VERSION "10.9.1"

NS_ :

BS_:

BU_: ADAS_Info AMP CPD DUMMY_DEBUG DUMMY_ECU EASC HUD MHU XGW_Info

BO_ 852 MHU_ADAS_req: 8 MHU
  SG_ MHU_FCW_Mode : 1|2@0+ (1,0) [0|3] "-" ADAS_Info
  SG_ MHU_FCW_sens : 3|2@0+ (1,0) [0|3] "-" ADAS_Info
  SG_ MHU_AEB_Mode : 7|2@0+ (1,0) [0|3] "-" ADAS_Info
  SG_ MHU_RAEB_Mode : 9|2@0+ (1,0) [0|3] "-" ADAS_Info
  SG_ MHU_LA_sens : 11|2@0+ (1,0) [0|3] "-" ADAS_Info
  SG_ MHU_LA_AudWarning : 15|2@0+ (1,0) [0|3] "-" ADAS_Info
  SG_ MHU_BSD_On : 17|2@0+ (1,0) [0|3] "-" ADAS_Info
  SG_ MHU_ALC_ON : 19|2@0+ (1,0) [0|3] "-" ADAS_Info
  SG_ MHU_BSD_AudWarning : 21|2@0+ (1,0) [0|3] "-" ADAS_Info
  SG_ MHU_RCTA_On : 23|2@0+ (1,0) [0|3] "-" ADAS_Info
  SG_ MHU_RCTA_sens : 25|2@0+ (1,0) [0|3] "-" ADAS_Info
  SG_ MHU_PA_On : 27|2@0+ (1,0) [0|3] "-" ADAS_Info
  SG_ MHU_AHB_On : 29|2@0+ (1,0) [0|3] "-" ADAS_Info
  SG_ MHU_IA_Mode : 31|2@0+ (1,0) [0|3] "-" ADAS_Info
  SG_ MHU_TSR_Mode : 33|2@0+ (1,0) [0|3] "-" ADAS_Info
  SG_ MHU_DOW_Mode : 35|2@0+ (1,0) [0|3] "-" ADAS_Info
  SG_ MHU_AHB_sens : 37|2@0+ (1,0) [0|3] "-" ADAS_Info
  SG_ MHU_LA_Mode : 41|3@0+ (1,0) [0|7] "-" ADAS_Info
  SG_ MHU_SET_TSR_AudWarn : 45|2@0+ (1,0) [0|3] "-" ADAS_Info
  SG_ MHU_SET_TSR_SLAert : 47|2@0+ (1,0) [0|3] "-" ADAS_Info

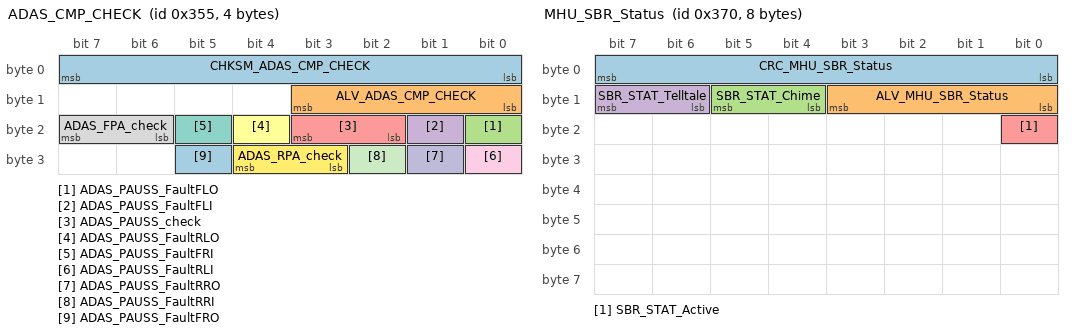
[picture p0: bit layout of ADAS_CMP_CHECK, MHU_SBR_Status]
BO_ 853 ADAS_CMP_CHECK: 4 ADAS_Info
  SG_ CHKSM_ADAS_CMP_CHECK : 7|8@0+ (1,0) [0|255] "" MHU
  SG_ ALV_ADAS_CMP_CHECK : 11|4@0+ (1,0) [0|14] "" MHU
  SG_ ADAS_PAUSS_FaultFLO : 16|1@0+ (1,0) [0|1] "-" MHU
  SG_ ADAS_PAUSS_FaultFLI : 17|1@0+ (1,0) [0|1] "-" MHU
  SG_ ADAS_PAUSS_check : 19|2@0+ (1,0) [0|3] "-" MHU
  SG_ ADAS_PAUSS_FaultRLO : 20|1@0+ (1,0) [0|1] "-" MHU
  SG_ ADAS_PAUSS_FaultFRI : 21|1@0+ (1,0) [0|1] "-" MHU
  SG_ ADAS_FPA_check : 23|2@0+ (1,0) [0|3] "-" MHU
  SG_ ADAS_PAUSS_FaultRLI : 24|1@0+ (1,0) [0|1] "-" MHU
  SG_ ADAS_PAUSS_FaultRRO : 25|1@0+ (1,0) [0|1] "-" MHU
  SG_ ADAS_PAUSS_FaultRRI : 26|1@0+ (1,0) [0|1] "-" MHU
  SG_ ADAS_RPA_check : 28|2@0+ (1,0) [0|3] "-" MHU
  SG_ ADAS_PAUSS_FaultFRO : 29|1@0+ (1,0) [0|1] "-" MHU

BO_ 880 MHU_SBR_Status: 8 MHU
  SG_ CRC_MHU_SBR_Status : 7|8@0+ (1,0) [0|255] "" XGW_Info
  SG_ ALV_MHU_SBR_Status : 11|4@0+ (1,0) [0|14] "" XGW_Info
  SG_ SBR_STAT_Chime : 13|2@0+ (1,0) [0|3] "" XGW_Info
  SG_ SBR_STAT_Telltale : 15|2@0+ (1,0) [0|3] "" XGW_Info
  SG_ SBR_STAT_Active : 16|1@0+ (1,0) [0|1] "" XGW_Info

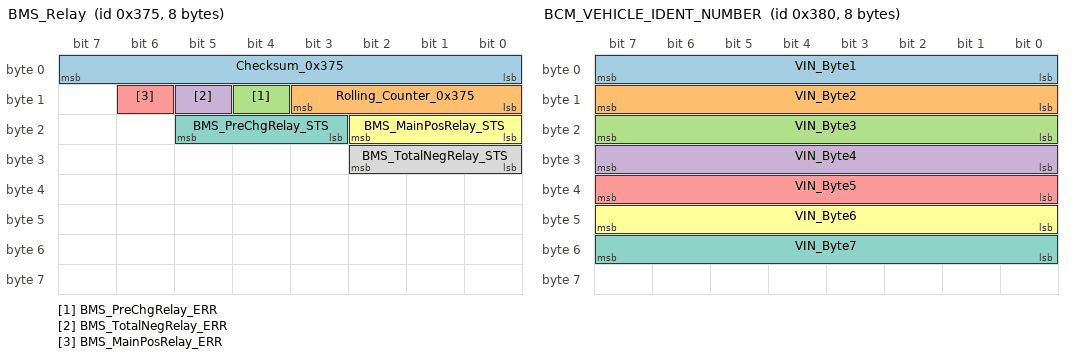
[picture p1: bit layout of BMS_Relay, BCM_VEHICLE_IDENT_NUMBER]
BO_ 885 BMS_Relay: 8 XGW_Info
  SG_ Checksum_0x375 : 7|8@0+ (1,0) [0|255] "" MHU
  SG_ Rolling_Counter_0x375 : 11|4@0+ (1,0) [0|14] "" MHU
  SG_ BMS_PreChgRelay_ERR : 12|1@0+ (1,0) [0|1] "" MHU
  SG_ BMS_TotalNegRelay_ERR : 13|1@0+ (1,0) [0|1] "" MHU
  SG_ BMS_MainPosRelay_ERR : 14|1@0+ (1,0) [0|1] "" MHU
  SG_ BMS_MainPosRelay_STS : 18|3@0+ (1,0) [0|7] "" MHU
  SG_ BMS_PreChgRelay_STS : 21|3@0+ (1,0) [0|7] "" MHU
  SG_ BMS_TotalNegRelay_STS : 26|3@0+ (1,0) [0|7] "" MHU

BO_ 896 BCM_VEHICLE_IDENT_NUMBER: 8 XGW_Info
  SG_ VIN_Byte1 : 7|8@0+ (1,0) [0|255] "" ADAS_Info,AMP,CPD,EASC,HUD,MHU
  SG_ VIN_Byte2 : 15|8@0+ (1,0) [0|255] "" ADAS_Info,AMP,CPD,EASC,HUD,MHU
  SG_ VIN_Byte3 : 23|8@0+ (1,0) [0|255] "" ADAS_Info,AMP,CPD,EASC,HUD,MHU
  SG_ VIN_Byte4 : 31|8@0+ (1,0) [0|255] "" ADAS_Info,AMP,CPD,EASC,HUD,MHU
  SG_ VIN_Byte5 : 39|8@0+ (1,0) [0|255] "" ADAS_Info,AMP,CPD,EASC,HUD,MHU
  SG_ VIN_Byte6 : 47|8@0+ (1,0) [0|255] "" ADAS_Info,AMP,CPD,EASC,HUD,MHU
  SG_ VIN_Byte7 : 55|8@0+ (1,0) [0|255] "" ADAS_Info,AMP,CPD,EASC,HUD,MHU

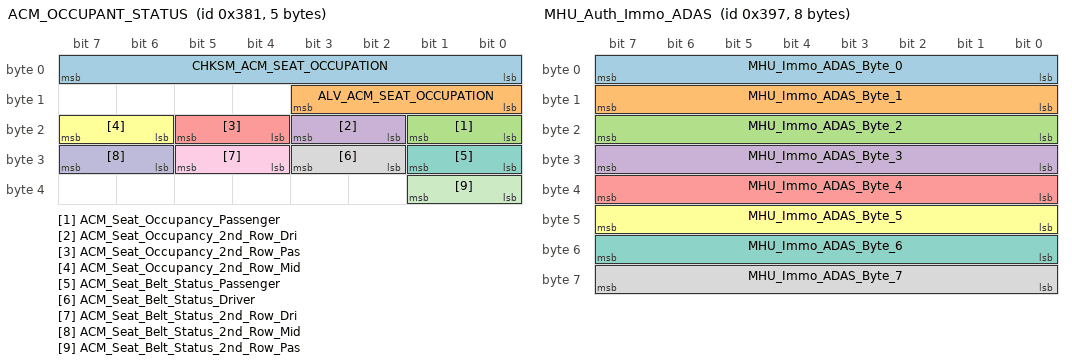
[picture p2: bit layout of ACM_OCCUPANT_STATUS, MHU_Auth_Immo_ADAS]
BO_ 897 ACM_OCCUPANT_STATUS: 5 XGW_Info
  SG_ CHKSM_ACM_SEAT_OCCUPATION : 7|8@0+ (1,0) [0|255] "" MHU
  SG_ ALV_ACM_SEAT_OCCUPATION : 11|4@0+ (1,0) [0|14] "" MHU
  SG_ ACM_Seat_Occupancy_Passenger : 17|2@0+ (1,0) [0|3] "" MHU
  SG_ ACM_Seat_Occupancy_2nd_Row_Dri : 19|2@0+ (1,0) [0|3] "" MHU
  SG_ ACM_Seat_Occupancy_2nd_Row_Pas : 21|2@0+ (1,0) [0|3] "-" MHU
  SG_ ACM_Seat_Occupancy_2nd_Row_Mid : 23|2@0+ (1,0) [0|3] "-" MHU
  SG_ ACM_Seat_Belt_Status_Passenger : 25|2@0+ (1,0) [0|3] "" MHU
  SG_ ACM_Seat_Belt_Status_Driver : 27|2@0+ (1,0) [0|3] "" MHU
  SG_ ACM_Seat_Belt_Status_2nd_Row_Dri : 29|2@0+ (1,0) [0|3] "-" MHU
  SG_ ACM_Seat_Belt_Status_2nd_Row_Mid : 31|2@0+ (1,0) [0|3] "" MHU
  SG_ ACM_Seat_Belt_Status_2nd_Row_Pas : 33|2@0+ (1,0) [0|3] "-" MHU

BO_ 905 VCU_Sts3: 8 XGW_Info
  SG_ VCU_IMMO_Sts : 35|2@0+ (1,0) [0|3] "" MHU
  SG_ SECCAN_VCU_IMMO_Sts : 63|8@0+ (1,0) [0|255] "" Vector__XXX

BO_ 915 MHU_HudPositionSetting: 3 MHU
  SG_ MHU_SET_HudRotateLvl : 7|4@0+ (1,0) [0|15] "-" HUD
  SG_ MHU_SET_HudHeightLvl : 15|5@0+ (1,0) [0|31] "-" HUD

BO_ 919 MHU_Auth_Immo_ADAS: 8 MHU
  SG_ MHU_Immo_ADAS_Byte_0 : 7|8@0+ (1,0) [0|255] "-" ADAS_Info
  SG_ MHU_Immo_ADAS_Byte_1 : 15|8@0+ (1,0) [0|255] "-" ADAS_Info
  SG_ MHU_Immo_ADAS_Byte_2 : 23|8@0+ (1,0) [0|255] "-" ADAS_Info
  SG_ MHU_Immo_ADAS_Byte_3 : 31|8@0+ (1,0) [0|255] "-" ADAS_Info
  SG_ MHU_Immo_ADAS_Byte_4 : 39|8@0+ (1,0) [0|255] "-" ADAS_Info
  SG_ MHU_Immo_ADAS_Byte_5 : 47|8@0+ (1,0) [0|255] "-" ADAS_Info
  SG_ MHU_Immo_ADAS_Byte_6 : 55|8@0+ (1,0) [0|255] "-" ADAS_Info
  SG_ MHU_Immo_ADAS_Byte_7 : 63|8@0+ (1,0) [0|255] "-" ADAS_Info

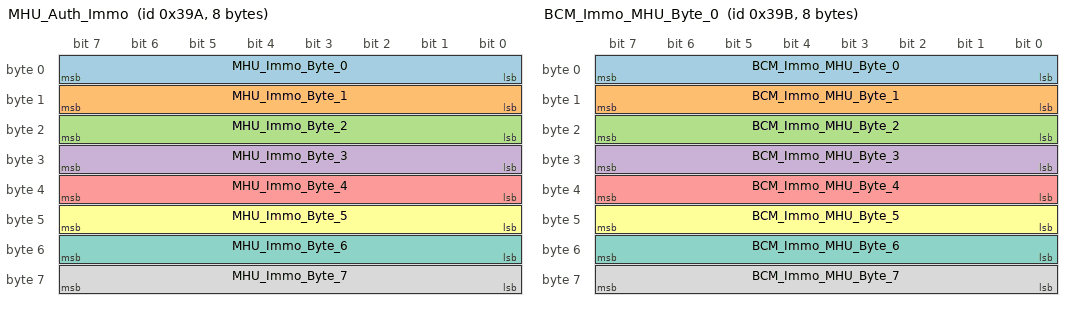
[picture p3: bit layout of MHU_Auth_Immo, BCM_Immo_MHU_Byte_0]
BO_ 922 MHU_Auth_Immo: 8 MHU
  SG_ MHU_Immo_Byte_0 : 7|8@0+ (1,0) [0|255] "-" XGW_Info
  SG_ MHU_Immo_Byte_1 : 15|8@0+ (1,0) [0|255] "-" XGW_Info
  SG_ MHU_Immo_Byte_2 : 23|8@0+ (1,0) [0|255] "" XGW_Info
  SG_ MHU_Immo_Byte_3 : 31|8@0+ (1,0) [0|255] "" XGW_Info
  SG_ MHU_Immo_Byte_4 : 39|8@0+ (1,0) [0|255] "" XGW_Info
  SG_ MHU_Immo_Byte_5 : 47|8@0+ (1,0) [0|255] "" XGW_Info
  SG_ MHU_Immo_Byte_6 : 55|8@0+ (1,0) [0|255] "" XGW_Info
  SG_ MHU_Immo_Byte_7 : 63|8@0+ (1,0) [0|255] "-" XGW_Info

BO_ 923 BCM_Immo_MHU_Byte_0: 8 XGW_Info
  SG_ BCM_Immo_MHU_Byte_0 : 7|8@0+ (1,0) [0|255] "-" MHU
  SG_ BCM_Immo_MHU_Byte_1 : 15|8@0+ (1,0) [0|255] "-" MHU
  SG_ BCM_Immo_MHU_Byte_2 : 23|8@0+ (1,0) [0|255] "-" MHU
  SG_ BCM_Immo_MHU_Byte_3 : 31|8@0+ (1,0) [0|255] "-" MHU
  SG_ BCM_Immo_MHU_Byte_4 : 39|8@0+ (1,0) [0|255] "-" MHU
  SG_ BCM_Immo_MHU_Byte_5 : 47|8@0+ (1,0) [0|255] "" MHU
  SG_ BCM_Immo_MHU_Byte_6 : 55|8@0+ (1,0) [0|255] "-" MHU
  SG_ BCM_Immo_MHU_Byte_7 : 63|8@0+ (1,0) [0|255] "-" MHU

BO_ 925 BCM_HighBeam_PosReq: 4 XGW_Info
  SG_ BCM_AHB_Override : 17|2@0+ (1,0) [0|3] "" MHU

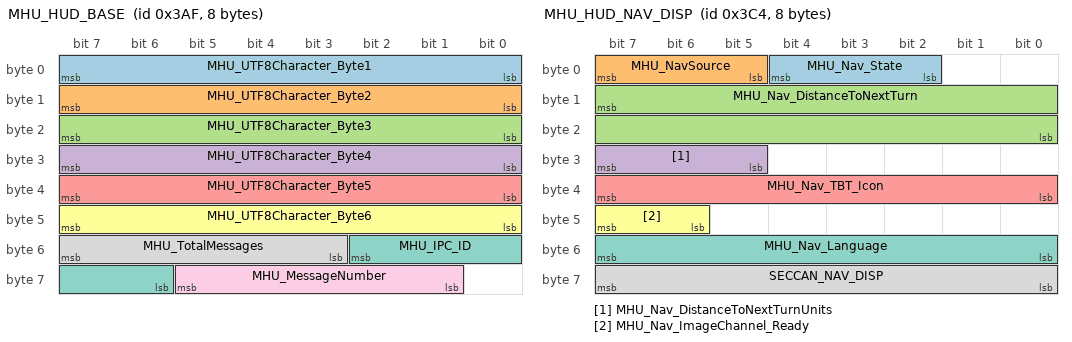
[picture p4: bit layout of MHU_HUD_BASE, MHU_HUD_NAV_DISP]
BO_ 943 MHU_HUD_BASE: 8 MHU
  SG_ MHU_UTF8Character_Byte1 : 7|8@0+ (1,0) [0|255] "-" HUD
  SG_ MHU_UTF8Character_Byte2 : 15|8@0+ (1,0) [0|255] "-" HUD
  SG_ MHU_UTF8Character_Byte3 : 23|8@0+ (1,0) [0|255] "-" HUD
  SG_ MHU_UTF8Character_Byte4 : 31|8@0+ (1,0) [0|255] "-" HUD
  SG_ MHU_UTF8Character_Byte5 : 39|8@0+ (1,0) [0|255] "-" HUD
  SG_ MHU_UTF8Character_Byte6 : 47|8@0+ (1,0) [0|255] "-" HUD
  SG_ MHU_IPC_ID : 50|5@0+ (1,0) [0|15] "Bit" HUD
  SG_ MHU_TotalMessages : 55|5@0+ (1,0) [0|31] "-" HUD
  SG_ MHU_MessageNumber : 61|5@0+ (1,0) [0|31] "-" HUD

BO_ 964 MHU_HUD_NAV_DISP: 8 MHU
  SG_ MHU_Nav_State : 4|3@0+ (1,0) [0|7] "-" HUD
  SG_ MHU_NavSource : 7|3@0+ (1,0) [0|7] "-" HUD
  SG_ MHU_Nav_DistanceToNextTurn : 15|16@0+ (1,0) [0|65535] "-" HUD
  SG_ MHU_Nav_DistanceToNextTurnUnits : 31|3@0+ (1,0) [0|7] "-" HUD
  SG_ MHU_Nav_TBT_Icon : 39|8@0+ (1,0) [0|255] "-" HUD
  SG_ MHU_Nav_ImageChannel_Ready : 47|2@0+ (1,0) [0|3] "-" HUD
  SG_ MHU_Nav_Language : 55|8@0+ (1,0) [0|255] "" HUD
  SG_ SECCAN_NAV_DISP : 63|8@0+ (1,0) [0|255] "" HUD

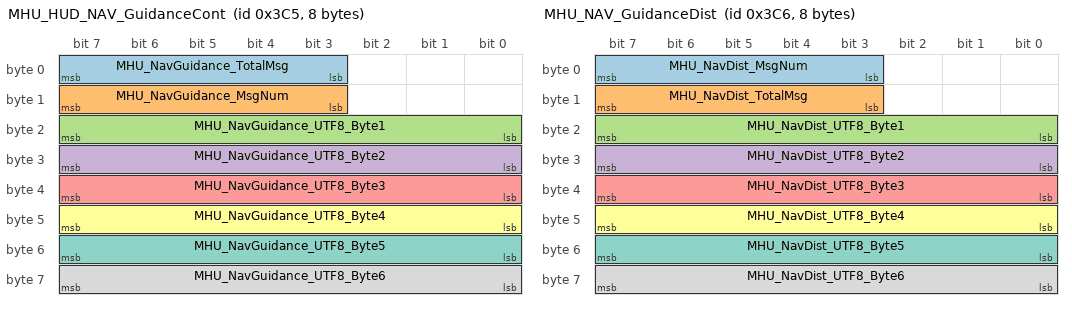
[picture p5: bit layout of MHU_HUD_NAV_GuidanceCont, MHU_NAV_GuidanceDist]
BO_ 965 MHU_HUD_NAV_GuidanceCont: 8 MHU
  SG_ MHU_NavGuidance_TotalMsg : 7|5@0+ (1,0) [0|31] "-" HUD
  SG_ MHU_NavGuidance_MsgNum : 15|5@0+ (1,0) [0|31] "-" HUD
  SG_ MHU_NavGuidance_UTF8_Byte1 : 23|8@0+ (1,0) [0|255] "" HUD
  SG_ MHU_NavGuidance_UTF8_Byte2 : 31|8@0+ (1,0) [0|255] "" HUD
  SG_ MHU_NavGuidance_UTF8_Byte3 : 39|8@0+ (1,0) [0|255] "" HUD
  SG_ MHU_NavGuidance_UTF8_Byte4 : 47|8@0+ (1,0) [0|255] "" HUD
  SG_ MHU_NavGuidance_UTF8_Byte5 : 55|8@0+ (1,0) [0|255] "" HUD
  SG_ MHU_NavGuidance_UTF8_Byte6 : 63|8@0+ (1,0) [0|255] "" HUD

BO_ 966 MHU_NAV_GuidanceDist: 8 MHU
  SG_ MHU_NavDist_MsgNum : 7|5@0+ (1,0) [0|31] "" HUD
  SG_ MHU_NavDist_TotalMsg : 15|5@0+ (1,0) [0|31] "" HUD
  SG_ MHU_NavDist_UTF8_Byte1 : 23|8@0+ (1,0) [0|255] "" HUD
  SG_ MHU_NavDist_UTF8_Byte2 : 31|8@0+ (1,0) [0|255] "" HUD
  SG_ MHU_NavDist_UTF8_Byte3 : 39|8@0+ (1,0) [0|255] "" HUD
  SG_ MHU_NavDist_UTF8_Byte4 : 47|8@0+ (1,0) [0|255] "" HUD
  SG_ MHU_NavDist_UTF8_Byte5 : 55|8@0+ (1,0) [0|255] "" HUD
  SG_ MHU_NavDist_UTF8_Byte6 : 63|8@0+ (1,0) [0|255] "" HUD

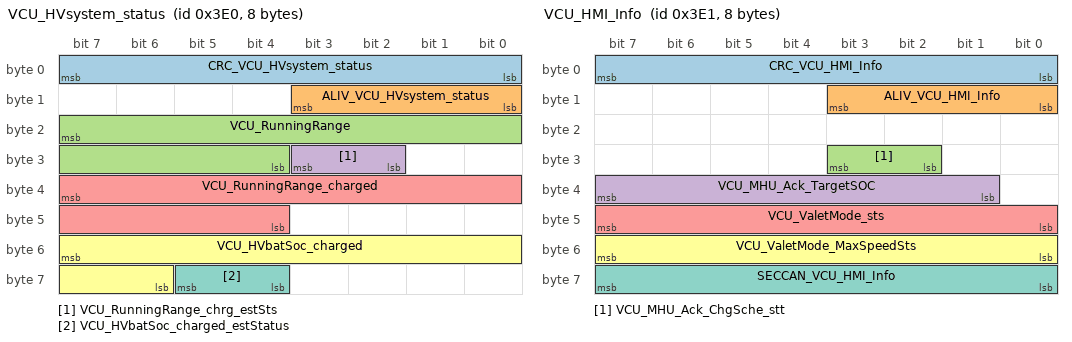
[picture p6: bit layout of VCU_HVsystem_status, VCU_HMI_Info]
BO_ 992 VCU_HVsystem_status: 8 XGW_Info
  SG_ CRC_VCU_HVsystem_status : 7|8@0+ (1,0) [0|255] "" HUD,MHU
  SG_ ALIV_VCU_HVsystem_status : 11|4@0+ (1,0) [0|14] "" HUD,MHU
  SG_ VCU_RunningRange : 23|12@0+ (0.5,0) [0|2047] "km" HUD,MHU
  SG_ VCU_RunningRange_chrg_estSts : 27|2@0+ (1,0) [0|3] "-" HUD,MHU
  SG_ VCU_RunningRange_charged : 39|12@0+ (0.5,0) [0|2047] "km" HUD,MHU
  SG_ VCU_HVbatSoc_charged : 55|10@0+ (0.1,0) [0|100] "%" HUD,MHU
  SG_ VCU_HVbatSoc_charged_estStatus : 61|2@0+ (1,0) [0|3] "-" HUD,MHU

BO_ 993 VCU_HMI_Info: 8 XGW_Info
  SG_ CRC_VCU_HMI_Info : 7|8@0+ (1,0) [0|255] "" MHU
  SG_ ALIV_VCU_HMI_Info : 11|4@0+ (1,0) [0|14] "" MHU
  SG_ VCU_MHU_Ack_ChgSche_stt : 27|2@0+ (1,0) [0|3] "" MHU
  SG_ VCU_MHU_Ack_TargetSOC : 39|7@0+ (1,0) [10|100] "%" MHU
  SG_ VCU_ValetMode_sts : 47|8@0+ (1,0) [0|255] "" MHU
  SG_ VCU_ValetMode_MaxSpeedSts : 55|8@0+ (1,0) [0|255] "km/h" MHU
  SG_ SECCAN_VCU_HMI_Info : 63|8@0+ (1,0) [0|255] "" MHU

BO_ 1015 MFS_Control_Button: 8 XGW_Info
  SG_ CHSKM_MFS_Control_Button : 7|8@0+ (1,0) [0|255] "" ADAS_Info,HUD,MHU
  SG_ ALV_MFS_Control_Button : 11|4@0+ (1,0) [0|14] "" ADAS_Info,HUD,MHU
  SG_ MFS_VoiceRecognitionOn_Off : 15|3@0+ (1,0) [0|4] "Bit" HUD,MHU
  SG_ MFS_ISAControl : 17|2@0+ (1,0) [0|3] "Bit" ADAS_Info,HUD,MHU
  SG_ MFS_CruiseSpeedIncrease : 20|3@0+ (1,0) [0|4] "Bit" ADAS_Info,HUD,MHU
  SG_ MFS_TelephoneCall_EndCall : 23|3@0+ (1,0) [0|4] "Bit" HUD,MHU
  SG_ MFS_LKAControl : 25|2@0+ (1,0) [0|3] "Bit" ADAS_Info,HUD,MHU
  SG_ MFS_CruiseGapIncrease : 28|3@0+ (1,0) [0|4] "Bit" ADAS_Info,HUD,MHU
  SG_ MFS_CruiseOn_Off : 31|3@0+ (1,0) [0|4] "Bit" ADAS_Info,HUD,MHU
  SG_ MFS_CruiseGapDecrease : 34|3@0+ (1,0) [0|4] "Bit" ADAS_Info,HUD,MHU
  SG_ MFS_CAN_RESControl : 36|2@0+ (1,0) [0|3] "-" ADAS_Info,HUD
  SG_ MFS_CruiseSpeedDecrease : 39|3@0+ (1,0) [0|4] "Bit" ADAS_Info,HUD,MHU
  SG_ MFS_M2Control : 41|2@0+ (1,0) [0|3] "Bit" ADAS_Info,HUD
  SG_ MFS_SourseControl : 44|3@0+ (1,0) [0|4] "Bit" HUD,MHU
  SG_ MFS_UpControl : 47|3@0+ (1,0) [0|4] "Bit" EASC,HUD,MHU
  SG_ MFS_DownControl : 52|3@0+ (1,0) [0|4] "Bit" EASC,HUD,MHU
  SG_ MFS_LeftControl : 55|3@0+ (1,0) [0|4] "Bit" EASC,HUD,MHU
  SG_ MFS_Failure : 57|1@0+ (1,0) [0|1] "Bit" ADAS_Info,HUD,MHU
  SG_ MFS_RightControl : 60|3@0+ (1,0) [0|4] "Bit" EASC,HUD,MHU
  SG_ MFS_OK_Control : 63|3@0+ (1,0) [0|4] "Bit" HUD,MHU

BO_ 1020 XGW_FOTA_StsConfirm: 4 XGW_Info
  SG_ CRC_XGW_FOTA_StsConfirm : 7|8@0+ (1,0) [0|255] "" MHU
  SG_ ALIV_XGW_FOTA_StsConfirm : 11|4@0+ (1,0) [0|14] "" MHU
  SG_ XGW_FOTA_StateConfirm : 15|4@0+ (1,0) [0|14] "-" MHU
  SG_ XGW_FOTA_Error_Code : 23|8@0+ (1,0) [0|255] "-" MHU

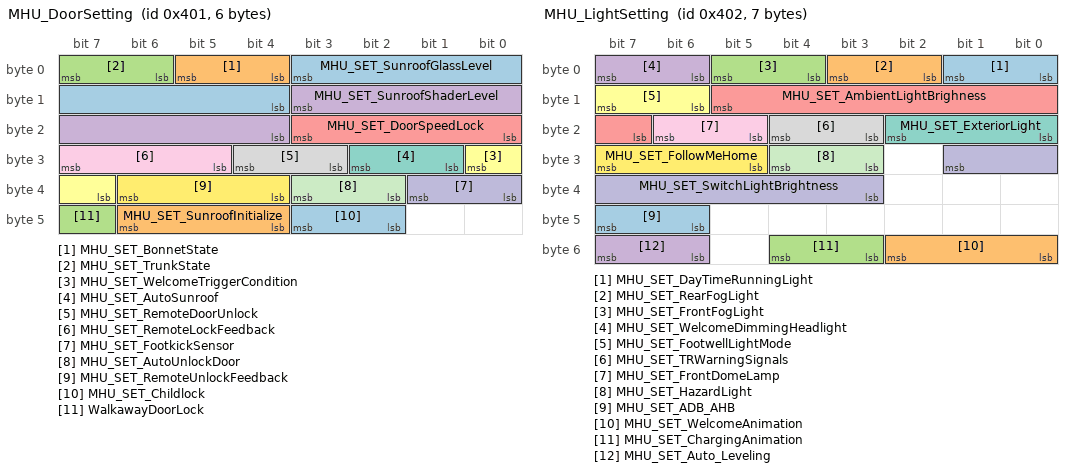
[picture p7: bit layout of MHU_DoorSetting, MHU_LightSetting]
BO_ 1025 MHU_DoorSetting: 6 MHU
  SG_ MHU_SET_SunroofGlassLevel : 3|8@0+ (1,0) [0|255] "%" XGW_Info
  SG_ MHU_SET_BonnetState : 5|2@0+ (1,0) [0|3] "-" XGW_Info
  SG_ MHU_SET_TrunkState : 7|2@0+ (1,0) [0|3] "-" XGW_Info
  SG_ MHU_SET_SunroofShaderLevel : 11|8@0+ (1,0) [0|255] "%" XGW_Info
  SG_ MHU_SET_DoorSpeedLock : 19|4@0+ (1,0) [0|7] "" XGW_Info
  SG_ MHU_SET_WelcomeTriggerCondition : 24|2@0+ (1,0) [0|3] "" XGW_Info
  SG_ MHU_SET_AutoSunroof : 26|2@0+ (1,0) [0|3] "" XGW_Info
  SG_ MHU_SET_RemoteDoorUnlock : 28|2@0+ (1,0) [0|3] "-" XGW_Info
  SG_ MHU_SET_RemoteLockFeedback : 31|3@0+ (1,0) [0|7] "-" XGW_Info
  SG_ MHU_SET_FootkickSensor : 33|2@0+ (1,0) [0|3] "-" XGW_Info
  SG_ MHU_SET_AutoUnlockDoor : 35|2@0+ (1,0) [0|3] "" XGW_Info
  SG_ MHU_SET_RemoteUnlockFeedback : 38|3@0+ (1,0) [0|7] "" XGW_Info
  SG_ MHU_SET_Childlock : 43|2@0+ (1,0) [0|3] "" XGW_Info
  SG_ MHU_SET_SunroofInitialize : 46|3@0+ (1,0) [0|7] "" XGW_Info
  SG_ WalkawayDoorLock : 47|1@0+ (1,0) [0|1] "" XGW_Info

BO_ 1026 MHU_LightSetting: 7 MHU
  SG_ MHU_SET_DayTimeRunningLight : 1|2@0+ (1,0) [0|3] "-" XGW_Info
  SG_ MHU_SET_RearFogLight : 3|2@0+ (1,0) [0|3] "" XGW_Info
  SG_ MHU_SET_FrontFogLight : 5|2@0+ (1,0) [0|3] "" XGW_Info
  SG_ MHU_SET_WelcomeDimmingHeadlight : 7|2@0+ (1,0) [0|3] "" XGW_Info
  SG_ MHU_SET_AmbientLightBrighness : 13|7@0+ (1,0) [0|100] "%" XGW_Info
  SG_ MHU_SET_FootwellLightMode : 15|2@0+ (1,0) [0|3] "-" XGW_Info
  SG_ MHU_SET_ExteriorLight : 18|3@0+ (1,0) [0|7] "" XGW_Info
  SG_ MHU_SET_TRWarningSignals : 20|2@0+ (1,0) [0|3] "" XGW_Info
  SG_ MHU_SET_FrontDomeLamp : 22|2@0+ (1,0) [0|3] "" XGW_Info
  SG_ MHU_SET_SwitchLightBrightness : 25|7@0+ (1,0) [0|100] "%" XGW_Info
  SG_ MHU_SET_HazardLight : 28|2@0+ (1,0) [0|3] "" XGW_Info
  SG_ MHU_SET_FollowMeHome : 31|3@0+ (1,0) [0|7] "" XGW_Info
  SG_ MHU_SET_ADB_AHB : 47|2@0+ (1,0) [0|3] "" XGW_Info
  SG_ MHU_SET_WelcomeAnimation : 50|3@0+ (1,0) [0|5] "" XGW_Info
  SG_ MHU_SET_ChargingAnimation : 52|2@0+ (1,0) [0|3] "" XGW_Info
  SG_ MHU_SET_Auto_Leveling : 55|2@0+ (1,0) [0|3] "-" XGW_Info

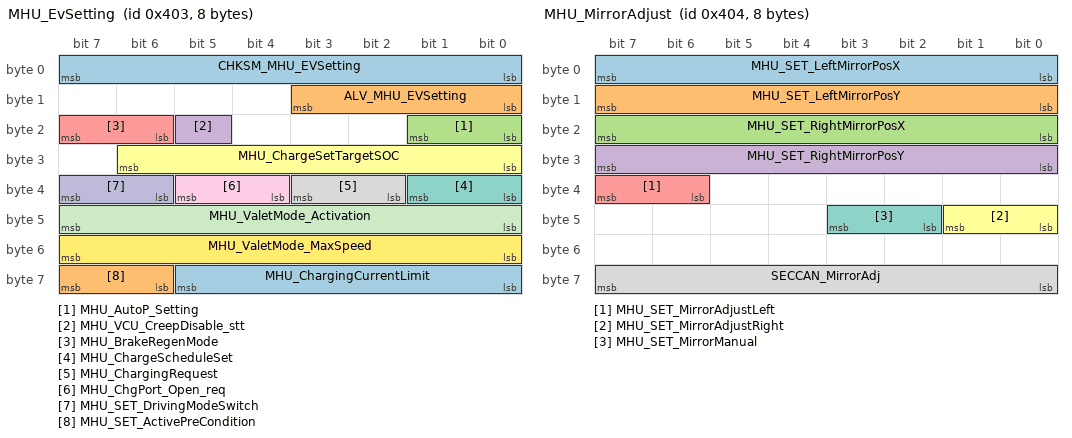
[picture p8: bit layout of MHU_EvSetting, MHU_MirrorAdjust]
BO_ 1027 MHU_EvSetting: 8 MHU
  SG_ CHKSM_MHU_EVSetting : 7|8@0+ (1,0) [0|255] "" XGW_Info
  SG_ ALV_MHU_EVSetting : 11|4@0+ (1,0) [0|14] "" XGW_Info
  SG_ MHU_AutoP_Setting : 17|2@0+ (1,0) [0|3] "" XGW_Info
  SG_ MHU_VCU_CreepDisable_stt : 21|1@0+ (1,0) [0|1] "" XGW_Info
  SG_ MHU_BrakeRegenMode : 23|2@0+ (1,0) [0|3] "" XGW_Info
  SG_ MHU_ChargeSetTargetSOC : 30|7@0+ (1,0) [10|100] "%" XGW_Info
  SG_ MHU_ChargeScheduleSet : 33|2@0+ (1,0) [0|3] "" XGW_Info
  SG_ MHU_ChargingRequest : 35|2@0+ (1,0) [0|3] "-" XGW_Info
  SG_ MHU_ChgPort_Open_req : 37|2@0+ (1,0) [0|3] "-" XGW_Info
  SG_ MHU_SET_DrivingModeSwitch : 39|2@0+ (1,0) [0|3] "-" XGW_Info
  SG_ MHU_ValetMode_Activation : 47|8@0+ (1,0) [0|255] "" ADAS_Info,XGW_Info
  SG_ MHU_ValetMode_MaxSpeed : 55|8@0+ (1,0) [0|255] "km/h" XGW_Info
  SG_ MHU_ChargingCurrentLimit : 61|6@0+ (1,0) [0|63] "A" XGW_Info
  SG_ MHU_SET_ActivePreCondition : 63|2@0+ (1,0) [0|3] "" XGW_Info

BO_ 1028 MHU_MirrorAdjust: 8 MHU
  SG_ MHU_SET_LeftMirrorPosX : 7|8@0+ (1,-15) [-15|15] "deg" XGW_Info
  SG_ MHU_SET_LeftMirrorPosY : 15|8@0+ (1,-15) [-15|15] "deg" XGW_Info
  SG_ MHU_SET_RightMirrorPosX : 23|8@0+ (1,-15) [-15|15] "deg" XGW_Info
  SG_ MHU_SET_RightMirrorPosY : 31|8@0+ (1,-15) [-15|15] "deg" XGW_Info
  SG_ MHU_SET_MirrorAdjustLeft : 39|2@0+ (1,0) [0|3] "-" XGW_Info
  SG_ MHU_SET_MirrorAdjustRight : 41|2@0+ (1,0) [0|3] "-" XGW_Info
  SG_ MHU_SET_MirrorManual : 43|2@0+ (1,0) [0|3] "" XGW_Info
  SG_ SECCAN_MirrorAdj : 63|8@0+ (1,0) [0|255] "" XGW_Info

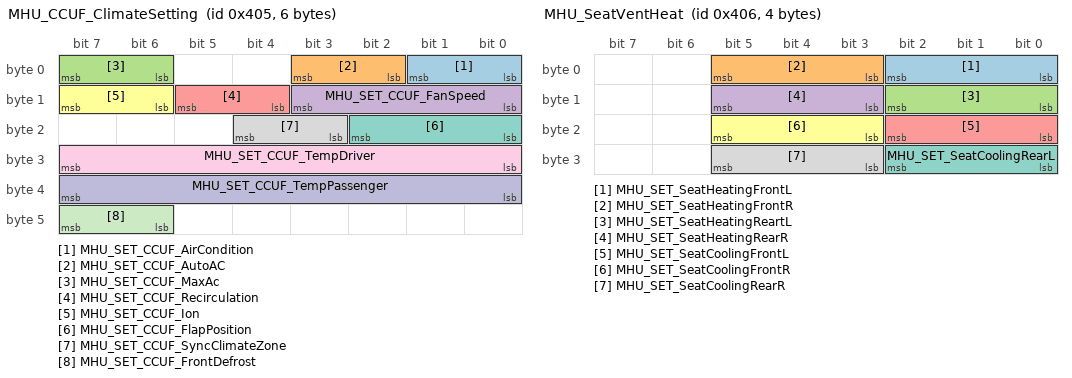
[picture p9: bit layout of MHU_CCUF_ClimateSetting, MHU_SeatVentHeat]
BO_ 1029 MHU_CCUF_ClimateSetting: 6 MHU
  SG_ MHU_SET_CCUF_AirCondition : 1|2@0+ (1,0) [0|3] "" XGW_Info
  SG_ MHU_SET_CCUF_AutoAC : 3|2@0+ (1,0) [0|3] "" XGW_Info
  SG_ MHU_SET_CCUF_MaxAc : 7|2@0+ (1,0) [0|3] "" XGW_Info
  SG_ MHU_SET_CCUF_FanSpeed : 11|4@0+ (1,0) [0|7] "-" XGW_Info
  SG_ MHU_SET_CCUF_Recirculation : 13|2@0+ (1,0) [0|3] "" XGW_Info
  SG_ MHU_SET_CCUF_Ion : 15|2@0+ (1,0) [0|3] "-" XGW_Info
  SG_ MHU_SET_CCUF_FlapPosition : 18|3@0+ (1,0) [0|7] "-" XGW_Info
  SG_ MHU_SET_CCUF_SyncClimateZone : 20|2@0+ (1,0) [0|3] "-" XGW_Info
  SG_ MHU_SET_CCUF_TempDriver : 31|8@0+ (0.5,0) [16|32] "Degree C" XGW_Info
  SG_ MHU_SET_CCUF_TempPassenger : 39|8@0+ (0.5,0) [16|32] "Degree C" XGW_Info
  SG_ MHU_SET_CCUF_FrontDefrost : 47|2@0+ (1,0) [0|3] "" XGW_Info

BO_ 1030 MHU_SeatVentHeat: 4 MHU
  SG_ MHU_SET_SeatHeatingFrontL : 2|3@0+ (1,0) [0|7] "-" XGW_Info
  SG_ MHU_SET_SeatHeatingFrontR : 5|3@0+ (1,0) [0|7] "-" XGW_Info
  SG_ MHU_SET_SeatHeatingReartL : 10|3@0+ (1,0) [0|7] "-" XGW_Info
  SG_ MHU_SET_SeatHeatingRearR : 13|3@0+ (1,0) [0|7] "-" XGW_Info
  SG_ MHU_SET_SeatCoolingFrontL : 18|3@0+ (1,0) [0|7] "-" XGW_Info
  SG_ MHU_SET_SeatCoolingFrontR : 21|3@0+ (1,0) [0|7] "" XGW_Info
  SG_ MHU_SET_SeatCoolingRearL : 26|3@0+ (1,0) [0|7] "" XGW_Info
  SG_ MHU_SET_SeatCoolingRearR : 29|3@0+ (1,0) [0|7] "-" XGW_Info

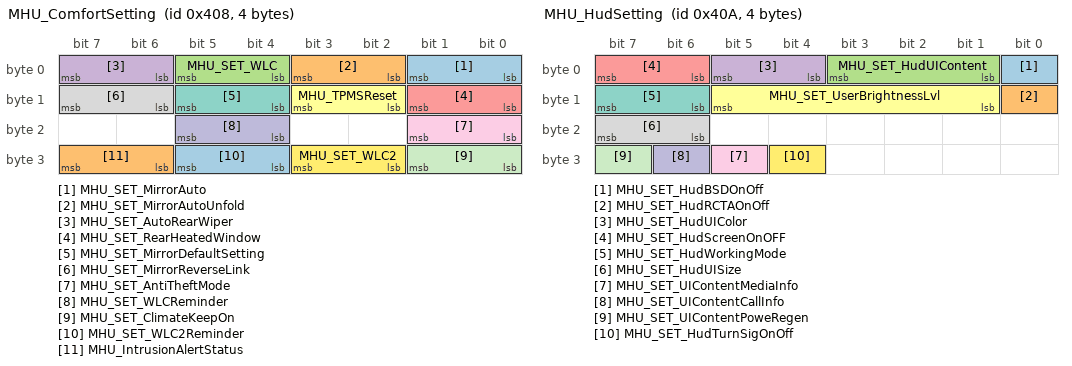
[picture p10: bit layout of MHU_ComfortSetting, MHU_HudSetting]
BO_ 1032 MHU_ComfortSetting: 4 MHU
  SG_ MHU_SET_MirrorAuto : 1|2@0+ (1,0) [0|3] "" XGW_Info
  SG_ MHU_SET_MirrorAutoUnfold : 3|2@0+ (1,0) [0|3] "" XGW_Info
  SG_ MHU_SET_WLC : 5|2@0+ (1,0) [0|3] "-" XGW_Info
  SG_ MHU_SET_AutoRearWiper : 7|2@0+ (1,0) [0|3] "-" XGW_Info
  SG_ MHU_SET_RearHeatedWindow : 9|2@0+ (1,0) [0|3] "" XGW_Info
  SG_ MHU_TPMSReset : 11|2@0+ (1,0) [0|3] "" XGW_Info
  SG_ MHU_SET_MirrorDefaultSetting : 13|2@0+ (1,0) [0|3] "" XGW_Info
  SG_ MHU_SET_MirrorReverseLink : 15|2@0+ (1,0) [0|3] "-" XGW_Info
  SG_ MHU_SET_AntiTheftMode : 17|2@0+ (1,0) [0|3] "" XGW_Info
  SG_ MHU_SET_WLCReminder : 21|2@0+ (1,0) [0|3] "" XGW_Info
  SG_ MHU_SET_ClimateKeepOn : 25|2@0+ (1,0) [0|3] "" XGW_Info
  SG_ MHU_SET_WLC2 : 27|2@0+ (1,0) [0|3] "-" XGW_Info
  SG_ MHU_SET_WLC2Reminder : 29|2@0+ (1,0) [0|3] "-" XGW_Info
  SG_ MHU_IntrusionAlertStatus : 31|2@0+ (1,0) [0|3] "-" XGW_Info

BO_ 1033 ADAS_WarnMsg: 8 ADAS_Info
  SG_ CHSKM_ADAS_WarnMsg : 7|8@0+ (1,0) [0|255] "" MHU
  SG_ ALV_ADAS_WarnMsg : 11|4@0+ (1,0) [0|14] "" MHU
  SG_ ADAS_Warning_Flag_1 : 12|1@0+ (1,0) [0|1] "" MHU
  SG_ ADAS_Warning_Flag_2 : 13|1@0+ (1,0) [0|1] "" MHU
  SG_ ADAS_Warning_Flag_3 : 14|1@0+ (1,0) [0|1] "" MHU
  SG_ ADAS_Warning_Flag_4 : 15|1@0+ (1,0) [0|1] "" MHU
  SG_ ADAS_Warning_Flag_5 : 16|1@0+ (1,0) [0|1] "" MHU
  SG_ ADAS_Warning_Flag_6 : 17|1@0+ (1,0) [0|1] "" MHU
  SG_ ADAS_Warning_Flag_7 : 18|1@0+ (1,0) [0|1] "" MHU
  SG_ ADAS_Warning_Flag_8 : 19|1@0+ (1,0) [0|1] "" MHU
  SG_ ADAS_Warning_Flag_9 : 20|1@0+ (1,0) [0|1] "" MHU
  SG_ ADAS_Warning_Flag_10 : 21|1@0+ (1,0) [0|1] "" MHU
  SG_ ADAS_Warning_Flag_11 : 22|1@0+ (1,0) [0|1] "" MHU
  SG_ ADAS_Warning_Flag_12 : 23|1@0+ (1,0) [0|1] "" MHU
  SG_ ADAS_Warning_Flag_13 : 24|1@0+ (1,0) [0|1] "" MHU
  SG_ ADAS_Warning_Flag_14 : 25|1@0+ (1,0) [0|1] "" MHU
  SG_ ADAS_Warning_Flag_15 : 26|1@0+ (1,0) [0|1] "" MHU
  SG_ ADAS_Warning_Flag_16 : 27|1@0+ (1,0) [0|1] "" MHU
  SG_ ADAS_Warning_Flag_17 : 28|1@0+ (1,0) [0|1] "" MHU
  SG_ ADAS_Warning_Flag_18 : 29|1@0+ (1,0) [0|1] "" MHU
  SG_ ADAS_Warning_Flag_19 : 30|1@0+ (1,0) [0|1] "" MHU
  SG_ ADAS_Warning_Flag_20 : 31|1@0+ (1,0) [0|1] "" MHU
  SG_ ADAS_Warning_Flag_21 : 32|1@0+ (1,0) [0|1] "" MHU
  SG_ ADAS_Warning_Flag_22 : 33|1@0+ (1,0) [0|1] "" MHU
  SG_ ADAS_Warning_Flag_23 : 34|1@0+ (1,0) [0|1] "" MHU
  SG_ ADAS_Warning_Flag_24 : 35|1@0+ (1,0) [0|1] "" MHU
  SG_ ADAS_Warning_Flag_25 : 36|1@0+ (1,0) [0|1] "" MHU
  SG_ ADAS_Warning_Flag_26 : 37|1@0+ (1,0) [0|1] "" MHU
  SG_ ADAS_Warning_Flag_27 : 38|1@0+ (1,0) [0|1] "" MHU
  SG_ ADAS_Warning_Flag_28 : 39|1@0+ (1,0) [0|1] "" MHU
  SG_ ADAS_Warning_Flag_29 : 40|1@0+ (1,0) [0|1] "" MHU
  SG_ ADAS_Warning_Flag_30 : 41|1@0+ (1,0) [0|1] "" MHU
  SG_ ADAS_Warning_Flag_31 : 42|1@0+ (1,0) [0|1] "" MHU
  SG_ ADAS_Warning_Flag_32 : 43|1@0+ (1,0) [0|1] "" MHU
  SG_ ADAS_Warning_Flag_33 : 44|1@0+ (1,0) [0|1] "" MHU
  SG_ ADAS_Warning_Flag_34 : 45|1@0+ (1,0) [0|1] "" MHU
  SG_ ADAS_Warning_Flag_35 : 46|1@0+ (1,0) [0|1] "" MHU
  SG_ ADAS_Warning_Flag_36 : 47|1@0+ (1,0) [0|1] "" MHU
  SG_ ADAS_Warning_Flag_37 : 48|1@0+ (1,0) [0|1] "" MHU
  SG_ ADAS_Warning_Flag_38 : 49|1@0+ (1,0) [0|1] "" MHU
  SG_ ADAS_Warning_Flag_39 : 50|1@0+ (1,0) [0|1] "" MHU
  SG_ ADAS_Warning_Flag_40 : 51|1@0+ (1,0) [0|1] "" MHU
  SG_ ADAS_Warning_Flag_41 : 52|1@0+ (1,0) [0|1] "" MHU
  SG_ ADAS_Warning_Flag_42 : 53|1@0+ (1,0) [0|1] "" MHU
  SG_ ADAS_Warning_Flag_43 : 54|1@0+ (1,0) [0|1] "" MHU
  SG_ ADAS_Warning_Flag_44 : 55|1@0+ (1,0) [0|1] "" MHU
  SG_ ADAS_Warning_Flag_45 : 56|1@0+ (1,0) [0|1] "" MHU
  SG_ ADAS_Warning_Flag_46 : 57|1@0+ (1,0) [0|1] "" MHU
  SG_ ADAS_Warning_Flag_47 : 58|1@0+ (1,0) [0|1] "" MHU
  SG_ ADAS_Warning_Flag_48 : 59|1@0+ (1,0) [0|1] "" MHU
  SG_ ADAS_Warning_Flag_49 : 60|1@0+ (1,0) [0|1] "" MHU
  SG_ ADAS_Warning_Flag_50 : 61|1@0+ (1,0) [0|1] "" MHU
  SG_ ADAS_Warning_Flag_51 : 62|1@0+ (1,0) [0|1] "" MHU
  SG_ ADAS_Warning_Flag_52 : 63|1@0+ (1,0) [0|1] "" MHU

BO_ 1034 MHU_HudSetting: 4 MHU
  SG_ MHU_SET_HudBSDOnOff : 0|1@0+ (1,0) [0|1] "" HUD
  SG_ MHU_SET_HudRCTAOnOff : 8|1@0+ (1,0) [0|1] "" HUD
  SG_ MHU_SET_HudUIContent : 3|3@0+ (1,0) [0|7] "-" HUD
  SG_ MHU_SET_HudUIColor : 5|2@0+ (1,0) [0|3] "-" HUD
  SG_ MHU_SET_HudScreenOnOFF : 7|2@0+ (1,0) [0|3] "-" HUD
  SG_ MHU_SET_UserBrightnessLvl : 13|5@0+ (1,0) [0|31] "-" HUD
  SG_ MHU_SET_HudWorkingMode : 15|2@0+ (1,0) [0|3] "-" HUD
  SG_ MHU_SET_HudUISize : 23|2@0+ (1,0) [0|3] "-" HUD
  SG_ MHU_SET_UIContentMediaInfo : 29|1@0+ (1,0) [0|1] "" HUD
  SG_ MHU_SET_UIContentCallInfo : 30|1@0+ (1,0) [0|1] "" HUD
  SG_ MHU_SET_UIContentPoweRegen : 31|1@0+ (1,0) [0|1] "" HUD
  SG_ MHU_SET_HudTurnSigOnOff : 28|1@0+ (1,0) [0|1] "" HUD

BO_ 1035 MHU_Avas_Setting: 1 MHU
  SG_ MHU_SET_AvasSound : 1|2@0+ (1,0) [0|3] "-" XGW_Info

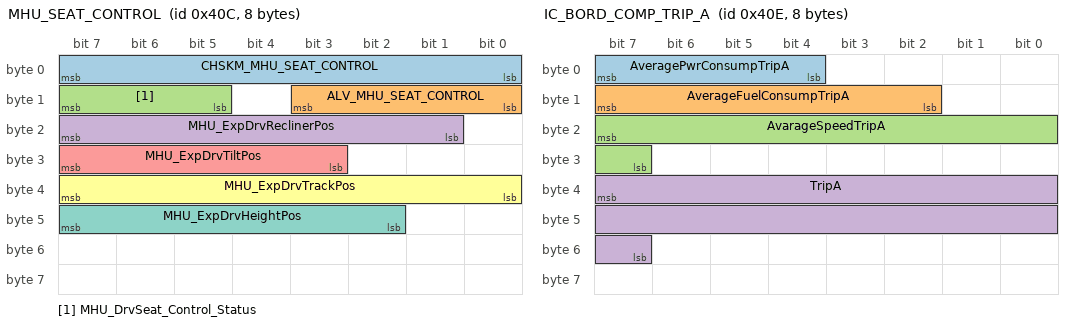
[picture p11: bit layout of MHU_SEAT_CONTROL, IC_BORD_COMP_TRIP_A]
BO_ 1036 MHU_SEAT_CONTROL: 8 MHU
  SG_ CHSKM_MHU_SEAT_CONTROL : 7|8@0+ (1,0) [0|255] "" XGW_Info
  SG_ ALV_MHU_SEAT_CONTROL : 11|4@0+ (1,0) [0|14] "" XGW_Info
  SG_ MHU_DrvSeat_Control_Status : 15|3@0+ (1,0) [0|7] "-" XGW_Info
  SG_ MHU_ExpDrvReclinerPos : 23|7@0+ (1,0) [0|127] "degree" XGW_Info
  SG_ MHU_ExpDrvTiltPos : 31|5@0+ (1,0) [0|31] "mm" XGW_Info
  SG_ MHU_ExpDrvTrackPos : 39|8@0+ (1,0) [0|255] "mm" XGW_Info
  SG_ MHU_ExpDrvHeightPos : 47|6@0+ (1,0) [0|63] "mm" XGW_Info

BO_ 1037 MHU_DIGIT_SPEED: 5 MHU
  SG_ CHKSM_MHU_DIGIT_SPEED : 7|8@0+ (1,0) [0|255] "" ADAS_Info,HUD,XGW_Info
  SG_ ALV_MHU_DIGIT_SPEED : 11|4@0+ (1,0) [0|14] "" ADAS_Info,HUD,XGW_Info
  SG_ MHU_DigitSpeed : 23|9@0+ (1,0) [0|300] "km/h" ADAS_Info,HUD,XGW_Info

BO_ 1038 IC_BORD_COMP_TRIP_A: 8 MHU
  SG_ AveragePwrConsumpTripA : 7|4@0+ (1,0) [0|10] "km/kWh" DUMMY_DEBUG,XGW_Info
  SG_ AverageFuelConsumpTripA : 15|6@0+ (1,0) [0|51] "l/100Km" DUMMY_DEBUG,XGW_Info
  SG_ AvarageSpeedTripA : 23|9@0+ (1,0) [0|300] "kmh" DUMMY_DEBUG,XGW_Info
  SG_ TripA : 39|17@0+ (0.1,0) [0|9999.9] "km" DUMMY_DEBUG,XGW_Info

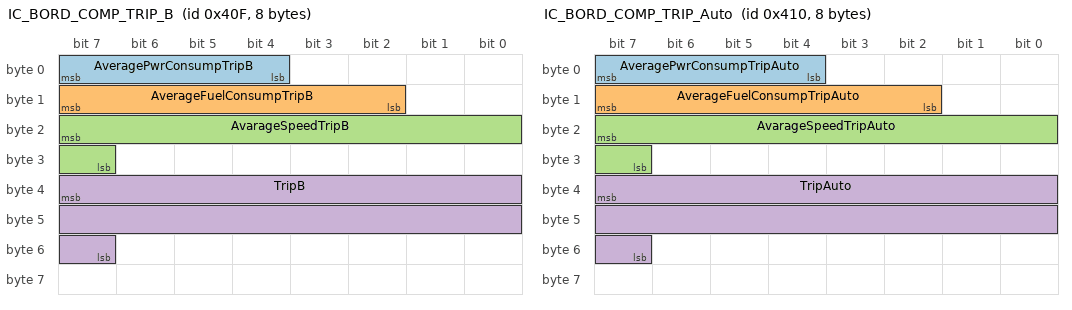
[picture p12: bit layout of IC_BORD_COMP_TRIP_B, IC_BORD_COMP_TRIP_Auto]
BO_ 1039 IC_BORD_COMP_TRIP_B: 8 MHU
  SG_ AveragePwrConsumpTripB : 7|4@0+ (1,0) [0|10] "km/kWh" DUMMY_DEBUG,XGW_Info
  SG_ AverageFuelConsumpTripB : 15|6@0+ (1,0) [0|51] "l/100Km" DUMMY_DEBUG,XGW_Info
  SG_ AvarageSpeedTripB : 23|9@0+ (1,0) [0|300] "kmh" DUMMY_DEBUG,XGW_Info
  SG_ TripB : 39|17@0+ (0.1,0) [0|9999.9] "km" DUMMY_DEBUG,XGW_Info

BO_ 1040 IC_BORD_COMP_TRIP_Auto: 8 MHU
  SG_ AveragePwrConsumpTripAuto : 7|4@0+ (1,0) [0|10] "km/kWh" DUMMY_DEBUG,XGW_Info
  SG_ AverageFuelConsumpTripAuto : 15|6@0+ (1,0) [0|51] "l/100Km" DUMMY_DEBUG,XGW_Info
  SG_ AvarageSpeedTripAuto : 23|9@0+ (1,0) [0|300] "kmh" DUMMY_DEBUG,XGW_Info
  SG_ TripAuto : 39|17@0+ (0.1,0) [0|9999.9] "km" DUMMY_DEBUG,XGW_Info

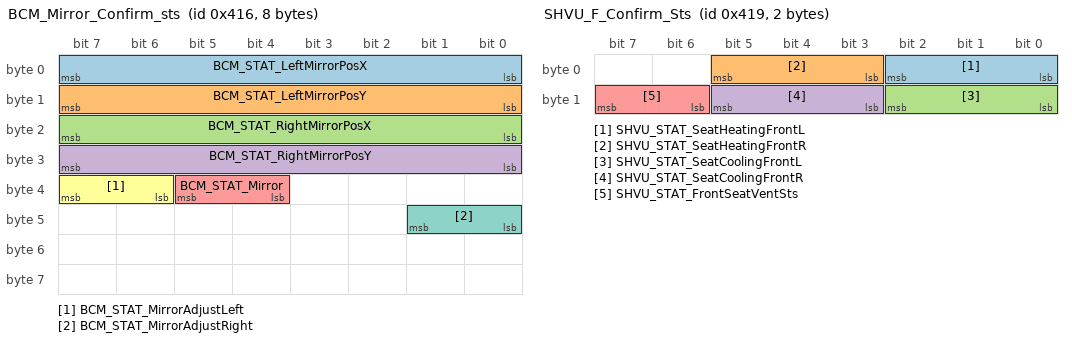
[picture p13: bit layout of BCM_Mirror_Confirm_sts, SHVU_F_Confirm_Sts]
BO_ 1046 BCM_Mirror_Confirm_sts: 8 XGW_Info
  SG_ BCM_STAT_LeftMirrorPosX : 7|8@0+ (1,-15) [-15|15] "deg" MHU
  SG_ BCM_STAT_LeftMirrorPosY : 15|8@0+ (1,-15) [-15|15] "deg" MHU
  SG_ BCM_STAT_RightMirrorPosX : 23|8@0+ (1,-15) [-15|15] "deg" MHU
  SG_ BCM_STAT_RightMirrorPosY : 31|8@0+ (1,-15) [-15|15] "deg" MHU
  SG_ BCM_STAT_Mirror : 37|2@0+ (1,0) [0|3] "" MHU
  SG_ BCM_STAT_MirrorAdjustLeft : 39|2@0+ (1,0) [0|3] "-" MHU
  SG_ BCM_STAT_MirrorAdjustRight : 41|2@0+ (1,0) [0|3] "" MHU

BO_ 1049 SHVU_F_Confirm_Sts: 2 XGW_Info
  SG_ SHVU_STAT_SeatHeatingFrontL : 2|3@0+ (1,0) [0|7] "-" MHU
  SG_ SHVU_STAT_SeatHeatingFrontR : 5|3@0+ (1,0) [0|7] "-" MHU
  SG_ SHVU_STAT_SeatCoolingFrontL : 10|3@0+ (1,0) [0|7] "-" MHU
  SG_ SHVU_STAT_SeatCoolingFrontR : 13|3@0+ (1,0) [0|7] "" MHU
  SG_ SHVU_STAT_FrontSeatVentSts : 15|2@0+ (1,0) [0|3] "" MHU

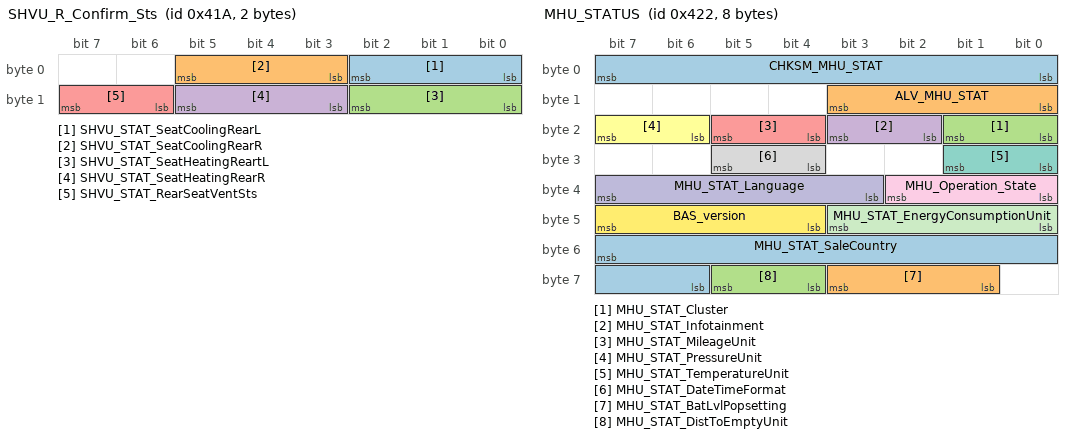
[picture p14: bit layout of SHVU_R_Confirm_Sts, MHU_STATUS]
BO_ 1050 SHVU_R_Confirm_Sts: 2 XGW_Info
  SG_ SHVU_STAT_SeatCoolingRearL : 2|3@0+ (1,0) [0|7] "-" MHU
  SG_ SHVU_STAT_SeatCoolingRearR : 5|3@0+ (1,0) [0|7] "" MHU
  SG_ SHVU_STAT_SeatHeatingReartL : 10|3@0+ (1,0) [0|7] "" MHU
  SG_ SHVU_STAT_SeatHeatingRearR : 13|3@0+ (1,0) [0|7] "" MHU
  SG_ SHVU_STAT_RearSeatVentSts : 15|2@0+ (1,0) [0|3] "" MHU

BO_ 1052 PSM_SEAT_POSITION: 3 XGW_Info
  SG_ CHKSM_PSM_SEAT_POSITION : 7|8@0+ (1,0) [0|255] "" MHU
  SG_ AVL_PSM_SEAT_POSITION : 11|4@0+ (1,0) [0|14] "-" MHU
  SG_ PSM_Seat_track_pos_Dri : 19|2@0+ (1,0) [0|3] "" MHU
  SG_ PSM_Seat_track_posPas : 21|2@0+ (1,0) [0|3] "" MHU

BO_ 1053 BCM_Comfort_Confirm_sts: 8 XGW_Info
  SG_ BCM_STAT_AutoRearWiper : 1|2@0+ (1,0) [0|3] "-" MHU
  SG_ BCM_STAT_MirrorFoldSetting : 3|2@0+ (1,0) [0|3] "" MHU
  SG_ BCM_STAT_IMMO_KeyfobID2 : 7|3@0+ (1,0) [0|7] "" MHU
  SG_ BCM_STAT_MirrorAutoUnfold : 9|2@0+ (1,0) [0|3] "-" MHU
  SG_ BCM_STAT_MirrorReverseLink : 11|2@0+ (1,0) [0|3] "" MHU
  SG_ BCM_STAT_MirrorDefaultSTATting : 13|2@0+ (1,0) [0|3] "-" MHU
  SG_ BCM_STAT_WelcomeTriggerCondition : 15|2@0+ (1,0) [0|3] "" MHU
  SG_ BCM_STAT_FrontDomeLamp : 17|2@0+ (1,0) [0|3] "-" MHU
  SG_ BCM_STAT_FollowMeHome : 20|3@0+ (1,0) [0|7] "-" MHU
  SG_ BCM_STAT_ExteriorLight : 23|3@0+ (1,0) [0|7] "-" MHU
  SG_ BCM_STAT_RemoteLockFeedback : 26|3@0+ (1,0) [0|7] "-" MHU
  SG_ BCM_STAT_RemoteDoorUnlock : 28|2@0+ (1,0) [0|3] "" MHU
  SG_ BCM_STAT_AutoDoorUnlock : 30|2@0+ (1,0) [0|3] "" MHU
  SG_ BCM_STAT_WalkawayDoorLock : 31|1@0+ (1,0) [0|1] "" MHU
  SG_ BCM_STAT_AmbientLightBrighness : 39|7@0+ (1,0) [0|100] "%" MHU
  SG_ BCM_STAT_WiperServiceMode : 42|2@0+ (1,0) [0|3] "" MHU
  SG_ BCM_STAT_IMMO_KeyfobID : 45|2@0+ (1,0) [0|3] "" MHU
  SG_ BCM_STAT_RearHeatedWindowMirror : 47|2@0+ (1,0) [0|3] "" MHU
  SG_ BCM_STAT_AntiTheftMode : 50|3@0+ (1,0) [0|7] "-" MHU
  SG_ BCM_STAT_ClimateKeepOnSts : 53|2@0+ (1,0) [0|3] "" MHU
  SG_ BCM_STAT_FKSfeedback : 55|2@0+ (1,0) [0|3] "" MHU
  SG_ SECCAN_CmftCnfrm : 63|8@0+ (1,0) [0|255] "" MHU

BO_ 1054 HUD_State: 8 HUD
  SG_ HUD_BSDOnOff_Feed : 0|1@0+ (1,0) [0|1] "-" MHU
  SG_ HUD_RCTAOnOff_Feed : 8|1@0+ (1,0) [0|1] "-" MHU
  SG_ HUD_UIColor : 2|2@0+ (1,0) [0|3] "-" MHU
  SG_ HUD_UIContent : 5|3@0+ (1,0) [0|7] "-" MHU
  SG_ HUD_OperationState : 7|2@0+ (1,0) [0|3] "-" MHU
  SG_ HUD_HeightLvl : 13|5@0+ (1,0) [0|31] "-" MHU
  SG_ HUD_UI_Size : 15|2@0+ (1,0) [0|3] "-" MHU
  SG_ HUD_UIContentMediaInfo : 16|1@0+ (1,0) [0|1] "" MHU
  SG_ HUD_UIContentCallInfor : 17|1@0+ (1,0) [0|1] "" MHU
  SG_ HUD_UIContentPowerRegen : 18|1@0+ (1,0) [0|1] "" MHU
  SG_ HUD_UIModeSignal : 21|3@0+ (1,0) [0|7] "-" MHU
  SG_ HUD_WorkingMode : 23|2@0+ (1,0) [0|3] "-" MHU
  SG_ HUD_ActualBrightnes : 31|14@0+ (1,0) [0|12000] "cd/m2" MHU
  SG_ HUD_RotateAngleLvl : 42|4@0+ (1,0) [0|15] "-" MHU
  SG_ HUD_UserSetBrightnessLvl : 47|5@0+ (1,0) [0|31] "-" MHU
  SG_ HUD_Language : 54|5@0+ (1,0) [0|31] "-" MHU
  SG_ HUD_TurnSigOnOff_Feed : 56|1@0+ (1,0) [0|1] "-" MHU
  SG_ HUD_Mileage_Unit : 57|1@0+ (1,0) [0|1] "-" MHU
  SG_ HUD_UserProfileId : 61|4@0+ (1,0) [0|15] "-" MHU
  SG_ HUD_DimmingDelayTime : 63|2@0+ (1,0) [0|3] "-" MHU

BO_ 1055 Sensor_Fault: 8 ADAS_Info
  SG_ CHKSM_SensorFault : 7|8@0+ (1,0) [0|255] "" MHU
  SG_ ALV_Sensor_Fault : 11|4@0+ (1,0) [0|14] "" MHU
  SG_ ADAS_SVM_LCamera_Fault : 17|2@0+ (1,0) [0|3] "-" MHU
  SG_ ADAS_USS_Front_Fault : 19|2@0+ (1,0) [0|3] "-" MHU
  SG_ ADAS_SVM_FCamera_Fault : 21|2@0+ (1,0) [0|3] "-" MHU
  SG_ ADAS_SRR_RR_Fault : 23|2@0+ (1,0) [0|3] "-" MHU
  SG_ ADAS_SRR_FR_Fault : 25|2@0+ (1,0) [0|3] "-" MHU
  SG_ ADAS_SVM_RCamera_Fault : 27|2@0+ (1,0) [0|3] "-" MHU
  SG_ ADAS_USS_Rear_Fault : 29|2@0+ (1,0) [0|3] "-" MHU
  SG_ ADAS_SCAM_Fault : 31|2@0+ (1,0) [0|3] "-" MHU
  SG_ ADAS_MRR_Fault : 33|2@0+ (1,0) [0|3] "-" MHU
  SG_ ADAS_SRR_RL_Fault : 35|2@0+ (1,0) [0|3] "-" MHU
  SG_ ADAS_SVM_RightCamera_Fault : 39|2@0+ (1,0) [0|3] "-" MHU
  SG_ ADAS_ECU_Fault : 41|2@0+ (1,0) [0|3] "-" MHU
  SG_ ADAS_SRR_FL_Fault : 43|2@0+ (1,0) [0|3] "-" MHU
  SG_ ADAS_APAUSS_Rear_Fault : 45|2@0+ (1,0) [0|3] "-" MHU
  SG_ ADAS_APAUSS_Front_Fault : 47|2@0+ (1,0) [0|3] "-" MHU
  SG_ SECCAN_SensorFault : 63|8@0+ (1,0) [0|255] "" MHU

BO_ 1058 MHU_STATUS: 8 MHU
  SG_ CHKSM_MHU_STAT : 7|8@0+ (1,0) [0|255] "" ADAS_Info,HUD,XGW_Info
  SG_ ALV_MHU_STAT : 11|4@0+ (1,0) [0|14] "" ADAS_Info,HUD,XGW_Info
  SG_ MHU_STAT_Cluster : 17|2@0+ (1,0) [0|3] "-" ADAS_Info,HUD,XGW_Info
  SG_ MHU_STAT_Infotainment : 19|2@0+ (1,0) [0|3] "" ADAS_Info,HUD,XGW_Info
  SG_ MHU_STAT_MileageUnit : 21|2@0+ (1,0) [0|3] "" ADAS_Info,HUD,XGW_Info
  SG_ MHU_STAT_PressureUnit : 23|2@0+ (1,0) [0|3] "-" HUD,XGW_Info
  SG_ MHU_STAT_TemperatureUnit : 25|2@0+ (1,0) [0|3] "-" HUD,XGW_Info
  SG_ MHU_STAT_DateTimeFormat : 29|2@0+ (1,0) [0|3] "-" HUD,XGW_Info
  SG_ MHU_Operation_State : 34|3@0+ (1,0) [0|7] "" ADAS_Info,HUD,XGW_Info
  SG_ MHU_STAT_Language : 39|5@0+ (1,0) [0|31] "-" HUD,XGW_Info
  SG_ MHU_STAT_EnergyConsumptionUnit : 43|4@0+ (1,0) [0|15] "-" ADAS_Info,HUD,XGW_Info
  SG_ BAS_version : 47|4@0+ (1,0) [0|15] "" XGW_Info
  SG_ MHU_STAT_SaleCountry : 55|10@0+ (1,0) [0|1023] "-" ADAS_Info,HUD,XGW_Info
  SG_ MHU_STAT_BatLvlPopsetting : 59|3@0+ (1,0) [0|7] "-" HUD
  SG_ MHU_STAT_DistToEmptyUnit : 61|2@0+ (1,0) [0|3] "-" HUD

BO_ 1059 AVAS_STATUS: 8 XGW_Info
  SG_ AVAS_BatteryUnderVoltage : 0|1@0+ (1,0) [0|1] "-" MHU
  SG_ AVAS_BatteryOverVoltage : 1|1@0+ (1,0) [0|1] "-" MHU
  SG_ AVAS_VINInfoNotPrgm : 2|1@0+ (1,0) [0|1] "" MHU
  SG_ AVAS_AMPVoltSplDrvOperationFail : 3|1@0+ (1,0) [0|1] "-" MHU
  SG_ AVAS_AMPIntFaultOverCurr : 4|1@0+ (1,0) [0|1] "" MHU
  SG_ AVAS_AMPInternalFaultDCError : 5|1@0+ (1,0) [0|1] "" MHU
  SG_ AVAS_AMPInternalFaultOverTemp : 6|1@0+ (1,0) [0|1] "" MHU
  SG_ AVAS_AMPInternalFaultClockError : 7|1@0+ (1,0) [0|1] "-" MHU
  SG_ AVAS_SpkrMntPwrSwDrvHighFlt : 8|1@0+ (1,0) [0|1] "-" MHU
  SG_ AVAS_SpkrMntPwrSwDrvLowFlt : 9|1@0+ (1,0) [0|1] "-" MHU
  SG_ AVAS_InternalSpeakerOpen : 10|1@0+ (1,0) [0|1] "" MHU
  SG_ AVAS_ECUMalFlshOperationErr : 11|1@0+ (1,0) [0|1] "" MHU
  SG_ AVAS_ECUMalfunctionRamFailure : 12|1@0+ (1,0) [0|1] "-" MHU
  SG_ AVAS_ECUMalEEPROMFailure : 13|1@0+ (1,0) [0|1] "" MHU
  SG_ AVAS_CANBusOff : 14|1@0+ (1,0) [0|1] "-" MHU
  SG_ AVAS_LossCommVehicleSpeed : 15|1@0+ (1,0) [0|1] "" MHU
  SG_ AVAS_LossCommGearPosition : 16|1@0+ (1,0) [0|1] "-" MHU
  SG_ AVAS_LossCommAVASCloseCmd : 17|1@0+ (1,0) [0|1] "-" MHU

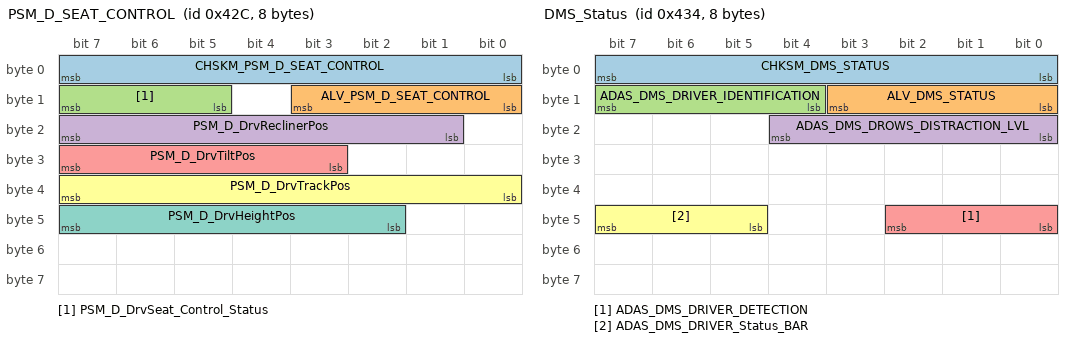
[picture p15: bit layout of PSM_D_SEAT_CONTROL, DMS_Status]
BO_ 1068 PSM_D_SEAT_CONTROL: 8 XGW_Info
  SG_ CHSKM_PSM_D_SEAT_CONTROL : 7|8@0+ (1,0) [0|255] "" MHU
  SG_ ALV_PSM_D_SEAT_CONTROL : 11|4@0+ (1,0) [0|14] "" MHU
  SG_ PSM_D_DrvSeat_Control_Status : 15|3@0+ (1,0) [0|7] "" MHU
  SG_ PSM_D_DrvReclinerPos : 23|7@0+ (1,0) [0|127] "degree" MHU
  SG_ PSM_D_DrvTiltPos : 31|5@0+ (1,0) [0|31] "mm" MHU
  SG_ PSM_D_DrvTrackPos : 39|8@0+ (1,0) [0|255] "mm" MHU
  SG_ PSM_D_DrvHeightPos : 47|6@0+ (1,0) [0|63] "mm" MHU

BO_ 1069 XGW_Info_Collect: 3 XGW_Info
  SG_ XGW_WasherFluid_LevelSwitch : 1|2@0+ (1,0) [0|3] "Bit" MHU

BO_ 1070 XGW_HCMInfo: 5 XGW_Info
  SG_ CHKSM_XGW_HCMInfo : 7|8@0+ (1,0) [0|255] "" MHU
  SG_ ALV_XGW_HCMInfo : 11|4@0+ (1,0) [0|14] "" MHU
  SG_ XGW_HLVerLvlMode : 13|2@0+ (1,0) [0|3] "-" MHU
  SG_ XGW_AutoHeadlamp_LvlSts : 15|2@0+ (1,0) [0|3] "-" MHU

BO_ 1073 HUD_ECU_Status: 2 HUD
  SG_ HUD_ECU_Check : 7|8@0+ (1,0) [0|255] "-" XGW_Info
  SG_ HUD_ECU_Fault : 15|8@0+ (1,0) [0|255] "-" XGW_Info

BO_ 1074 MHU_FOTA_STATUS: 8 MHU
  SG_ MHU_FOTA_Checksum : 7|8@0+ (1,0) [0|255] "" AMP,CPD,EASC,HUD,XGW_Info
  SG_ MHU_FOTA_Alive_Counter : 11|4@0+ (1,0) [0|14] "" AMP,CPD,EASC,HUD,XGW_Info
  SG_ MHU_FOTA_State : 15|4@0+ (1,0) [0|14] "-" AMP,CPD,EASC,HUD,XGW_Info
  SG_ MHU_FOTA_Error_Code : 23|8@0+ (1,0) [0|255] "-" AMP,CPD,EASC,HUD,XGW_Info

BO_ 1075 MHU_HEADLAMP_CTL: 2 MHU
  SG_ MHU_Headlamp_Chksm : 7|8@0+ (1,0) [0|255] "-" XGW_Info
  SG_ MHU_Headlamp_Aliv : 11|4@0+ (1,0) [0|14] "-" XGW_Info
  SG_ MHU_HLVerLvlMode : 15|2@0+ (1,0) [0|3] "-" XGW_Info

BO_ 1076 DMS_Status: 8 ADAS_Info
  SG_ CHKSM_DMS_STATUS : 7|8@0+ (1,0) [0|255] "" HUD,MHU
  SG_ ALV_DMS_STATUS : 11|4@0+ (1,0) [0|14] "" HUD,MHU
  SG_ ADAS_DMS_DRIVER_IDENTIFICATION : 15|4@0+ (1,0) [0|15] "-" HUD,MHU
  SG_ ADAS_DMS_DROWS_DISTRACTION_LVL : 20|5@0+ (1,0) [0|31] "-" HUD,MHU
  SG_ ADAS_DMS_DRIVER_DETECTION : 42|3@0+ (1,0) [0|7] "-" HUD,MHU
  SG_ ADAS_DMS_DRIVER_Status_BAR : 47|3@0+ (1,0) [0|7] "Bit" HUD,MHU

BO_ 1077 BCM_SCM_LIN_Info: 1 XGW_Info
  SG_ BCM_SCM_BC_Button : 1|2@0+ (1,0) [0|3] "-" HUD,MHU

BO_ 1078 MHU_HUD_Info_1: 5 MHU
  SG_ MHU_TELStatus : 2|3@0+ (1,0) [0|7] "-" HUD
  SG_ MHU_MUTEStatus : 4|2@0+ (1,0) [0|3] "-" HUD
  SG_ MHU_TEL_source : 7|3@0+ (1,0) [0|7] "-" HUD
  SG_ SECCAN_HUD_info : 39|8@0+ (1,0) [0|255] "" HUD

BO_ 1079 VCU_MHU_info_2: 8 XGW_Info
  SG_ CRC_VCU_MHU_info_2 : 7|8@0+ (1,0) [0|255] "" MHU
  SG_ ALIV_VCU_MHU_info_2 : 11|4@0+ (1,0) [0|14] "" MHU
  SG_ VCU_Instant_ConsumEnergy : 24|10@0+ (0.1,0) [0|100] "kWh/100km" MHU
  SG_ VCU_Average_ConsumEnergy : 52|10@0+ (0.1,0) [0|100] "kWh/100km" MHU

BO_ 1080 EDS_Error_FR_A: 8 XGW_Info
  SG_ CHKSM_EDS_Error_FR_A : 7|8@0+ (1,0) [0|255] "" MHU
  SG_ ALV_EDS_Error_FR_A : 11|4@0+ (1,0) [0|14] "" MHU
  SG_ EDS_FailNum_ERR_FWD : 23|8@0+ (1,0) [0|255] "" MHU
  SG_ EDS_FailGrade_ERR_FWD : 26|3@0+ (1,0) [0|7] "" MHU
  SG_ EDS_MotOverTempAlarm_FWD : 27|1@0+ (1,0) [0|1] "" MHU
  SG_ EDS_MotOverTempFault_FWD : 28|1@0+ (1,0) [0|1] "" MHU
  SG_ EDS_MotTempSenFault_FWD : 29|1@0+ (1,0) [0|1] "" MHU
  SG_ EDS_EDSOverTempUFault_FWD : 30|1@0+ (1,0) [0|1] "" MHU
  SG_ EDS_EDSOverTempVFault_FWD : 31|1@0+ (1,0) [0|1] "" MHU
  SG_ EDS_EDSOverTempWFault_FWD : 32|1@0+ (1,0) [0|1] "" MHU
  SG_ EDS_EDSOverTempAlarm_FWD : 33|1@0+ (1,0) [0|1] "" MHU
  SG_ EDS_TCoolantOvHi_FWD : 34|1@0+ (1,0) [0|1] "" MHU
  SG_ EDS_EDSTempCmpAlarm_FWD : 35|1@0+ (1,0) [0|1] "" MHU
  SG_ EDS_EDSPhaOvCurentHWFault_FWD : 36|1@0+ (1,0) [0|1] "" MHU
  SG_ EDS_EDSphaOffCalFault_FWD : 37|1@0+ (1,0) [0|1] "" MHU
  SG_ EDS_EDSOverIdcLnkAlarm_FWD : 38|1@0+ (1,0) [0|1] "" MHU
  SG_ EDS_EDSHVOverVoltageAlarm_FWD : 39|1@0+ (1,0) [0|1] "" MHU
  SG_ EDS_EDSHVOverVoltageFault_FWD : 40|1@0+ (1,0) [0|1] "" MHU
  SG_ EDS_EDSHVUnderVoltageAlarm_FWD : 41|1@0+ (1,0) [0|1] "" MHU
  SG_ EDS_EDSHVUnderVoltageFault_FWD : 42|1@0+ (1,0) [0|1] "" MHU
  SG_ EDS_RunToDischaErr_FWD : 43|1@0+ (1,0) [0|1] "" MHU
  SG_ EDS_12VOverVoltageAlarm_FWD : 44|1@0+ (1,0) [0|1] "" MHU
  SG_ EDS_12VUnderVoltageAlarm_FWD : 45|1@0+ (1,0) [0|1] "" MHU
  SG_ EDS_MotOverAlarm_FWD : 46|1@0+ (1,0) [0|1] "" MHU
  SG_ EDS_MotOverFault_FWD : 47|1@0+ (1,0) [0|1] "" MHU
  SG_ EDS_ResolverOffsetAngle_FWD : 48|1@0+ (1,0) [0|1] "" MHU
  SG_ SECCAN_EDS_Error_FR_A : 63|8@0+ (1,0) [0|255] "" MHU

BO_ 1081 EDS_Error_RR_A: 8 XGW_Info
  SG_ CHKSM_EDS_Error_RR_A : 7|8@0+ (1,0) [0|255] "" MHU
  SG_ ALV_EDS_Error_RR_A : 11|4@0+ (1,0) [0|14] "" MHU
  SG_ EDS_FailNum_ERR_RWD : 23|8@0+ (1,0) [0|255] "" MHU
  SG_ EDS_FailGrade_ERR_RWD : 26|3@0+ (1,0) [0|7] "" MHU
  SG_ EDS_MotOverTempAlarm_RWD : 27|1@0+ (1,0) [0|1] "" MHU
  SG_ EDS_MotOverTempFault_RWD : 28|1@0+ (1,0) [0|1] "" MHU
  SG_ EDS_MotTempSenFault_RWD : 29|1@0+ (1,0) [0|1] "" MHU
  SG_ EDS_EDSOverTempUFault_RWD : 30|1@0+ (1,0) [0|1] "" MHU
  SG_ EDS_EDSOverTempVFault_RWD : 31|1@0+ (1,0) [0|1] "" MHU
  SG_ EDS_EDSOverTempWFault_RWD : 32|1@0+ (1,0) [0|1] "" MHU
  SG_ EDS_EDSOverTempAlarm_RWD : 33|1@0+ (1,0) [0|1] "" MHU
  SG_ EDS_TCoolantOvHi_RWD : 34|1@0+ (1,0) [0|1] "" MHU
  SG_ EDS_EDSTempCmpAlarm_RWD : 35|1@0+ (1,0) [0|1] "" MHU
  SG_ EDS_EDSPhaOvCurentHWFault_RWD : 36|1@0+ (1,0) [0|1] "" MHU
  SG_ EDS_EDSphaOffCalFault_RWD : 37|1@0+ (1,0) [0|1] "" MHU
  SG_ EDS_EDSOverIdcLnkAlarm_RWD : 38|1@0+ (1,0) [0|1] "" MHU
  SG_ EDS_EDSHVOverVoltageAlarm_RWD : 39|1@0+ (1,0) [0|1] "" MHU
  SG_ EDS_EDSHVOverVoltageFault_RWD : 40|1@0+ (1,0) [0|1] "" MHU
  SG_ EDS_EDSHVUnderVoltageAlarm_RWD : 41|1@0+ (1,0) [0|1] "" MHU
  SG_ EDS_EDSHVUnderVoltageFault_RWD : 42|1@0+ (1,0) [0|1] "" MHU
  SG_ EDS_RunToDischaErr_RWD : 43|1@0+ (1,0) [0|1] "" MHU
  SG_ EDS_12VOverVoltageAlarm_RWD : 44|1@0+ (1,0) [0|1] "" MHU
  SG_ EDS_12VUnderVoltageAlarm_RWD : 45|1@0+ (1,0) [0|1] "" MHU
  SG_ EDS_MotOverAlarm_RWD : 46|1@0+ (1,0) [0|1] "" MHU
  SG_ EDS_MotOverFault_RWD : 47|1@0+ (1,0) [0|1] "" MHU
  SG_ EDS_ResolverOffsetAngle_RWD : 48|1@0+ (1,0) [0|1] "" MHU
  SG_ SECCAN_EDS_Error_RR_A : 63|8@0+ (1,0) [0|255] "" MHU

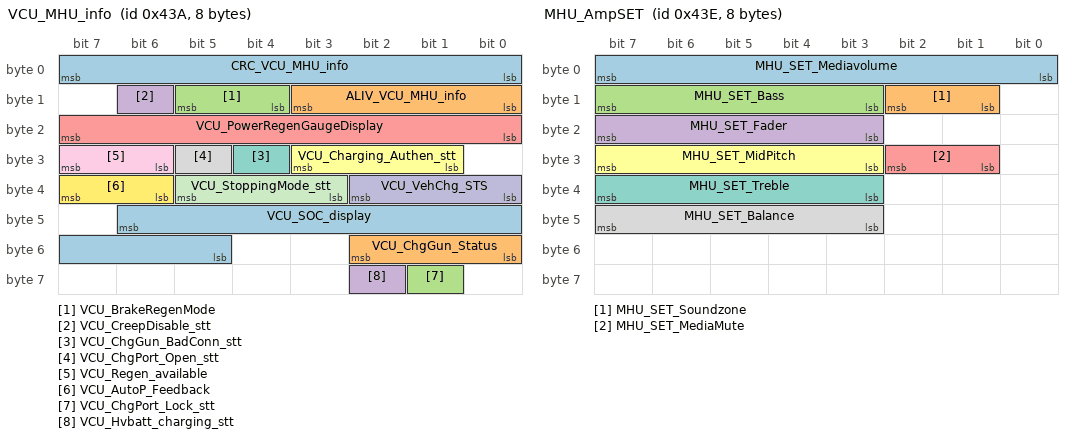
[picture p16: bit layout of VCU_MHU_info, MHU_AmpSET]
BO_ 1082 VCU_MHU_info: 8 XGW_Info
  SG_ CRC_VCU_MHU_info : 7|8@0+ (1,0) [0|255] "" HUD,MHU
  SG_ ALIV_VCU_MHU_info : 11|4@0+ (1,0) [0|14] "" HUD,MHU
  SG_ VCU_BrakeRegenMode : 13|2@0+ (1,0) [0|3] "-" HUD,MHU
  SG_ VCU_CreepDisable_stt : 14|1@0+ (1,0) [0|1] "" HUD,MHU
  SG_ VCU_PowerRegenGaugeDisplay : 23|8@0+ (1,-100) [-100|100] "%" HUD,MHU
  SG_ VCU_Charging_Authen_stt : 27|3@0+ (1,0) [0|7] "-" HUD,MHU
  SG_ VCU_ChgGun_BadConn_stt : 28|1@0+ (1,0) [0|1] "" HUD,MHU
  SG_ VCU_ChgPort_Open_stt : 29|1@0+ (1,0) [0|1] "" HUD,MHU
  SG_ VCU_Regen_available : 31|2@0+ (1,0) [0|3] "" HUD,MHU
  SG_ VCU_VehChg_STS : 34|3@0+ (1,0) [0|7] "" HUD,MHU
  SG_ VCU_StoppingMode_stt : 37|3@0+ (1,0) [0|7] "" MHU
  SG_ VCU_AutoP_Feedback : 39|2@0+ (1,0) [0|3] "" MHU
  SG_ VCU_SOC_display : 46|10@0+ (0.1,0) [0|100] "%" HUD,MHU
  SG_ VCU_ChgGun_Status : 50|3@0+ (1,0) [0|7] "" HUD,MHU
  SG_ VCU_ChgPort_Lock_stt : 57|1@0+ (1,0) [0|1] "" HUD,MHU
  SG_ VCU_Hvbatt_charging_stt : 58|1@0+ (1,0) [0|1] "-" HUD,MHU

BO_ 1083 MHU_SteeringAdjust: 3 MHU
  SG_ MHU_SET_TiltPos : 7|8@0+ (1,0) [0|100] "%" EASC
  SG_ MHU_SET_TelePos : 15|8@0+ (1,0) [0|100] "%" EASC
  SG_ MHU_SET_SteeringAdjust : 23|2@0+ (1,0) [0|3] "-" EASC

BO_ 1084 EASC_Confirm_sts: 3 EASC
  SG_ EASC_TiltPos : 7|8@0+ (1,0) [0|100] "%" MHU
  SG_ EASC_TelePos : 15|8@0+ (1,0) [0|100] "%" MHU
  SG_ EASC_SteeringAdjust : 23|2@0+ (1,0) [0|3] "-" MHU

BO_ 1086 MHU_AmpSET: 8 MHU
  SG_ MHU_SET_Mediavolume : 7|8@0+ (1,0) [0|40] "-" AMP
  SG_ MHU_SET_Soundzone : 10|2@0+ (1,0) [0|3] "-" AMP
  SG_ MHU_SET_Bass : 15|5@0+ (1,-6) [-6|6] "-" AMP
  SG_ MHU_SET_Fader : 23|5@0+ (1,-10) [-10|10] "-" AMP
  SG_ MHU_SET_MediaMute : 26|2@0+ (1,0) [1|3] "-" AMP
  SG_ MHU_SET_MidPitch : 31|5@0+ (1,-6) [-6|6] "-" AMP
  SG_ MHU_SET_Treble : 39|5@0+ (1,-6) [-6|6] "-" AMP
  SG_ MHU_SET_Balance : 47|5@0+ (1,-10) [-10|10] "-" AMP

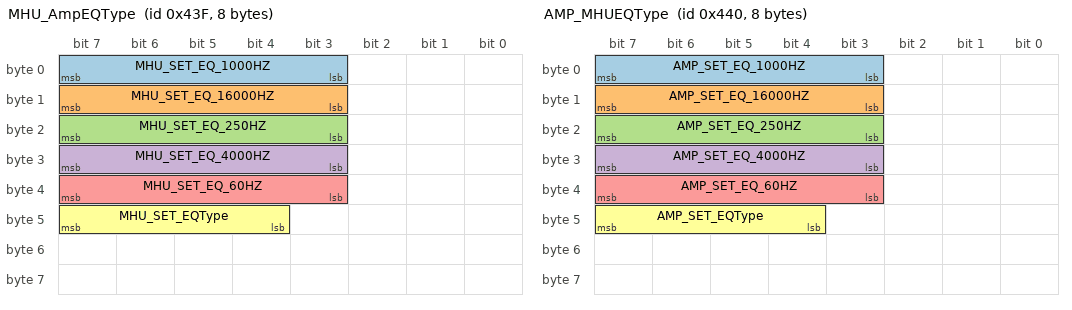
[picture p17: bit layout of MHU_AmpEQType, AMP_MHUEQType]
BO_ 1087 MHU_AmpEQType: 8 MHU
  SG_ MHU_SET_EQ_1000HZ : 7|5@0+ (1,-6) [-6|6] "-" AMP
  SG_ MHU_SET_EQ_16000HZ : 15|5@0+ (1,-6) [-6|6] "-" AMP
  SG_ MHU_SET_EQ_250HZ : 23|5@0+ (1,-6) [-6|6] "-" AMP
  SG_ MHU_SET_EQ_4000HZ : 31|5@0+ (1,-6) [-6|6] "-" AMP
  SG_ MHU_SET_EQ_60HZ : 39|5@0+ (1,-6) [-6|6] "-" AMP
  SG_ MHU_SET_EQType : 47|4@0+ (1,0) [0|15] "-" AMP

BO_ 1088 AMP_MHUEQType: 8 AMP
  SG_ AMP_SET_EQ_1000HZ : 7|5@0+ (1,-6) [-6|6] "-" MHU
  SG_ AMP_SET_EQ_16000HZ : 15|5@0+ (1,-6) [-6|6] "-" MHU
  SG_ AMP_SET_EQ_250HZ : 23|5@0+ (1,-6) [-6|6] "-" MHU
  SG_ AMP_SET_EQ_4000HZ : 31|5@0+ (1,-6) [-6|6] "-" MHU
  SG_ AMP_SET_EQ_60HZ : 39|5@0+ (1,-6) [-6|6] "-" MHU
  SG_ AMP_SET_EQType : 47|4@0+ (1,0) [0|15] "-" MHU

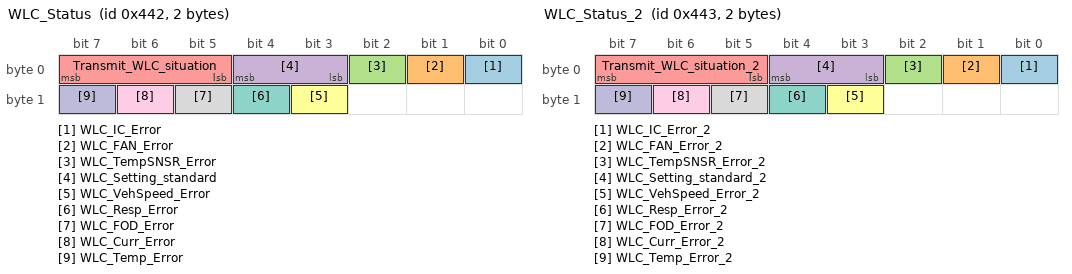
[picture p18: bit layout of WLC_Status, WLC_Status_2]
BO_ 1090 WLC_Status: 2 XGW_Info
  SG_ WLC_IC_Error : 0|1@0+ (1,0) [0|1] "" MHU
  SG_ WLC_FAN_Error : 1|1@0+ (1,0) [0|1] "-" MHU
  SG_ WLC_TempSNSR_Error : 2|1@0+ (1,0) [0|1] "-" MHU
  SG_ WLC_Setting_standard : 4|2@0+ (1,0) [0|3] "-" MHU
  SG_ Transmit_WLC_situation : 7|3@0+ (1,0) [0|7] "" MHU
  SG_ WLC_VehSpeed_Error : 11|1@0+ (1,0) [0|1] "" MHU
  SG_ WLC_Resp_Error : 12|1@0+ (1,0) [0|1] "" MHU
  SG_ WLC_FOD_Error : 13|1@0+ (1,0) [0|1] "-" MHU
  SG_ WLC_Curr_Error : 14|1@0+ (1,0) [0|1] "-" MHU
  SG_ WLC_Temp_Error : 15|1@0+ (1,0) [0|1] "" MHU

BO_ 1091 WLC_Status_2: 2 XGW_Info
  SG_ WLC_IC_Error_2 : 0|1@0+ (1,0) [0|1] "-" MHU
  SG_ WLC_FAN_Error_2 : 1|1@0+ (1,0) [0|1] "" MHU
  SG_ WLC_TempSNSR_Error_2 : 2|1@0+ (1,0) [0|1] "-" MHU
  SG_ WLC_Setting_standard_2 : 4|2@0+ (1,0) [0|3] "" MHU
  SG_ Transmit_WLC_situation_2 : 7|3@0+ (1,0) [0|7] "" MHU
  SG_ WLC_VehSpeed_Error_2 : 11|1@0+ (1,0) [0|1] "" MHU
  SG_ WLC_Resp_Error_2 : 12|1@0+ (1,0) [0|1] "-" MHU
  SG_ WLC_FOD_Error_2 : 13|1@0+ (1,0) [0|1] "-" MHU
  SG_ WLC_Curr_Error_2 : 14|1@0+ (1,0) [0|1] "-" MHU
  SG_ WLC_Temp_Error_2 : 15|1@0+ (1,0) [0|1] "" MHU

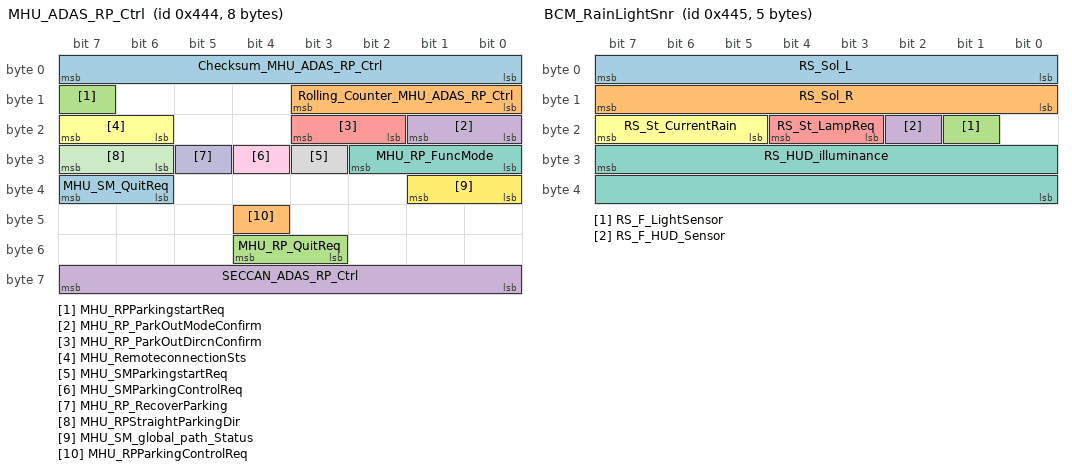
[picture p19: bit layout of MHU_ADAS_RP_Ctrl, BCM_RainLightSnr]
BO_ 1092 MHU_ADAS_RP_Ctrl: 8 MHU
  SG_ Checksum_MHU_ADAS_RP_Ctrl : 7|8@0+ (1,0) [0|255] "" ADAS_Info
  SG_ Rolling_Counter_MHU_ADAS_RP_Ctrl : 11|4@0+ (1,0) [0|14] "" ADAS_Info
  SG_ MHU_RPParkingstartReq : 15|1@0+ (1,0) [0|1] "-" ADAS_Info
  SG_ MHU_RP_ParkOutModeConfirm : 17|2@0+ (1,0) [0|3] "-" ADAS_Info
  SG_ MHU_RP_ParkOutDircnConfirm : 19|2@0+ (1,0) [0|3] "-" ADAS_Info
  SG_ MHU_RemoteconnectionSts : 23|2@0+ (1,0) [0|3] "-" ADAS_Info
  SG_ MHU_RP_FuncMode : 26|3@0+ (1,0) [0|7] "-" ADAS_Info
  SG_ MHU_SMParkingstartReq : 27|1@0+ (1,0) [0|1] "" ADAS_Info
  SG_ MHU_SMParkingControlReq : 28|1@0+ (1,0) [0|1] "" ADAS_Info
  SG_ MHU_RP_RecoverParking : 29|1@0+ (1,0) [0|1] "-" ADAS_Info
  SG_ MHU_RPStraightParkingDir : 31|2@0+ (1,0) [0|3] "-" ADAS_Info
  SG_ MHU_SM_global_path_Status : 33|2@0+ (1,0) [0|3] "" ADAS_Info
  SG_ MHU_SM_QuitReq : 39|2@0+ (1,0) [0|3] "" ADAS_Info
  SG_ MHU_RPParkingControlReq : 44|1@0+ (1,0) [0|1] "-" ADAS_Info
  SG_ MHU_RP_QuitReq : 52|2@0+ (1,0) [0|3] "-" ADAS_Info
  SG_ SECCAN_ADAS_RP_Ctrl : 63|8@0+ (1,0) [0|255] "" ADAS_Info

BO_ 1093 BCM_RainLightSnr: 5 XGW_Info
  SG_ RS_Sol_L : 7|8@0+ (5,0) [0|1000] "W/m^2" MHU
  SG_ RS_Sol_R : 15|8@0+ (5,0) [0|1000] "W/m^2" MHU
  SG_ RS_F_LightSensor : 17|1@0+ (1,0) [0|1] "" HUD,MHU
  SG_ RS_F_HUD_Sensor : 18|1@0+ (1,0) [0|1] "cd/m2" HUD,MHU
  SG_ RS_St_LampReq : 20|2@0+ (1,0) [0|3] "" MHU
  SG_ RS_St_CurrentRain : 23|3@0+ (1,0) [0|7] "" MHU
  SG_ RS_HUD_illuminance : 31|16@0+ (1,0) [0|10000] "cd/m2" HUD,MHU

BA_DEF_ BO_  "GenMsgSendType" ENUM "Cyclic","NotUsed","NotUsed","NotUsed","NotUsed","NotUsed","NotUsed","IfActive","NoMsgSendType","NotUsed";
BA_DEF_ BO_  "GenMsgILSupport" ENUM "No","Yes";
BA_DEF_ BO_  "DiagResponse" ENUM "No","Yes";
BA_DEF_ BO_  "DiagRequest" ENUM "No","Yes";
BA_DEF_ BO_  "NmAsrMessage" ENUM "No","Yes";
BA_DEF_ BO_  "DiagState" ENUM "No","Yes";
BA_DEF_ BO_  "DiagUudtResponse" ENUM "False","True";
BA_DEF_ BO_  "GenMsgStartDelayTime" INT 0 65535;
BA_DEF_ BO_  "GenMsgDelayTime" INT 0 0;
BA_DEF_ BO_  "GenMsgNrOfRepetition" INT 0 0;
BA_DEF_ BO_  "GenMsgCycleTimeFast" INT 0 0;
BA_DEF_ BO_  "GenMsgCycleTime" INT 0 0;
BA_DEF_ SG_  "GenSigSendType" ENUM "Cyclic","OnWrite","OnWriteWithRepetition","OnChange","OnChangeWithRepetition","IfActive","IfActiveWithRepetition","NoSigSendType","NotUsed","NotUsed","NotUsed","NotUsed","NotUsed";
BA_DEF_ SG_  "InvalidValue" STRING;
BA_DEF_ SG_  "GenSigStartValue" INT 0 0;
BA_DEF_ SG_  "GenSigTimeoutTime_ALL" INT 0 65535;
BA_DEF_DEF_  "DiagRequest" "No";
BA_DEF_DEF_  "DiagResponse" "No";
BA_DEF_DEF_  "DiagState" "No";
BA_DEF_DEF_  "DiagUudtResponse" "False";
BA_DEF_DEF_  "GenMsgCycleTime" 0;
BA_DEF_DEF_  "GenMsgCycleTimeFast" 0;
BA_DEF_DEF_  "GenMsgDelayTime" 0;
BA_DEF_DEF_  "GenMsgILSupport" "Yes";
BA_DEF_DEF_  "GenMsgNrOfRepetition" 0;
BA_DEF_DEF_  "GenMsgSendType" "NoMsgSendType";
BA_DEF_DEF_  "GenMsgStartDelayTime" 0;
BA_DEF_DEF_  "GenSigSendType" "Cyclic";
BA_DEF_DEF_  "GenSigStartValue" 0;
BA_DEF_DEF_  "GenSigTimeoutTime_ALL" 0;
BA_DEF_DEF_  "NmAsrMessage" "No";
BA_ "GenMsgCycleTimeFast" BO_ 852 50;
BA_ "GenMsgNrOfRepetition" BO_ 852 2;
BA_ "GenMsgCycleTime" BO_ 853 50;
BA_ "GenMsgSendType" BO_ 853 0;
BA_ "GenMsgCycleTime" BO_ 880 300;
BA_ "GenMsgSendType" BO_ 880 0;
BA_ "GenMsgCycleTime" BO_ 885 50;
BA_ "GenMsgILSupport" BO_ 885 0;
BA_ "GenMsgSendType" BO_ 885 0;
BA_ "GenMsgCycleTime" BO_ 896 1000;
BA_ "GenMsgSendType" BO_ 896 0;
BA_ "GenMsgCycleTime" BO_ 897 200;
BA_ "GenMsgSendType" BO_ 897 0;
BA_ "GenMsgDelayTime" BO_ 905 10;
BA_ "GenMsgCycleTimeFast" BO_ 915 50;
BA_ "GenMsgNrOfRepetition" BO_ 915 2;
BA_ "GenMsgCycleTimeFast" BO_ 919 100;
BA_ "GenMsgNrOfRepetition" BO_ 919 3;
BA_ "GenMsgCycleTimeFast" BO_ 922 100;
BA_ "GenMsgNrOfRepetition" BO_ 922 3;
BA_ "GenMsgCycleTimeFast" BO_ 923 100;
BA_ "GenMsgNrOfRepetition" BO_ 923 3;
BA_ "GenMsgCycleTime" BO_ 925 50;
BA_ "GenMsgSendType" BO_ 925 0;
BA_ "GenMsgCycleTime" BO_ 992 150;
BA_ "GenMsgSendType" BO_ 992 0;
BA_ "GenMsgCycleTime" BO_ 993 100;
BA_ "GenMsgSendType" BO_ 993 0;
BA_ "GenMsgCycleTime" BO_ 1015 1000;
BA_ "GenMsgCycleTimeFast" BO_ 1015 50;
BA_ "GenMsgNrOfRepetition" BO_ 1015 3;
BA_ "GenMsgSendType" BO_ 1015 0;
BA_ "GenMsgCycleTime" BO_ 1020 500;
BA_ "GenMsgSendType" BO_ 1020 0;
BA_ "GenMsgCycleTimeFast" BO_ 1025 100;
BA_ "GenMsgNrOfRepetition" BO_ 1025 3;
BA_ "GenMsgCycleTime" BO_ 1026 100;
BA_ "GenMsgCycleTimeFast" BO_ 1026 100;
BA_ "GenMsgNrOfRepetition" BO_ 1026 3;
BA_ "GenMsgSendType" BO_ 1026 0;
BA_ "GenMsgCycleTime" BO_ 1027 100;
BA_ "GenMsgSendType" BO_ 1027 0;
BA_ "GenMsgCycleTimeFast" BO_ 1028 100;
BA_ "GenMsgNrOfRepetition" BO_ 1028 3;
BA_ "GenMsgCycleTimeFast" BO_ 1029 50;
BA_ "GenMsgNrOfRepetition" BO_ 1029 3;
BA_ "GenMsgCycleTimeFast" BO_ 1030 100;
BA_ "GenMsgNrOfRepetition" BO_ 1030 3;
BA_ "GenMsgCycleTimeFast" BO_ 1032 100;
BA_ "GenMsgNrOfRepetition" BO_ 1032 3;
BA_ "GenMsgCycleTime" BO_ 1033 1000;
BA_ "GenMsgSendType" BO_ 1033 0;
BA_ "GenMsgCycleTimeFast" BO_ 1034 25;
BA_ "GenMsgNrOfRepetition" BO_ 1034 3;
BA_ "GenMsgCycleTimeFast" BO_ 1035 100;
BA_ "GenMsgNrOfRepetition" BO_ 1035 3;
BA_ "GenMsgCycleTime" BO_ 1036 200;
BA_ "GenMsgSendType" BO_ 1036 0;
BA_ "GenMsgCycleTime" BO_ 1037 120;
BA_ "GenMsgSendType" BO_ 1037 0;
BA_ "GenMsgCycleTime" BO_ 1038 1000;
BA_ "GenMsgSendType" BO_ 1038 0;
BA_ "GenMsgCycleTime" BO_ 1039 1000;
BA_ "GenMsgSendType" BO_ 1039 0;
BA_ "GenMsgCycleTime" BO_ 1040 1000;
BA_ "GenMsgSendType" BO_ 1040 0;
BA_ "GenMsgCycleTime" BO_ 1046 100;
BA_ "GenMsgSendType" BO_ 1046 0;
BA_ "GenMsgCycleTime" BO_ 1052 1000;
BA_ "GenMsgSendType" BO_ 1052 0;
BA_ "GenMsgCycleTime" BO_ 1053 100;
BA_ "GenMsgSendType" BO_ 1053 0;
BA_ "GenMsgCycleTime" BO_ 1054 300;
BA_ "GenMsgCycleTimeFast" BO_ 1054 25;
BA_ "GenMsgNrOfRepetition" BO_ 1054 3;
BA_ "GenMsgSendType" BO_ 1054 0;
BA_ "GenMsgCycleTime" BO_ 1055 300;
BA_ "GenMsgSendType" BO_ 1055 0;
BA_ "GenMsgCycleTime" BO_ 1058 1000;
BA_ "GenMsgSendType" BO_ 1058 0;
BA_ "GenMsgCycleTime" BO_ 1059 1000;
BA_ "GenMsgSendType" BO_ 1059 0;
BA_ "GenMsgCycleTime" BO_ 1068 200;
BA_ "GenMsgSendType" BO_ 1068 0;
BA_ "GenMsgCycleTimeFast" BO_ 1069 500;
BA_ "GenMsgNrOfRepetition" BO_ 1069 3;
BA_ "GenMsgCycleTime" BO_ 1070 100;
BA_ "GenMsgSendType" BO_ 1070 0;
BA_ "GenMsgCycleTime" BO_ 1073 100;
BA_ "GenMsgSendType" BO_ 1073 0;
BA_ "GenMsgCycleTime" BO_ 1074 500;
BA_ "GenMsgSendType" BO_ 1074 0;
BA_ "GenMsgCycleTime" BO_ 1075 500;
BA_ "GenMsgSendType" BO_ 1075 0;
BA_ "GenMsgCycleTime" BO_ 1076 500;
BA_ "GenMsgSendType" BO_ 1076 0;
BA_ "GenMsgCycleTimeFast" BO_ 1077 100;
BA_ "GenMsgNrOfRepetition" BO_ 1077 3;
BA_ "GenMsgCycleTimeFast" BO_ 1078 50;
BA_ "GenMsgNrOfRepetition" BO_ 1078 2;
BA_ "GenMsgCycleTime" BO_ 1079 100;
BA_ "GenMsgSendType" BO_ 1079 0;
BA_ "GenMsgCycleTime" BO_ 1080 100;
BA_ "GenMsgSendType" BO_ 1080 0;
BA_ "GenMsgCycleTime" BO_ 1081 100;
BA_ "GenMsgSendType" BO_ 1081 0;
BA_ "GenMsgCycleTime" BO_ 1082 100;
BA_ "GenMsgSendType" BO_ 1082 0;
BA_ "GenMsgCycleTimeFast" BO_ 1083 50;
BA_ "GenMsgNrOfRepetition" BO_ 1083 2;
BA_ "GenMsgCycleTimeFast" BO_ 1084 100;
BA_ "GenMsgNrOfRepetition" BO_ 1084 2;
BA_ "GenMsgCycleTime" BO_ 1086 100;
BA_ "GenMsgSendType" BO_ 1086 0;
BA_ "GenMsgCycleTime" BO_ 1087 100;
BA_ "GenMsgSendType" BO_ 1087 0;
BA_ "GenMsgCycleTime" BO_ 1088 100;
BA_ "GenMsgSendType" BO_ 1088 0;
BA_ "GenMsgCycleTime" BO_ 1090 500;
BA_ "GenMsgSendType" BO_ 1090 0;
BA_ "GenMsgCycleTime" BO_ 1091 500;
BA_ "GenMsgSendType" BO_ 1091 0;
BA_ "GenMsgCycleTime" BO_ 1092 100;
BA_ "GenMsgSendType" BO_ 1092 0;
BA_ "GenMsgCycleTime" BO_ 1093 100;
BA_ "GenMsgSendType" BO_ 1093 0;
BA_ "GenSigSendType" SG_ 852 MHU_FCW_Mode 2;
BA_ "GenSigStartValue" SG_ 852 MHU_FCW_Mode 1;
BA_ "InvalidValue" SG_ 852 MHU_FCW_Mode "3h";
BA_ "GenSigSendType" SG_ 852 MHU_FCW_sens 2;
BA_ "GenSigStartValue" SG_ 852 MHU_FCW_sens 1;
BA_ "InvalidValue" SG_ 852 MHU_FCW_sens "3h";
BA_ "GenSigSendType" SG_ 852 MHU_AEB_Mode 2;
BA_ "GenSigStartValue" SG_ 852 MHU_AEB_Mode 1;
BA_ "InvalidValue" SG_ 852 MHU_AEB_Mode "3h";
BA_ "GenSigSendType" SG_ 852 MHU_RAEB_Mode 2;
BA_ "GenSigStartValue" SG_ 852 MHU_RAEB_Mode 1;
BA_ "InvalidValue" SG_ 852 MHU_RAEB_Mode "3h";
BA_ "GenSigSendType" SG_ 852 MHU_LA_sens 2;
BA_ "GenSigStartValue" SG_ 852 MHU_LA_sens 1;
BA_ "InvalidValue" SG_ 852 MHU_LA_sens "3h";
BA_ "GenSigSendType" SG_ 852 MHU_LA_AudWarning 2;
BA_ "InvalidValue" SG_ 852 MHU_LA_AudWarning "3h";
BA_ "GenSigSendType" SG_ 852 MHU_BSD_On 2;
BA_ "GenSigStartValue" SG_ 852 MHU_BSD_On 1;
BA_ "InvalidValue" SG_ 852 MHU_BSD_On "3h";
BA_ "GenSigSendType" SG_ 852 MHU_ALC_ON 2;
BA_ "GenSigStartValue" SG_ 852 MHU_ALC_ON 1;
BA_ "InvalidValue" SG_ 852 MHU_ALC_ON "3h";
BA_ "GenSigSendType" SG_ 852 MHU_BSD_AudWarning 2;
BA_ "InvalidValue" SG_ 852 MHU_BSD_AudWarning "3h";
BA_ "GenSigSendType" SG_ 852 MHU_RCTA_On 2;
BA_ "GenSigStartValue" SG_ 852 MHU_RCTA_On 1;
BA_ "InvalidValue" SG_ 852 MHU_RCTA_On "3h";
BA_ "GenSigSendType" SG_ 852 MHU_RCTA_sens 2;
BA_ "GenSigStartValue" SG_ 852 MHU_RCTA_sens 1;
BA_ "InvalidValue" SG_ 852 MHU_RCTA_sens "3h";
BA_ "GenSigSendType" SG_ 852 MHU_PA_On 2;
BA_ "GenSigStartValue" SG_ 852 MHU_PA_On 1;
BA_ "InvalidValue" SG_ 852 MHU_PA_On "3h";
BA_ "GenSigSendType" SG_ 852 MHU_AHB_On 2;
BA_ "InvalidValue" SG_ 852 MHU_AHB_On "3h";
BA_ "GenSigSendType" SG_ 852 MHU_IA_Mode 2;
BA_ "InvalidValue" SG_ 852 MHU_IA_Mode "3h";
BA_ "GenSigSendType" SG_ 852 MHU_TSR_Mode 2;
BA_ "GenSigStartValue" SG_ 852 MHU_TSR_Mode 1;
BA_ "InvalidValue" SG_ 852 MHU_TSR_Mode "3h";
BA_ "GenSigSendType" SG_ 852 MHU_DOW_Mode 2;
BA_ "GenSigStartValue" SG_ 852 MHU_DOW_Mode 2;
BA_ "InvalidValue" SG_ 852 MHU_DOW_Mode "3h";
BA_ "GenSigSendType" SG_ 852 MHU_AHB_sens 2;
BA_ "GenSigStartValue" SG_ 852 MHU_AHB_sens 1;
BA_ "InvalidValue" SG_ 852 MHU_AHB_sens "3h";
BA_ "GenSigSendType" SG_ 852 MHU_LA_Mode 2;
BA_ "GenSigStartValue" SG_ 852 MHU_LA_Mode 3;
BA_ "InvalidValue" SG_ 852 MHU_LA_Mode "3h";
BA_ "GenSigSendType" SG_ 852 MHU_SET_TSR_AudWarn 2;
BA_ "GenSigStartValue" SG_ 852 MHU_SET_TSR_AudWarn 1;
BA_ "InvalidValue" SG_ 852 MHU_SET_TSR_AudWarn "3h";
BA_ "GenSigSendType" SG_ 852 MHU_SET_TSR_SLAert 2;
BA_ "GenSigStartValue" SG_ 852 MHU_SET_TSR_SLAert 1;
BA_ "InvalidValue" SG_ 852 MHU_SET_TSR_SLAert "3h";
BA_ "GenSigTimeoutTime_ALL" SG_ 853 CHKSM_ADAS_CMP_CHECK 500;
BA_ "GenSigTimeoutTime_ALL" SG_ 853 ALV_ADAS_CMP_CHECK 500;
BA_ "InvalidValue" SG_ 853 ALV_ADAS_CMP_CHECK "Fh";
BA_ "GenSigTimeoutTime_ALL" SG_ 853 ADAS_PAUSS_FaultFLO 500;
BA_ "GenSigTimeoutTime_ALL" SG_ 853 ADAS_PAUSS_FaultFLI 500;
BA_ "GenSigTimeoutTime_ALL" SG_ 853 ADAS_PAUSS_check 500;
BA_ "InvalidValue" SG_ 853 ADAS_PAUSS_check "3h";
BA_ "GenSigTimeoutTime_ALL" SG_ 853 ADAS_PAUSS_FaultRLO 500;
BA_ "GenSigTimeoutTime_ALL" SG_ 853 ADAS_PAUSS_FaultFRI 500;
BA_ "GenSigTimeoutTime_ALL" SG_ 853 ADAS_FPA_check 500;
BA_ "InvalidValue" SG_ 853 ADAS_FPA_check "3h";
BA_ "GenSigTimeoutTime_ALL" SG_ 853 ADAS_PAUSS_FaultRLI 500;
BA_ "GenSigTimeoutTime_ALL" SG_ 853 ADAS_PAUSS_FaultRRO 500;
BA_ "GenSigTimeoutTime_ALL" SG_ 853 ADAS_PAUSS_FaultRRI 500;
BA_ "GenSigTimeoutTime_ALL" SG_ 853 ADAS_RPA_check 500;
BA_ "InvalidValue" SG_ 853 ADAS_RPA_check "3h";
BA_ "GenSigTimeoutTime_ALL" SG_ 853 ADAS_PAUSS_FaultFRO 500;
BA_ "GenSigTimeoutTime_ALL" SG_ 880 CRC_MHU_SBR_Status 1500;
BA_ "GenSigTimeoutTime_ALL" SG_ 880 ALV_MHU_SBR_Status 1500;
BA_ "InvalidValue" SG_ 880 ALV_MHU_SBR_Status "Fh";
BA_ "GenSigStartValue" SG_ 880 SBR_STAT_Chime 3;
BA_ "GenSigTimeoutTime_ALL" SG_ 880 SBR_STAT_Chime 1500;
BA_ "InvalidValue" SG_ 880 SBR_STAT_Chime "3h";
BA_ "GenSigStartValue" SG_ 880 SBR_STAT_Telltale 3;
BA_ "GenSigTimeoutTime_ALL" SG_ 880 SBR_STAT_Telltale 1500;
BA_ "InvalidValue" SG_ 880 SBR_STAT_Telltale "3h";
BA_ "GenSigTimeoutTime_ALL" SG_ 880 SBR_STAT_Active 1500;
BA_ "GenSigTimeoutTime_ALL" SG_ 885 Checksum_0x375 500;
BA_ "InvalidValue" SG_ 885 Checksum_0x375 "null";
BA_ "GenSigTimeoutTime_ALL" SG_ 885 Rolling_Counter_0x375 500;
BA_ "InvalidValue" SG_ 885 Rolling_Counter_0x375 "Fh";
BA_ "GenSigTimeoutTime_ALL" SG_ 885 BMS_PreChgRelay_ERR 500;
BA_ "InvalidValue" SG_ 885 BMS_PreChgRelay_ERR "null";
BA_ "GenSigTimeoutTime_ALL" SG_ 885 BMS_TotalNegRelay_ERR 500;
BA_ "InvalidValue" SG_ 885 BMS_TotalNegRelay_ERR "null";
BA_ "GenSigTimeoutTime_ALL" SG_ 885 BMS_MainPosRelay_ERR 500;
BA_ "InvalidValue" SG_ 885 BMS_MainPosRelay_ERR "null";
BA_ "GenSigTimeoutTime_ALL" SG_ 885 BMS_MainPosRelay_STS 500;
BA_ "InvalidValue" SG_ 885 BMS_MainPosRelay_STS "7h";
BA_ "GenSigTimeoutTime_ALL" SG_ 885 BMS_PreChgRelay_STS 500;
BA_ "InvalidValue" SG_ 885 BMS_PreChgRelay_STS "7h";
BA_ "GenSigTimeoutTime_ALL" SG_ 885 BMS_TotalNegRelay_STS 500;
BA_ "InvalidValue" SG_ 885 BMS_TotalNegRelay_STS "7h";
BA_ "GenSigTimeoutTime_ALL" SG_ 896 VIN_Byte1 5000;
BA_ "InvalidValue" SG_ 896 VIN_Byte1 "null";
BA_ "GenSigTimeoutTime_ALL" SG_ 896 VIN_Byte2 5000;
BA_ "InvalidValue" SG_ 896 VIN_Byte2 "null";
BA_ "GenSigTimeoutTime_ALL" SG_ 896 VIN_Byte3 5000;
BA_ "InvalidValue" SG_ 896 VIN_Byte3 "null";
BA_ "GenSigTimeoutTime_ALL" SG_ 896 VIN_Byte4 5000;
BA_ "InvalidValue" SG_ 896 VIN_Byte4 "null";
BA_ "GenSigTimeoutTime_ALL" SG_ 896 VIN_Byte5 5000;
BA_ "InvalidValue" SG_ 896 VIN_Byte5 "null";
BA_ "GenSigTimeoutTime_ALL" SG_ 896 VIN_Byte6 5000;
BA_ "InvalidValue" SG_ 896 VIN_Byte6 "null";
BA_ "GenSigTimeoutTime_ALL" SG_ 896 VIN_Byte7 5000;
BA_ "InvalidValue" SG_ 896 VIN_Byte7 "null";
BA_ "GenSigTimeoutTime_ALL" SG_ 897 CHKSM_ACM_SEAT_OCCUPATION 1000;
BA_ "InvalidValue" SG_ 897 CHKSM_ACM_SEAT_OCCUPATION "null";
BA_ "GenSigTimeoutTime_ALL" SG_ 897 ALV_ACM_SEAT_OCCUPATION 1000;
BA_ "InvalidValue" SG_ 897 ALV_ACM_SEAT_OCCUPATION "Fh";
BA_ "GenSigTimeoutTime_ALL" SG_ 897 ACM_Seat_Occupancy_Passenger 1000;
BA_ "InvalidValue" SG_ 897 ACM_Seat_Occupancy_Passenger "null";
BA_ "GenSigTimeoutTime_ALL" SG_ 897 ACM_Seat_Occupancy_2nd_Row_Dri 1000;
BA_ "InvalidValue" SG_ 897 ACM_Seat_Occupancy_2nd_Row_Dri "null";
BA_ "GenSigTimeoutTime_ALL" SG_ 897 ACM_Seat_Occupancy_2nd_Row_Pas 1000;
BA_ "InvalidValue" SG_ 897 ACM_Seat_Occupancy_2nd_Row_Pas "null";
BA_ "GenSigTimeoutTime_ALL" SG_ 897 ACM_Seat_Occupancy_2nd_Row_Mid 1000;
BA_ "InvalidValue" SG_ 897 ACM_Seat_Occupancy_2nd_Row_Mid "null";
BA_ "GenSigTimeoutTime_ALL" SG_ 897 ACM_Seat_Belt_Status_Passenger 1000;
BA_ "InvalidValue" SG_ 897 ACM_Seat_Belt_Status_Passenger "null";
BA_ "GenSigTimeoutTime_ALL" SG_ 897 ACM_Seat_Belt_Status_Driver 1000;
BA_ "InvalidValue" SG_ 897 ACM_Seat_Belt_Status_Driver "null";
BA_ "GenSigTimeoutTime_ALL" SG_ 897 ACM_Seat_Belt_Status_2nd_Row_Dri 1000;
BA_ "InvalidValue" SG_ 897 ACM_Seat_Belt_Status_2nd_Row_Dri "null";
BA_ "GenSigTimeoutTime_ALL" SG_ 897 ACM_Seat_Belt_Status_2nd_Row_Mid 1000;
BA_ "InvalidValue" SG_ 897 ACM_Seat_Belt_Status_2nd_Row_Mid "null";
BA_ "GenSigTimeoutTime_ALL" SG_ 897 ACM_Seat_Belt_Status_2nd_Row_Pas 1000;
BA_ "InvalidValue" SG_ 897 ACM_Seat_Belt_Status_2nd_Row_Pas "null";
BA_ "GenSigSendType" SG_ 905 VCU_IMMO_Sts 1;
BA_ "InvalidValue" SG_ 905 VCU_IMMO_Sts "";
BA_ "GenSigSendType" SG_ 905 SECCAN_VCU_IMMO_Sts 1;
BA_ "InvalidValue" SG_ 905 SECCAN_VCU_IMMO_Sts "";
BA_ "GenSigSendType" SG_ 915 MHU_SET_HudRotateLvl 2;
BA_ "InvalidValue" SG_ 915 MHU_SET_HudRotateLvl "Fh";
BA_ "GenSigSendType" SG_ 915 MHU_SET_HudHeightLvl 2;
BA_ "InvalidValue" SG_ 915 MHU_SET_HudHeightLvl "0h";
BA_ "GenSigSendType" SG_ 919 MHU_Immo_ADAS_Byte_0 2;
BA_ "GenSigSendType" SG_ 919 MHU_Immo_ADAS_Byte_1 2;
BA_ "GenSigSendType" SG_ 919 MHU_Immo_ADAS_Byte_2 2;
BA_ "GenSigSendType" SG_ 919 MHU_Immo_ADAS_Byte_3 2;
BA_ "GenSigSendType" SG_ 919 MHU_Immo_ADAS_Byte_4 2;
BA_ "GenSigSendType" SG_ 919 MHU_Immo_ADAS_Byte_5 2;
BA_ "GenSigSendType" SG_ 919 MHU_Immo_ADAS_Byte_6 2;
BA_ "GenSigSendType" SG_ 919 MHU_Immo_ADAS_Byte_7 2;
BA_ "GenSigSendType" SG_ 922 MHU_Immo_Byte_0 2;
BA_ "InvalidValue" SG_ 922 MHU_Immo_Byte_0 "null";
BA_ "GenSigSendType" SG_ 922 MHU_Immo_Byte_1 2;
BA_ "InvalidValue" SG_ 922 MHU_Immo_Byte_1 "null";
BA_ "GenSigSendType" SG_ 922 MHU_Immo_Byte_2 2;
BA_ "InvalidValue" SG_ 922 MHU_Immo_Byte_2 "null";
BA_ "GenSigSendType" SG_ 922 MHU_Immo_Byte_3 2;
BA_ "InvalidValue" SG_ 922 MHU_Immo_Byte_3 "null";
BA_ "GenSigSendType" SG_ 922 MHU_Immo_Byte_4 2;
BA_ "InvalidValue" SG_ 922 MHU_Immo_Byte_4 "null";
BA_ "GenSigSendType" SG_ 922 MHU_Immo_Byte_5 2;
BA_ "InvalidValue" SG_ 922 MHU_Immo_Byte_5 "null";
BA_ "GenSigSendType" SG_ 922 MHU_Immo_Byte_6 2;
BA_ "InvalidValue" SG_ 922 MHU_Immo_Byte_6 "null";
BA_ "GenSigSendType" SG_ 922 MHU_Immo_Byte_7 2;
BA_ "InvalidValue" SG_ 922 MHU_Immo_Byte_7 "null";
BA_ "GenSigSendType" SG_ 923 BCM_Immo_MHU_Byte_0 2;
BA_ "InvalidValue" SG_ 923 BCM_Immo_MHU_Byte_0 "null";
BA_ "GenSigSendType" SG_ 923 BCM_Immo_MHU_Byte_1 2;
BA_ "InvalidValue" SG_ 923 BCM_Immo_MHU_Byte_1 "null";
BA_ "GenSigSendType" SG_ 923 BCM_Immo_MHU_Byte_2 2;
BA_ "InvalidValue" SG_ 923 BCM_Immo_MHU_Byte_2 "null";
BA_ "GenSigSendType" SG_ 923 BCM_Immo_MHU_Byte_3 2;
BA_ "InvalidValue" SG_ 923 BCM_Immo_MHU_Byte_3 "null";
BA_ "GenSigSendType" SG_ 923 BCM_Immo_MHU_Byte_4 2;
BA_ "InvalidValue" SG_ 923 BCM_Immo_MHU_Byte_4 "null";
BA_ "GenSigSendType" SG_ 923 BCM_Immo_MHU_Byte_5 2;
BA_ "InvalidValue" SG_ 923 BCM_Immo_MHU_Byte_5 "null";
BA_ "GenSigSendType" SG_ 923 BCM_Immo_MHU_Byte_6 2;
BA_ "InvalidValue" SG_ 923 BCM_Immo_MHU_Byte_6 "null";
BA_ "GenSigSendType" SG_ 923 BCM_Immo_MHU_Byte_7 2;
BA_ "InvalidValue" SG_ 923 BCM_Immo_MHU_Byte_7 "null";
BA_ "GenSigTimeoutTime_ALL" SG_ 925 BCM_AHB_Override 500;
BA_ "InvalidValue" SG_ 925 BCM_AHB_Override "3h";
BA_ "GenSigSendType" SG_ 943 MHU_UTF8Character_Byte1 1;
BA_ "InvalidValue" SG_ 943 MHU_UTF8Character_Byte1 "FFh";
BA_ "GenSigSendType" SG_ 943 MHU_UTF8Character_Byte2 1;
BA_ "InvalidValue" SG_ 943 MHU_UTF8Character_Byte2 "FFh";
BA_ "GenSigSendType" SG_ 943 MHU_UTF8Character_Byte3 1;
BA_ "InvalidValue" SG_ 943 MHU_UTF8Character_Byte3 "FFh";
BA_ "GenSigSendType" SG_ 943 MHU_UTF8Character_Byte4 1;
BA_ "InvalidValue" SG_ 943 MHU_UTF8Character_Byte4 "FFh";
BA_ "GenSigSendType" SG_ 943 MHU_UTF8Character_Byte5 1;
BA_ "InvalidValue" SG_ 943 MHU_UTF8Character_Byte5 "FFh";
BA_ "GenSigSendType" SG_ 943 MHU_UTF8Character_Byte6 1;
BA_ "InvalidValue" SG_ 943 MHU_UTF8Character_Byte6 "FFh";
BA_ "GenSigSendType" SG_ 943 MHU_IPC_ID 1;
BA_ "InvalidValue" SG_ 943 MHU_IPC_ID "Fh";
BA_ "GenSigSendType" SG_ 943 MHU_TotalMessages 1;
BA_ "GenSigStartValue" SG_ 943 MHU_TotalMessages 1;
BA_ "InvalidValue" SG_ 943 MHU_TotalMessages "Fh";
BA_ "GenSigSendType" SG_ 943 MHU_MessageNumber 1;
BA_ "GenSigStartValue" SG_ 943 MHU_MessageNumber 1;
BA_ "InvalidValue" SG_ 943 MHU_MessageNumber "Fh";
BA_ "GenSigSendType" SG_ 964 MHU_Nav_State 1;
BA_ "InvalidValue" SG_ 964 MHU_Nav_State "7h";
BA_ "GenSigSendType" SG_ 964 MHU_NavSource 1;
BA_ "InvalidValue" SG_ 964 MHU_NavSource "7h";
BA_ "GenSigSendType" SG_ 964 MHU_Nav_DistanceToNextTurn 1;
BA_ "GenSigSendType" SG_ 964 MHU_Nav_DistanceToNextTurnUnits 1;
BA_ "GenSigSendType" SG_ 964 MHU_Nav_TBT_Icon 1;
BA_ "GenSigSendType" SG_ 964 MHU_Nav_ImageChannel_Ready 1;
BA_ "GenSigSendType" SG_ 964 MHU_Nav_Language 1;
BA_ "InvalidValue" SG_ 964 MHU_Nav_Language "FFh";
BA_ "GenSigSendType" SG_ 964 SECCAN_NAV_DISP 1;
BA_ "GenSigSendType" SG_ 965 MHU_NavGuidance_TotalMsg 1;
BA_ "GenSigSendType" SG_ 965 MHU_NavGuidance_MsgNum 1;
BA_ "GenSigSendType" SG_ 965 MHU_NavGuidance_UTF8_Byte1 1;
BA_ "GenSigSendType" SG_ 965 MHU_NavGuidance_UTF8_Byte2 1;
BA_ "GenSigSendType" SG_ 965 MHU_NavGuidance_UTF8_Byte3 1;
BA_ "GenSigSendType" SG_ 965 MHU_NavGuidance_UTF8_Byte4 1;
BA_ "GenSigSendType" SG_ 965 MHU_NavGuidance_UTF8_Byte5 1;
BA_ "GenSigSendType" SG_ 965 MHU_NavGuidance_UTF8_Byte6 1;
BA_ "GenSigSendType" SG_ 966 MHU_NavDist_MsgNum 1;
BA_ "GenSigSendType" SG_ 966 MHU_NavDist_TotalMsg 1;
BA_ "GenSigSendType" SG_ 966 MHU_NavDist_UTF8_Byte1 1;
BA_ "GenSigSendType" SG_ 966 MHU_NavDist_UTF8_Byte2 1;
BA_ "GenSigSendType" SG_ 966 MHU_NavDist_UTF8_Byte3 1;
BA_ "GenSigSendType" SG_ 966 MHU_NavDist_UTF8_Byte4 1;
BA_ "GenSigSendType" SG_ 966 MHU_NavDist_UTF8_Byte5 1;
BA_ "GenSigSendType" SG_ 966 MHU_NavDist_UTF8_Byte6 1;
BA_ "GenSigTimeoutTime_ALL" SG_ 992 CRC_VCU_HVsystem_status 200;
BA_ "GenSigTimeoutTime_ALL" SG_ 992 CRC_VCU_HVsystem_status 200;
BA_ "InvalidValue" SG_ 992 CRC_VCU_HVsystem_status "null";
BA_ "GenSigTimeoutTime_ALL" SG_ 992 ALIV_VCU_HVsystem_status 200;
BA_ "GenSigTimeoutTime_ALL" SG_ 992 ALIV_VCU_HVsystem_status 200;
BA_ "InvalidValue" SG_ 992 ALIV_VCU_HVsystem_status "Fh";
BA_ "GenSigTimeoutTime_ALL" SG_ 992 VCU_RunningRange 200;
BA_ "GenSigTimeoutTime_ALL" SG_ 992 VCU_RunningRange 200;
BA_ "InvalidValue" SG_ 992 VCU_RunningRange "null";
BA_ "GenSigTimeoutTime_ALL" SG_ 992 VCU_RunningRange_chrg_estSts 200;
BA_ "GenSigTimeoutTime_ALL" SG_ 992 VCU_RunningRange_chrg_estSts 200;
BA_ "InvalidValue" SG_ 992 VCU_RunningRange_chrg_estSts "null";
BA_ "GenSigTimeoutTime_ALL" SG_ 992 VCU_RunningRange_charged 200;
BA_ "GenSigTimeoutTime_ALL" SG_ 992 VCU_RunningRange_charged 200;
BA_ "InvalidValue" SG_ 992 VCU_RunningRange_charged "null";
BA_ "GenSigTimeoutTime_ALL" SG_ 992 VCU_HVbatSoc_charged 200;
BA_ "GenSigTimeoutTime_ALL" SG_ 992 VCU_HVbatSoc_charged 200;
BA_ "InvalidValue" SG_ 992 VCU_HVbatSoc_charged "null";
BA_ "GenSigTimeoutTime_ALL" SG_ 992 VCU_HVbatSoc_charged_estStatus 200;
BA_ "GenSigTimeoutTime_ALL" SG_ 992 VCU_HVbatSoc_charged_estStatus 200;
BA_ "InvalidValue" SG_ 992 VCU_HVbatSoc_charged_estStatus "null";
BA_ "GenSigTimeoutTime_ALL" SG_ 993 CRC_VCU_HMI_Info 500;
BA_ "GenSigTimeoutTime_ALL" SG_ 993 CRC_VCU_HMI_Info 500;
BA_ "InvalidValue" SG_ 993 CRC_VCU_HMI_Info "null";
BA_ "GenSigTimeoutTime_ALL" SG_ 993 ALIV_VCU_HMI_Info 500;
BA_ "GenSigTimeoutTime_ALL" SG_ 993 ALIV_VCU_HMI_Info 500;
BA_ "InvalidValue" SG_ 993 ALIV_VCU_HMI_Info "Fh";
BA_ "GenSigStartValue" SG_ 993 VCU_MHU_Ack_ChgSche_stt 3;
BA_ "GenSigTimeoutTime_ALL" SG_ 993 VCU_MHU_Ack_ChgSche_stt 500;
BA_ "InvalidValue" SG_ 993 VCU_MHU_Ack_ChgSche_stt "3h";
BA_ "GenSigStartValue" SG_ 993 VCU_MHU_Ack_TargetSOC 100;
BA_ "GenSigTimeoutTime_ALL" SG_ 993 VCU_MHU_Ack_TargetSOC 500;
BA_ "GenSigTimeoutTime_ALL" SG_ 993 VCU_MHU_Ack_TargetSOC 500;
BA_ "InvalidValue" SG_ 993 VCU_MHU_Ack_TargetSOC "7Fh";
BA_ "GenSigTimeoutTime_ALL" SG_ 993 VCU_ValetMode_sts 500;
BA_ "InvalidValue" SG_ 993 VCU_ValetMode_sts "FFh";
BA_ "GenSigTimeoutTime_ALL" SG_ 993 VCU_ValetMode_MaxSpeedSts 500;
BA_ "InvalidValue" SG_ 993 VCU_ValetMode_MaxSpeedSts "FFh";
BA_ "GenSigTimeoutTime_ALL" SG_ 993 SECCAN_VCU_HMI_Info 500;
BA_ "InvalidValue" SG_ 993 SECCAN_VCU_HMI_Info "null";
BA_ "GenSigSendType" SG_ 1015 CHSKM_MFS_Control_Button 4;
BA_ "GenSigTimeoutTime_ALL" SG_ 1015 CHSKM_MFS_Control_Button 5000;
BA_ "InvalidValue" SG_ 1015 CHSKM_MFS_Control_Button "null";
BA_ "GenSigSendType" SG_ 1015 ALV_MFS_Control_Button 4;
BA_ "GenSigTimeoutTime_ALL" SG_ 1015 ALV_MFS_Control_Button 5000;
BA_ "InvalidValue" SG_ 1015 ALV_MFS_Control_Button "Fh";
BA_ "GenSigSendType" SG_ 1015 MFS_VoiceRecognitionOn_Off 4;
BA_ "GenSigTimeoutTime_ALL" SG_ 1015 MFS_VoiceRecognitionOn_Off 5000;
BA_ "InvalidValue" SG_ 1015 MFS_VoiceRecognitionOn_Off "null";
BA_ "GenSigSendType" SG_ 1015 MFS_ISAControl 4;
BA_ "GenSigTimeoutTime_ALL" SG_ 1015 MFS_ISAControl 5000;
BA_ "InvalidValue" SG_ 1015 MFS_ISAControl "null";
BA_ "GenSigSendType" SG_ 1015 MFS_CruiseSpeedIncrease 4;
BA_ "GenSigTimeoutTime_ALL" SG_ 1015 MFS_CruiseSpeedIncrease 5000;
BA_ "InvalidValue" SG_ 1015 MFS_CruiseSpeedIncrease "null";
BA_ "GenSigSendType" SG_ 1015 MFS_TelephoneCall_EndCall 4;
BA_ "GenSigTimeoutTime_ALL" SG_ 1015 MFS_TelephoneCall_EndCall 5000;
BA_ "InvalidValue" SG_ 1015 MFS_TelephoneCall_EndCall "null";
BA_ "GenSigSendType" SG_ 1015 MFS_LKAControl 4;
BA_ "GenSigTimeoutTime_ALL" SG_ 1015 MFS_LKAControl 5000;
BA_ "InvalidValue" SG_ 1015 MFS_LKAControl "null";
BA_ "GenSigSendType" SG_ 1015 MFS_CruiseGapIncrease 4;
BA_ "GenSigTimeoutTime_ALL" SG_ 1015 MFS_CruiseGapIncrease 5000;
BA_ "InvalidValue" SG_ 1015 MFS_CruiseGapIncrease "null";
BA_ "GenSigSendType" SG_ 1015 MFS_CruiseOn_Off 4;
BA_ "GenSigTimeoutTime_ALL" SG_ 1015 MFS_CruiseOn_Off 5000;
BA_ "InvalidValue" SG_ 1015 MFS_CruiseOn_Off "null";
BA_ "GenSigSendType" SG_ 1015 MFS_CruiseGapDecrease 4;
BA_ "GenSigTimeoutTime_ALL" SG_ 1015 MFS_CruiseGapDecrease 5000;
BA_ "InvalidValue" SG_ 1015 MFS_CruiseGapDecrease "null";
BA_ "GenSigSendType" SG_ 1015 MFS_CAN_RESControl 4;
BA_ "GenSigTimeoutTime_ALL" SG_ 1015 MFS_CAN_RESControl 5000;
BA_ "InvalidValue" SG_ 1015 MFS_CAN_RESControl "3h";
BA_ "GenSigSendType" SG_ 1015 MFS_CruiseSpeedDecrease 4;
BA_ "GenSigTimeoutTime_ALL" SG_ 1015 MFS_CruiseSpeedDecrease 5000;
BA_ "InvalidValue" SG_ 1015 MFS_CruiseSpeedDecrease "null";
BA_ "GenSigSendType" SG_ 1015 MFS_M2Control 4;
BA_ "GenSigTimeoutTime_ALL" SG_ 1015 MFS_M2Control 5000;
BA_ "InvalidValue" SG_ 1015 MFS_M2Control "null";
BA_ "GenSigSendType" SG_ 1015 MFS_SourseControl 4;
BA_ "GenSigTimeoutTime_ALL" SG_ 1015 MFS_SourseControl 5000;
BA_ "InvalidValue" SG_ 1015 MFS_SourseControl "null";
BA_ "GenSigSendType" SG_ 1015 MFS_UpControl 4;
BA_ "GenSigTimeoutTime_ALL" SG_ 1015 MFS_UpControl 5000;
BA_ "InvalidValue" SG_ 1015 MFS_UpControl "null";
BA_ "GenSigSendType" SG_ 1015 MFS_DownControl 4;
BA_ "GenSigTimeoutTime_ALL" SG_ 1015 MFS_DownControl 5000;
BA_ "InvalidValue" SG_ 1015 MFS_DownControl "null";
BA_ "GenSigSendType" SG_ 1015 MFS_LeftControl 4;
BA_ "GenSigTimeoutTime_ALL" SG_ 1015 MFS_LeftControl 5000;
BA_ "InvalidValue" SG_ 1015 MFS_LeftControl "null";
BA_ "GenSigSendType" SG_ 1015 MFS_Failure 4;
BA_ "GenSigTimeoutTime_ALL" SG_ 1015 MFS_Failure 5000;
BA_ "InvalidValue" SG_ 1015 MFS_Failure "null";
BA_ "GenSigSendType" SG_ 1015 MFS_RightControl 4;
BA_ "GenSigTimeoutTime_ALL" SG_ 1015 MFS_RightControl 5000;
BA_ "InvalidValue" SG_ 1015 MFS_RightControl "null";
BA_ "GenSigSendType" SG_ 1015 MFS_OK_Control 4;
BA_ "GenSigTimeoutTime_ALL" SG_ 1015 MFS_OK_Control 5000;
BA_ "InvalidValue" SG_ 1015 MFS_OK_Control "null";
BA_ "GenSigTimeoutTime_ALL" SG_ 1020 CRC_XGW_FOTA_StsConfirm 2500;
BA_ "GenSigTimeoutTime_ALL" SG_ 1020 ALIV_XGW_FOTA_StsConfirm 2500;
BA_ "InvalidValue" SG_ 1020 ALIV_XGW_FOTA_StsConfirm "Fh";
BA_ "GenSigTimeoutTime_ALL" SG_ 1020 XGW_FOTA_StateConfirm 2500;
BA_ "GenSigTimeoutTime_ALL" SG_ 1020 XGW_FOTA_Error_Code 2500;
BA_ "GenSigSendType" SG_ 1025 MHU_SET_SunroofGlassLevel 2;
BA_ "GenSigStartValue" SG_ 1025 MHU_SET_SunroofGlassLevel 255;
BA_ "InvalidValue" SG_ 1025 MHU_SET_SunroofGlassLevel "7Fh";
BA_ "GenSigSendType" SG_ 1025 MHU_SET_BonnetState 2;
BA_ "InvalidValue" SG_ 1025 MHU_SET_BonnetState "3h";
BA_ "GenSigSendType" SG_ 1025 MHU_SET_TrunkState 2;
BA_ "InvalidValue" SG_ 1025 MHU_SET_TrunkState "3h";
BA_ "GenSigSendType" SG_ 1025 MHU_SET_SunroofShaderLevel 2;
BA_ "GenSigStartValue" SG_ 1025 MHU_SET_SunroofShaderLevel 255;
BA_ "InvalidValue" SG_ 1025 MHU_SET_SunroofShaderLevel "7Fh";
BA_ "GenSigSendType" SG_ 1025 MHU_SET_DoorSpeedLock 2;
BA_ "GenSigStartValue" SG_ 1025 MHU_SET_DoorSpeedLock 6;
BA_ "InvalidValue" SG_ 1025 MHU_SET_DoorSpeedLock "6h";
BA_ "GenSigSendType" SG_ 1025 MHU_SET_WelcomeTriggerCondition 2;
BA_ "GenSigStartValue" SG_ 1025 MHU_SET_WelcomeTriggerCondition 3;
BA_ "InvalidValue" SG_ 1025 MHU_SET_WelcomeTriggerCondition "3h";
BA_ "GenSigSendType" SG_ 1025 MHU_SET_AutoSunroof 2;
BA_ "GenSigStartValue" SG_ 1025 MHU_SET_AutoSunroof 3;
BA_ "InvalidValue" SG_ 1025 MHU_SET_AutoSunroof "3h";
BA_ "GenSigSendType" SG_ 1025 MHU_SET_RemoteDoorUnlock 2;
BA_ "GenSigStartValue" SG_ 1025 MHU_SET_RemoteDoorUnlock 3;
BA_ "InvalidValue" SG_ 1025 MHU_SET_RemoteDoorUnlock "3h";
BA_ "GenSigSendType" SG_ 1025 MHU_SET_RemoteLockFeedback 2;
BA_ "GenSigStartValue" SG_ 1025 MHU_SET_RemoteLockFeedback 4;
BA_ "InvalidValue" SG_ 1025 MHU_SET_RemoteLockFeedback "4h";
BA_ "GenSigSendType" SG_ 1025 MHU_SET_FootkickSensor 2;
BA_ "GenSigStartValue" SG_ 1025 MHU_SET_FootkickSensor 3;
BA_ "InvalidValue" SG_ 1025 MHU_SET_FootkickSensor "3h";
BA_ "GenSigSendType" SG_ 1025 MHU_SET_AutoUnlockDoor 2;
BA_ "GenSigStartValue" SG_ 1025 MHU_SET_AutoUnlockDoor 3;
BA_ "InvalidValue" SG_ 1025 MHU_SET_AutoUnlockDoor "3h";
BA_ "GenSigSendType" SG_ 1025 MHU_SET_RemoteUnlockFeedback 2;
BA_ "GenSigStartValue" SG_ 1025 MHU_SET_RemoteUnlockFeedback 4;
BA_ "InvalidValue" SG_ 1025 MHU_SET_RemoteUnlockFeedback "4h";
BA_ "GenSigSendType" SG_ 1025 MHU_SET_Childlock 2;
BA_ "InvalidValue" SG_ 1025 MHU_SET_Childlock "null";
BA_ "GenSigSendType" SG_ 1025 MHU_SET_SunroofInitialize 2;
BA_ "InvalidValue" SG_ 1025 MHU_SET_SunroofInitialize "7h";
BA_ "GenSigSendType" SG_ 1025 WalkawayDoorLock 2;
BA_ "GenSigSendType" SG_ 1026 MHU_SET_DayTimeRunningLight 2;
BA_ "GenSigStartValue" SG_ 1026 MHU_SET_DayTimeRunningLight 1;
BA_ "InvalidValue" SG_ 1026 MHU_SET_DayTimeRunningLight "3h";
BA_ "GenSigSendType" SG_ 1026 MHU_SET_RearFogLight 2;
BA_ "GenSigStartValue" SG_ 1026 MHU_SET_RearFogLight 3;
BA_ "InvalidValue" SG_ 1026 MHU_SET_RearFogLight "3h";
BA_ "GenSigSendType" SG_ 1026 MHU_SET_FrontFogLight 2;
BA_ "GenSigStartValue" SG_ 1026 MHU_SET_FrontFogLight 3;
BA_ "InvalidValue" SG_ 1026 MHU_SET_FrontFogLight "3h";
BA_ "GenSigSendType" SG_ 1026 MHU_SET_WelcomeDimmingHeadlight 2;
BA_ "GenSigStartValue" SG_ 1026 MHU_SET_WelcomeDimmingHeadlight 3;
BA_ "InvalidValue" SG_ 1026 MHU_SET_WelcomeDimmingHeadlight "3h";
BA_ "GenSigSendType" SG_ 1026 MHU_SET_AmbientLightBrighness 2;
BA_ "InvalidValue" SG_ 1026 MHU_SET_AmbientLightBrighness "7Fh";
BA_ "GenSigSendType" SG_ 1026 MHU_SET_FootwellLightMode 2;
BA_ "GenSigStartValue" SG_ 1026 MHU_SET_FootwellLightMode 2;
BA_ "InvalidValue" SG_ 1026 MHU_SET_FootwellLightMode "3h";
BA_ "GenSigSendType" SG_ 1026 MHU_SET_ExteriorLight 2;
BA_ "GenSigStartValue" SG_ 1026 MHU_SET_ExteriorLight 4;
BA_ "InvalidValue" SG_ 1026 MHU_SET_ExteriorLight "4h";
BA_ "GenSigSendType" SG_ 1026 MHU_SET_TRWarningSignals 2;
BA_ "GenSigStartValue" SG_ 1026 MHU_SET_TRWarningSignals 3;
BA_ "InvalidValue" SG_ 1026 MHU_SET_TRWarningSignals "3h";
BA_ "GenSigSendType" SG_ 1026 MHU_SET_FrontDomeLamp 2;
BA_ "GenSigStartValue" SG_ 1026 MHU_SET_FrontDomeLamp 3;
BA_ "InvalidValue" SG_ 1026 MHU_SET_FrontDomeLamp "3h";
BA_ "GenSigSendType" SG_ 1026 MHU_SET_SwitchLightBrightness 2;
BA_ "GenSigStartValue" SG_ 1026 MHU_SET_SwitchLightBrightness 80;
BA_ "InvalidValue" SG_ 1026 MHU_SET_SwitchLightBrightness "4h";
BA_ "GenSigSendType" SG_ 1026 MHU_SET_HazardLight 2;
BA_ "InvalidValue" SG_ 1026 MHU_SET_HazardLight "3h";
BA_ "GenSigTimeoutTime_ALL" SG_ 1026 MHU_SET_HazardLight 500;
BA_ "GenSigSendType" SG_ 1026 MHU_SET_FollowMeHome 2;
BA_ "InvalidValue" SG_ 1026 MHU_SET_FollowMeHome "5h";
BA_ "GenSigSendType" SG_ 1026 MHU_SET_ADB_AHB 2;
BA_ "InvalidValue" SG_ 1026 MHU_SET_ADB_AHB "3h";
BA_ "GenSigSendType" SG_ 1026 MHU_SET_WelcomeAnimation 2;
BA_ "InvalidValue" SG_ 1026 MHU_SET_WelcomeAnimation "null";
BA_ "GenSigSendType" SG_ 1026 MHU_SET_ChargingAnimation 2;
BA_ "InvalidValue" SG_ 1026 MHU_SET_ChargingAnimation "null";
BA_ "GenSigSendType" SG_ 1026 MHU_SET_Auto_Leveling 2;
BA_ "GenSigStartValue" SG_ 1026 MHU_SET_Auto_Leveling 1;
BA_ "InvalidValue" SG_ 1026 MHU_SET_Auto_Leveling "3h";
BA_ "GenSigTimeoutTime_ALL" SG_ 1027 CHKSM_MHU_EVSetting 500;
BA_ "InvalidValue" SG_ 1027 CHKSM_MHU_EVSetting "null";
BA_ "GenSigTimeoutTime_ALL" SG_ 1027 ALV_MHU_EVSetting 500;
BA_ "InvalidValue" SG_ 1027 ALV_MHU_EVSetting "Fh";
BA_ "GenSigStartValue" SG_ 1027 MHU_AutoP_Setting 2;
BA_ "GenSigTimeoutTime_ALL" SG_ 1027 MHU_AutoP_Setting 500;
BA_ "InvalidValue" SG_ 1027 MHU_AutoP_Setting "3h";
BA_ "GenSigTimeoutTime_ALL" SG_ 1027 MHU_VCU_CreepDisable_stt 500;
BA_ "InvalidValue" SG_ 1027 MHU_VCU_CreepDisable_stt "null";
BA_ "GenSigTimeoutTime_ALL" SG_ 1027 MHU_BrakeRegenMode 500;
BA_ "InvalidValue" SG_ 1027 MHU_BrakeRegenMode "";
BA_ "GenSigStartValue" SG_ 1027 MHU_ChargeSetTargetSOC 80;
BA_ "GenSigTimeoutTime_ALL" SG_ 1027 MHU_ChargeSetTargetSOC 500;
BA_ "InvalidValue" SG_ 1027 MHU_ChargeSetTargetSOC "7Fh";
BA_ "GenSigStartValue" SG_ 1027 MHU_ChargeScheduleSet 2;
BA_ "GenSigTimeoutTime_ALL" SG_ 1027 MHU_ChargeScheduleSet 500;
BA_ "InvalidValue" SG_ 1027 MHU_ChargeScheduleSet "3h";
BA_ "GenSigStartValue" SG_ 1027 MHU_ChargingRequest 3;
BA_ "GenSigTimeoutTime_ALL" SG_ 1027 MHU_ChargingRequest 500;
BA_ "InvalidValue" SG_ 1027 MHU_ChargingRequest "null";
BA_ "GenSigTimeoutTime_ALL" SG_ 1027 MHU_ChgPort_Open_req 500;
BA_ "InvalidValue" SG_ 1027 MHU_ChgPort_Open_req "3h";
BA_ "GenSigStartValue" SG_ 1027 MHU_SET_DrivingModeSwitch 3;
BA_ "GenSigTimeoutTime_ALL" SG_ 1027 MHU_SET_DrivingModeSwitch 500;
BA_ "InvalidValue" SG_ 1027 MHU_SET_DrivingModeSwitch "3h";
BA_ "GenSigStartValue" SG_ 1027 MHU_ValetMode_Activation 2;
BA_ "GenSigTimeoutTime_ALL" SG_ 1027 MHU_ValetMode_Activation 500;
BA_ "InvalidValue" SG_ 1027 MHU_ValetMode_Activation "FFh";
BA_ "GenSigStartValue" SG_ 1027 MHU_ValetMode_MaxSpeed 255;
BA_ "GenSigTimeoutTime_ALL" SG_ 1027 MHU_ValetMode_MaxSpeed 500;
BA_ "InvalidValue" SG_ 1027 MHU_ValetMode_MaxSpeed "FFh";
BA_ "GenSigStartValue" SG_ 1027 MHU_ChargingCurrentLimit 6;
BA_ "GenSigTimeoutTime_ALL" SG_ 1027 MHU_ChargingCurrentLimit 500;
BA_ "InvalidValue" SG_ 1027 MHU_ChargingCurrentLimit "3Fh";
BA_ "GenSigTimeoutTime_ALL" SG_ 1027 MHU_SET_ActivePreCondition 500;
BA_ "InvalidValue" SG_ 1027 MHU_SET_ActivePreCondition "3h";
BA_ "GenSigSendType" SG_ 1028 MHU_SET_LeftMirrorPosX 2;
BA_ "GenSigStartValue" SG_ 1028 MHU_SET_LeftMirrorPosX 15;
BA_ "InvalidValue" SG_ 1028 MHU_SET_LeftMirrorPosX "FFh";
BA_ "GenSigSendType" SG_ 1028 MHU_SET_LeftMirrorPosY 2;
BA_ "GenSigStartValue" SG_ 1028 MHU_SET_LeftMirrorPosY 15;
BA_ "InvalidValue" SG_ 1028 MHU_SET_LeftMirrorPosY "FFh";
BA_ "GenSigSendType" SG_ 1028 MHU_SET_RightMirrorPosX 2;
BA_ "GenSigStartValue" SG_ 1028 MHU_SET_RightMirrorPosX 15;
BA_ "InvalidValue" SG_ 1028 MHU_SET_RightMirrorPosX "FFh";
BA_ "GenSigSendType" SG_ 1028 MHU_SET_RightMirrorPosY 2;
BA_ "GenSigStartValue" SG_ 1028 MHU_SET_RightMirrorPosY 15;
BA_ "InvalidValue" SG_ 1028 MHU_SET_RightMirrorPosY "FFh";
BA_ "GenSigSendType" SG_ 1028 MHU_SET_MirrorAdjustLeft 2;
BA_ "InvalidValue" SG_ 1028 MHU_SET_MirrorAdjustLeft "3h";
BA_ "GenSigSendType" SG_ 1028 MHU_SET_MirrorAdjustRight 2;
BA_ "InvalidValue" SG_ 1028 MHU_SET_MirrorAdjustRight "3h";
BA_ "GenSigSendType" SG_ 1028 MHU_SET_MirrorManual 2;
BA_ "GenSigStartValue" SG_ 1028 MHU_SET_MirrorManual 3;
BA_ "InvalidValue" SG_ 1028 MHU_SET_MirrorManual "3h";
BA_ "GenSigSendType" SG_ 1028 SECCAN_MirrorAdj 2;
BA_ "InvalidValue" SG_ 1028 SECCAN_MirrorAdj "null";
BA_ "GenSigSendType" SG_ 1029 MHU_SET_CCUF_AirCondition 2;
BA_ "InvalidValue" SG_ 1029 MHU_SET_CCUF_AirCondition "3h";
BA_ "GenSigSendType" SG_ 1029 MHU_SET_CCUF_AutoAC 2;
BA_ "InvalidValue" SG_ 1029 MHU_SET_CCUF_AutoAC "3h";
BA_ "GenSigSendType" SG_ 1029 MHU_SET_CCUF_MaxAc 2;
BA_ "InvalidValue" SG_ 1029 MHU_SET_CCUF_MaxAc "3h";
BA_ "GenSigSendType" SG_ 1029 MHU_SET_CCUF_FanSpeed 2;
BA_ "GenSigStartValue" SG_ 1029 MHU_SET_CCUF_FanSpeed 3;
BA_ "InvalidValue" SG_ 1029 MHU_SET_CCUF_FanSpeed "7h";
BA_ "GenSigSendType" SG_ 1029 MHU_SET_CCUF_Recirculation 2;
BA_ "GenSigStartValue" SG_ 1029 MHU_SET_CCUF_Recirculation 1;
BA_ "InvalidValue" SG_ 1029 MHU_SET_CCUF_Recirculation "3h";
BA_ "GenSigSendType" SG_ 1029 MHU_SET_CCUF_Ion 2;
BA_ "InvalidValue" SG_ 1029 MHU_SET_CCUF_Ion "3h";
BA_ "GenSigSendType" SG_ 1029 MHU_SET_CCUF_FlapPosition 2;
BA_ "InvalidValue" SG_ 1029 MHU_SET_CCUF_FlapPosition "4h";
BA_ "GenSigSendType" SG_ 1029 MHU_SET_CCUF_SyncClimateZone 2;
BA_ "InvalidValue" SG_ 1029 MHU_SET_CCUF_SyncClimateZone "3h";
BA_ "GenSigSendType" SG_ 1029 MHU_SET_CCUF_TempDriver 2;
BA_ "GenSigStartValue" SG_ 1029 MHU_SET_CCUF_TempDriver 40;
BA_ "InvalidValue" SG_ 1029 MHU_SET_CCUF_TempDriver "FFh";
BA_ "GenSigSendType" SG_ 1029 MHU_SET_CCUF_TempPassenger 2;
BA_ "GenSigStartValue" SG_ 1029 MHU_SET_CCUF_TempPassenger 40;
BA_ "InvalidValue" SG_ 1029 MHU_SET_CCUF_TempPassenger "FFh";
BA_ "GenSigSendType" SG_ 1029 MHU_SET_CCUF_FrontDefrost 2;
BA_ "InvalidValue" SG_ 1029 MHU_SET_CCUF_FrontDefrost "3h";
BA_ "GenSigSendType" SG_ 1030 MHU_SET_SeatHeatingFrontL 2;
BA_ "InvalidValue" SG_ 1030 MHU_SET_SeatHeatingFrontL "4h";
BA_ "GenSigSendType" SG_ 1030 MHU_SET_SeatHeatingFrontR 2;
BA_ "InvalidValue" SG_ 1030 MHU_SET_SeatHeatingFrontR "4h";
BA_ "GenSigSendType" SG_ 1030 MHU_SET_SeatHeatingReartL 2;
BA_ "InvalidValue" SG_ 1030 MHU_SET_SeatHeatingReartL "4h";
BA_ "GenSigSendType" SG_ 1030 MHU_SET_SeatHeatingRearR 2;
BA_ "InvalidValue" SG_ 1030 MHU_SET_SeatHeatingRearR "4h";
BA_ "GenSigSendType" SG_ 1030 MHU_SET_SeatCoolingFrontL 2;
BA_ "InvalidValue" SG_ 1030 MHU_SET_SeatCoolingFrontL "4h";
BA_ "GenSigSendType" SG_ 1030 MHU_SET_SeatCoolingFrontR 2;
BA_ "InvalidValue" SG_ 1030 MHU_SET_SeatCoolingFrontR "4h";
BA_ "GenSigSendType" SG_ 1030 MHU_SET_SeatCoolingRearL 2;
BA_ "InvalidValue" SG_ 1030 MHU_SET_SeatCoolingRearL "4h";
BA_ "GenSigSendType" SG_ 1030 MHU_SET_SeatCoolingRearR 2;
BA_ "InvalidValue" SG_ 1030 MHU_SET_SeatCoolingRearR "4h";
BA_ "GenSigSendType" SG_ 1032 MHU_SET_MirrorAuto 2;
BA_ "GenSigStartValue" SG_ 1032 MHU_SET_MirrorAuto 3;
BA_ "InvalidValue" SG_ 1032 MHU_SET_MirrorAuto "3h";
BA_ "GenSigSendType" SG_ 1032 MHU_SET_MirrorAutoUnfold 2;
BA_ "GenSigStartValue" SG_ 1032 MHU_SET_MirrorAutoUnfold 3;
BA_ "InvalidValue" SG_ 1032 MHU_SET_MirrorAutoUnfold "3h";
BA_ "GenSigSendType" SG_ 1032 MHU_SET_WLC 2;
BA_ "GenSigStartValue" SG_ 1032 MHU_SET_WLC 3;
BA_ "InvalidValue" SG_ 1032 MHU_SET_WLC "3h";
BA_ "GenSigSendType" SG_ 1032 MHU_SET_AutoRearWiper 2;
BA_ "GenSigStartValue" SG_ 1032 MHU_SET_AutoRearWiper 3;
BA_ "InvalidValue" SG_ 1032 MHU_SET_AutoRearWiper "3h";
BA_ "GenSigSendType" SG_ 1032 MHU_SET_RearHeatedWindow 2;
BA_ "InvalidValue" SG_ 1032 MHU_SET_RearHeatedWindow "3h";
BA_ "GenSigSendType" SG_ 1032 MHU_TPMSReset 2;
BA_ "InvalidValue" SG_ 1032 MHU_TPMSReset "3h";
BA_ "GenSigSendType" SG_ 1032 MHU_SET_MirrorDefaultSetting 2;
BA_ "GenSigStartValue" SG_ 1032 MHU_SET_MirrorDefaultSetting 3;
BA_ "InvalidValue" SG_ 1032 MHU_SET_MirrorDefaultSetting "3h";
BA_ "GenSigSendType" SG_ 1032 MHU_SET_MirrorReverseLink 2;
BA_ "GenSigStartValue" SG_ 1032 MHU_SET_MirrorReverseLink 1;
BA_ "GenSigSendType" SG_ 1032 MHU_SET_AntiTheftMode 2;
BA_ "GenSigStartValue" SG_ 1032 MHU_SET_AntiTheftMode 3;
BA_ "InvalidValue" SG_ 1032 MHU_SET_AntiTheftMode "3h";
BA_ "GenSigSendType" SG_ 1032 MHU_SET_WLCReminder 2;
BA_ "GenSigStartValue" SG_ 1032 MHU_SET_WLCReminder 1;
BA_ "InvalidValue" SG_ 1032 MHU_SET_WLCReminder "3h";
BA_ "GenSigSendType" SG_ 1032 MHU_SET_ClimateKeepOn 2;
BA_ "InvalidValue" SG_ 1032 MHU_SET_ClimateKeepOn "null";
BA_ "GenSigSendType" SG_ 1032 MHU_SET_WLC2 2;
BA_ "GenSigStartValue" SG_ 1032 MHU_SET_WLC2 1;
BA_ "InvalidValue" SG_ 1032 MHU_SET_WLC2 "3h";
BA_ "GenSigSendType" SG_ 1032 MHU_SET_WLC2Reminder 2;
BA_ "GenSigStartValue" SG_ 1032 MHU_SET_WLC2Reminder 1;
BA_ "InvalidValue" SG_ 1032 MHU_SET_WLC2Reminder "3h";
BA_ "GenSigSendType" SG_ 1032 MHU_IntrusionAlertStatus 2;
BA_ "GenSigStartValue" SG_ 1032 MHU_IntrusionAlertStatus 3;
BA_ "InvalidValue" SG_ 1032 MHU_IntrusionAlertStatus "3h";
BA_ "GenSigSendType" SG_ 1033 CHSKM_ADAS_WarnMsg 3;
BA_ "GenSigTimeoutTime_ALL" SG_ 1033 CHSKM_ADAS_WarnMsg 5000;
BA_ "GenSigSendType" SG_ 1033 ALV_ADAS_WarnMsg 3;
BA_ "GenSigTimeoutTime_ALL" SG_ 1033 ALV_ADAS_WarnMsg 5000;
BA_ "InvalidValue" SG_ 1033 ALV_ADAS_WarnMsg "Fh";
BA_ "GenSigSendType" SG_ 1033 ADAS_Warning_Flag_1 4;
BA_ "GenSigTimeoutTime_ALL" SG_ 1033 ADAS_Warning_Flag_1 5000;
BA_ "GenSigSendType" SG_ 1033 ADAS_Warning_Flag_2 4;
BA_ "GenSigTimeoutTime_ALL" SG_ 1033 ADAS_Warning_Flag_2 5000;
BA_ "GenSigSendType" SG_ 1033 ADAS_Warning_Flag_3 4;
BA_ "GenSigTimeoutTime_ALL" SG_ 1033 ADAS_Warning_Flag_3 5000;
BA_ "GenSigSendType" SG_ 1033 ADAS_Warning_Flag_4 4;
BA_ "GenSigTimeoutTime_ALL" SG_ 1033 ADAS_Warning_Flag_4 5000;
BA_ "GenSigSendType" SG_ 1033 ADAS_Warning_Flag_5 4;
BA_ "GenSigTimeoutTime_ALL" SG_ 1033 ADAS_Warning_Flag_5 5000;
BA_ "GenSigSendType" SG_ 1033 ADAS_Warning_Flag_6 4;
BA_ "GenSigTimeoutTime_ALL" SG_ 1033 ADAS_Warning_Flag_6 5000;
BA_ "GenSigSendType" SG_ 1033 ADAS_Warning_Flag_7 4;
BA_ "GenSigTimeoutTime_ALL" SG_ 1033 ADAS_Warning_Flag_7 5000;
BA_ "GenSigSendType" SG_ 1033 ADAS_Warning_Flag_8 4;
BA_ "GenSigTimeoutTime_ALL" SG_ 1033 ADAS_Warning_Flag_8 5000;
BA_ "GenSigSendType" SG_ 1033 ADAS_Warning_Flag_9 4;
BA_ "GenSigTimeoutTime_ALL" SG_ 1033 ADAS_Warning_Flag_9 5000;
BA_ "GenSigSendType" SG_ 1033 ADAS_Warning_Flag_10 4;
BA_ "GenSigTimeoutTime_ALL" SG_ 1033 ADAS_Warning_Flag_10 5000;
BA_ "GenSigSendType" SG_ 1033 ADAS_Warning_Flag_11 4;
BA_ "GenSigTimeoutTime_ALL" SG_ 1033 ADAS_Warning_Flag_11 5000;
BA_ "GenSigSendType" SG_ 1033 ADAS_Warning_Flag_12 4;
BA_ "GenSigTimeoutTime_ALL" SG_ 1033 ADAS_Warning_Flag_12 5000;
BA_ "GenSigSendType" SG_ 1033 ADAS_Warning_Flag_13 4;
BA_ "GenSigTimeoutTime_ALL" SG_ 1033 ADAS_Warning_Flag_13 5000;
BA_ "GenSigSendType" SG_ 1033 ADAS_Warning_Flag_14 4;
BA_ "GenSigTimeoutTime_ALL" SG_ 1033 ADAS_Warning_Flag_14 5000;
BA_ "GenSigSendType" SG_ 1033 ADAS_Warning_Flag_15 4;
BA_ "GenSigTimeoutTime_ALL" SG_ 1033 ADAS_Warning_Flag_15 5000;
BA_ "GenSigSendType" SG_ 1033 ADAS_Warning_Flag_16 4;
BA_ "GenSigTimeoutTime_ALL" SG_ 1033 ADAS_Warning_Flag_16 5000;
BA_ "GenSigSendType" SG_ 1033 ADAS_Warning_Flag_17 4;
BA_ "GenSigTimeoutTime_ALL" SG_ 1033 ADAS_Warning_Flag_17 5000;
BA_ "GenSigSendType" SG_ 1033 ADAS_Warning_Flag_18 4;
BA_ "GenSigTimeoutTime_ALL" SG_ 1033 ADAS_Warning_Flag_18 5000;
BA_ "GenSigSendType" SG_ 1033 ADAS_Warning_Flag_19 4;
BA_ "GenSigTimeoutTime_ALL" SG_ 1033 ADAS_Warning_Flag_19 5000;
BA_ "GenSigSendType" SG_ 1033 ADAS_Warning_Flag_20 4;
BA_ "GenSigTimeoutTime_ALL" SG_ 1033 ADAS_Warning_Flag_20 5000;
BA_ "GenSigSendType" SG_ 1033 ADAS_Warning_Flag_21 4;
BA_ "GenSigTimeoutTime_ALL" SG_ 1033 ADAS_Warning_Flag_21 5000;
BA_ "GenSigSendType" SG_ 1033 ADAS_Warning_Flag_22 4;
BA_ "GenSigTimeoutTime_ALL" SG_ 1033 ADAS_Warning_Flag_22 5000;
BA_ "GenSigSendType" SG_ 1033 ADAS_Warning_Flag_23 4;
BA_ "GenSigTimeoutTime_ALL" SG_ 1033 ADAS_Warning_Flag_23 5000;
BA_ "GenSigSendType" SG_ 1033 ADAS_Warning_Flag_24 4;
BA_ "GenSigTimeoutTime_ALL" SG_ 1033 ADAS_Warning_Flag_24 5000;
BA_ "GenSigSendType" SG_ 1033 ADAS_Warning_Flag_25 4;
BA_ "GenSigTimeoutTime_ALL" SG_ 1033 ADAS_Warning_Flag_25 5000;
BA_ "GenSigSendType" SG_ 1033 ADAS_Warning_Flag_26 4;
BA_ "GenSigTimeoutTime_ALL" SG_ 1033 ADAS_Warning_Flag_26 5000;
BA_ "GenSigSendType" SG_ 1033 ADAS_Warning_Flag_27 4;
BA_ "GenSigTimeoutTime_ALL" SG_ 1033 ADAS_Warning_Flag_27 5000;
BA_ "GenSigSendType" SG_ 1033 ADAS_Warning_Flag_28 4;
BA_ "GenSigTimeoutTime_ALL" SG_ 1033 ADAS_Warning_Flag_28 5000;
BA_ "GenSigSendType" SG_ 1033 ADAS_Warning_Flag_29 4;
BA_ "GenSigTimeoutTime_ALL" SG_ 1033 ADAS_Warning_Flag_29 5000;
BA_ "GenSigSendType" SG_ 1033 ADAS_Warning_Flag_30 4;
BA_ "GenSigTimeoutTime_ALL" SG_ 1033 ADAS_Warning_Flag_30 5000;
BA_ "GenSigSendType" SG_ 1033 ADAS_Warning_Flag_31 4;
BA_ "GenSigTimeoutTime_ALL" SG_ 1033 ADAS_Warning_Flag_31 5000;
BA_ "GenSigSendType" SG_ 1033 ADAS_Warning_Flag_32 4;
BA_ "GenSigTimeoutTime_ALL" SG_ 1033 ADAS_Warning_Flag_32 5000;
BA_ "GenSigSendType" SG_ 1033 ADAS_Warning_Flag_33 4;
BA_ "GenSigTimeoutTime_ALL" SG_ 1033 ADAS_Warning_Flag_33 5000;
BA_ "GenSigSendType" SG_ 1033 ADAS_Warning_Flag_34 4;
BA_ "GenSigTimeoutTime_ALL" SG_ 1033 ADAS_Warning_Flag_34 5000;
BA_ "GenSigSendType" SG_ 1033 ADAS_Warning_Flag_35 4;
BA_ "GenSigTimeoutTime_ALL" SG_ 1033 ADAS_Warning_Flag_35 5000;
BA_ "GenSigSendType" SG_ 1033 ADAS_Warning_Flag_36 4;
BA_ "GenSigTimeoutTime_ALL" SG_ 1033 ADAS_Warning_Flag_36 5000;
BA_ "GenSigSendType" SG_ 1033 ADAS_Warning_Flag_37 4;
BA_ "GenSigTimeoutTime_ALL" SG_ 1033 ADAS_Warning_Flag_37 5000;
BA_ "GenSigSendType" SG_ 1033 ADAS_Warning_Flag_38 4;
BA_ "GenSigTimeoutTime_ALL" SG_ 1033 ADAS_Warning_Flag_38 5000;
BA_ "GenSigSendType" SG_ 1033 ADAS_Warning_Flag_39 4;
BA_ "GenSigTimeoutTime_ALL" SG_ 1033 ADAS_Warning_Flag_39 5000;
BA_ "GenSigSendType" SG_ 1033 ADAS_Warning_Flag_40 4;
BA_ "GenSigTimeoutTime_ALL" SG_ 1033 ADAS_Warning_Flag_40 5000;
BA_ "GenSigSendType" SG_ 1033 ADAS_Warning_Flag_41 4;
BA_ "GenSigTimeoutTime_ALL" SG_ 1033 ADAS_Warning_Flag_41 5000;
BA_ "GenSigSendType" SG_ 1033 ADAS_Warning_Flag_42 4;
BA_ "GenSigTimeoutTime_ALL" SG_ 1033 ADAS_Warning_Flag_42 5000;
BA_ "GenSigSendType" SG_ 1033 ADAS_Warning_Flag_43 4;
BA_ "GenSigTimeoutTime_ALL" SG_ 1033 ADAS_Warning_Flag_43 5000;
BA_ "GenSigSendType" SG_ 1033 ADAS_Warning_Flag_44 4;
BA_ "GenSigTimeoutTime_ALL" SG_ 1033 ADAS_Warning_Flag_44 5000;
BA_ "GenSigSendType" SG_ 1033 ADAS_Warning_Flag_45 4;
BA_ "GenSigTimeoutTime_ALL" SG_ 1033 ADAS_Warning_Flag_45 5000;
BA_ "GenSigSendType" SG_ 1033 ADAS_Warning_Flag_46 4;
BA_ "GenSigTimeoutTime_ALL" SG_ 1033 ADAS_Warning_Flag_46 5000;
BA_ "GenSigSendType" SG_ 1033 ADAS_Warning_Flag_47 4;
BA_ "GenSigTimeoutTime_ALL" SG_ 1033 ADAS_Warning_Flag_47 5000;
BA_ "GenSigSendType" SG_ 1033 ADAS_Warning_Flag_48 4;
BA_ "GenSigTimeoutTime_ALL" SG_ 1033 ADAS_Warning_Flag_48 5000;
BA_ "GenSigSendType" SG_ 1033 ADAS_Warning_Flag_49 4;
BA_ "GenSigTimeoutTime_ALL" SG_ 1033 ADAS_Warning_Flag_49 5000;
BA_ "GenSigSendType" SG_ 1033 ADAS_Warning_Flag_50 4;
BA_ "GenSigTimeoutTime_ALL" SG_ 1033 ADAS_Warning_Flag_50 5000;
BA_ "GenSigSendType" SG_ 1033 ADAS_Warning_Flag_51 4;
BA_ "GenSigTimeoutTime_ALL" SG_ 1033 ADAS_Warning_Flag_51 5000;
BA_ "GenSigSendType" SG_ 1033 ADAS_Warning_Flag_52 4;
BA_ "GenSigTimeoutTime_ALL" SG_ 1033 ADAS_Warning_Flag_52 5000;
BA_ "GenSigSendType" SG_ 1034 MHU_SET_HudUIContent 2;
BA_ "InvalidValue" SG_ 1034 MHU_SET_HudUIContent "7h";
BA_ "GenSigSendType" SG_ 1034 MHU_SET_HudUIColor 2;
BA_ "GenSigSendType" SG_ 1034 MHU_SET_HudScreenOnOFF 2;
BA_ "GenSigStartValue" SG_ 1034 MHU_SET_HudScreenOnOFF 1;
BA_ "InvalidValue" SG_ 1034 MHU_SET_HudScreenOnOFF "3h";
BA_ "GenSigSendType" SG_ 1034 MHU_SET_UserBrightnessLvl 2;
BA_ "InvalidValue" SG_ 1034 MHU_SET_UserBrightnessLvl "Fh";
BA_ "GenSigSendType" SG_ 1034 MHU_SET_HudWorkingMode 2;
BA_ "InvalidValue" SG_ 1034 MHU_SET_HudWorkingMode "3h";
BA_ "GenSigSendType" SG_ 1034 MHU_SET_HudUISize 2;
BA_ "GenSigSendType" SG_ 1034 MHU_SET_UIContentMediaInfo 2;
BA_ "GenSigSendType" SG_ 1034 MHU_SET_UIContentCallInfo 2;
BA_ "GenSigSendType" SG_ 1034 MHU_SET_UIContentPoweRegen 2;
BA_ "GenSigSendType" SG_ 1034 MHU_SET_HudTurnSigOnOff 4;
BA_ "GenSigSendType" SG_ 1034 MHU_SET_HudBSDOnOff 4;
BA_ "GenSigSendType" SG_ 1034 MHU_SET_HudRCTAOnOff 4;
BA_ "GenSigSendType" SG_ 1035 MHU_SET_AvasSound 2;
BA_ "GenSigStartValue" SG_ 1035 MHU_SET_AvasSound 1;
BA_ "GenSigTimeoutTime_ALL" SG_ 1036 CHSKM_MHU_SEAT_CONTROL 1000;
BA_ "InvalidValue" SG_ 1036 CHSKM_MHU_SEAT_CONTROL "null";
BA_ "GenSigTimeoutTime_ALL" SG_ 1036 ALV_MHU_SEAT_CONTROL 1000;
BA_ "InvalidValue" SG_ 1036 ALV_MHU_SEAT_CONTROL "Fh";
BA_ "GenSigTimeoutTime_ALL" SG_ 1036 MHU_DrvSeat_Control_Status 1000;
BA_ "InvalidValue" SG_ 1036 MHU_DrvSeat_Control_Status "7h";
BA_ "GenSigTimeoutTime_ALL" SG_ 1036 MHU_ExpDrvReclinerPos 1000;
BA_ "InvalidValue" SG_ 1036 MHU_ExpDrvReclinerPos "7Fh";
BA_ "GenSigTimeoutTime_ALL" SG_ 1036 MHU_ExpDrvTiltPos 1000;
BA_ "InvalidValue" SG_ 1036 MHU_ExpDrvTiltPos "1Fh";
BA_ "GenSigTimeoutTime_ALL" SG_ 1036 MHU_ExpDrvTrackPos 1000;
BA_ "InvalidValue" SG_ 1036 MHU_ExpDrvTrackPos "FFh";
BA_ "GenSigTimeoutTime_ALL" SG_ 1036 MHU_ExpDrvHeightPos 1000;
BA_ "InvalidValue" SG_ 1036 MHU_ExpDrvHeightPos "3Fh";
BA_ "GenSigTimeoutTime_ALL" SG_ 1037 CHKSM_MHU_DIGIT_SPEED 1500;
BA_ "GenSigTimeoutTime_ALL" SG_ 1037 ALV_MHU_DIGIT_SPEED 1500;
BA_ "InvalidValue" SG_ 1037 ALV_MHU_DIGIT_SPEED "Fh";
BA_ "GenSigTimeoutTime_ALL" SG_ 1037 MHU_DigitSpeed 1500;
BA_ "InvalidValue" SG_ 1037 MHU_DigitSpeed "1FFh";
BA_ "GenSigTimeoutTime_ALL" SG_ 1038 AveragePwrConsumpTripA 5000;
BA_ "GenSigTimeoutTime_ALL" SG_ 1038 AverageFuelConsumpTripA 5000;
BA_ "GenSigTimeoutTime_ALL" SG_ 1038 AvarageSpeedTripA 5000;
BA_ "InvalidValue" SG_ 1038 AvarageSpeedTripA "1FFh";
BA_ "GenSigTimeoutTime_ALL" SG_ 1038 TripA 5000;
BA_ "InvalidValue" SG_ 1038 TripA "1FFFFh";
BA_ "GenSigTimeoutTime_ALL" SG_ 1039 AveragePwrConsumpTripB 5000;
BA_ "GenSigTimeoutTime_ALL" SG_ 1039 AverageFuelConsumpTripB 5000;
BA_ "GenSigTimeoutTime_ALL" SG_ 1039 AvarageSpeedTripB 5000;
BA_ "InvalidValue" SG_ 1039 AvarageSpeedTripB "1FFh";
BA_ "GenSigTimeoutTime_ALL" SG_ 1039 TripB 5000;
BA_ "InvalidValue" SG_ 1039 TripB "1FFFFh";
BA_ "GenSigTimeoutTime_ALL" SG_ 1040 AveragePwrConsumpTripAuto 5000;
BA_ "GenSigTimeoutTime_ALL" SG_ 1040 AverageFuelConsumpTripAuto 5000;
BA_ "GenSigTimeoutTime_ALL" SG_ 1040 AvarageSpeedTripAuto 5000;
BA_ "InvalidValue" SG_ 1040 AvarageSpeedTripAuto "1FFh";
BA_ "GenSigTimeoutTime_ALL" SG_ 1040 TripAuto 5000;
BA_ "InvalidValue" SG_ 1040 TripAuto "1FFFFh";
BA_ "GenSigStartValue" SG_ 1046 BCM_STAT_LeftMirrorPosX 15;
BA_ "GenSigTimeoutTime_ALL" SG_ 1046 BCM_STAT_LeftMirrorPosX 500;
BA_ "GenSigTimeoutTime_ALL" SG_ 1046 BCM_STAT_LeftMirrorPosX 500;
BA_ "InvalidValue" SG_ 1046 BCM_STAT_LeftMirrorPosX "FFh";
BA_ "GenSigStartValue" SG_ 1046 BCM_STAT_LeftMirrorPosY 15;
BA_ "GenSigTimeoutTime_ALL" SG_ 1046 BCM_STAT_LeftMirrorPosY 500;
BA_ "GenSigTimeoutTime_ALL" SG_ 1046 BCM_STAT_LeftMirrorPosY 500;
BA_ "InvalidValue" SG_ 1046 BCM_STAT_LeftMirrorPosY "FFh";
BA_ "GenSigStartValue" SG_ 1046 BCM_STAT_RightMirrorPosX 15;
BA_ "GenSigTimeoutTime_ALL" SG_ 1046 BCM_STAT_RightMirrorPosX 500;
BA_ "GenSigTimeoutTime_ALL" SG_ 1046 BCM_STAT_RightMirrorPosX 500;
BA_ "InvalidValue" SG_ 1046 BCM_STAT_RightMirrorPosX "FFh";
BA_ "GenSigStartValue" SG_ 1046 BCM_STAT_RightMirrorPosY 15;
BA_ "GenSigTimeoutTime_ALL" SG_ 1046 BCM_STAT_RightMirrorPosY 500;
BA_ "GenSigTimeoutTime_ALL" SG_ 1046 BCM_STAT_RightMirrorPosY 500;
BA_ "InvalidValue" SG_ 1046 BCM_STAT_RightMirrorPosY "FFh";
BA_ "GenSigTimeoutTime_ALL" SG_ 1046 BCM_STAT_Mirror 500;
BA_ "GenSigTimeoutTime_ALL" SG_ 1046 BCM_STAT_Mirror 500;
BA_ "InvalidValue" SG_ 1046 BCM_STAT_Mirror "3h";
BA_ "GenSigTimeoutTime_ALL" SG_ 1046 BCM_STAT_MirrorAdjustLeft 500;
BA_ "GenSigTimeoutTime_ALL" SG_ 1046 BCM_STAT_MirrorAdjustLeft 500;
BA_ "InvalidValue" SG_ 1046 BCM_STAT_MirrorAdjustLeft "3h";
BA_ "GenSigTimeoutTime_ALL" SG_ 1046 BCM_STAT_MirrorAdjustRight 500;
BA_ "GenSigTimeoutTime_ALL" SG_ 1046 BCM_STAT_MirrorAdjustRight 500;
BA_ "InvalidValue" SG_ 1046 BCM_STAT_MirrorAdjustRight "3h";
BA_ "GenSigSendType" SG_ 1049 SHVU_STAT_SeatHeatingFrontL 3;
BA_ "InvalidValue" SG_ 1049 SHVU_STAT_SeatHeatingFrontL "4h";
BA_ "GenSigSendType" SG_ 1049 SHVU_STAT_SeatHeatingFrontR 3;
BA_ "InvalidValue" SG_ 1049 SHVU_STAT_SeatHeatingFrontR "4h";
BA_ "GenSigSendType" SG_ 1049 SHVU_STAT_SeatCoolingFrontL 3;
BA_ "InvalidValue" SG_ 1049 SHVU_STAT_SeatCoolingFrontL "4h";
BA_ "GenSigSendType" SG_ 1049 SHVU_STAT_SeatCoolingFrontR 3;
BA_ "InvalidValue" SG_ 1049 SHVU_STAT_SeatCoolingFrontR "4h";
BA_ "GenSigSendType" SG_ 1049 SHVU_STAT_FrontSeatVentSts 3;
BA_ "InvalidValue" SG_ 1049 SHVU_STAT_FrontSeatVentSts "3h";
BA_ "GenSigSendType" SG_ 1050 SHVU_STAT_SeatCoolingRearL 3;
BA_ "InvalidValue" SG_ 1050 SHVU_STAT_SeatCoolingRearL "4h";
BA_ "GenSigSendType" SG_ 1050 SHVU_STAT_SeatCoolingRearR 3;
BA_ "InvalidValue" SG_ 1050 SHVU_STAT_SeatCoolingRearR "4h";
BA_ "GenSigSendType" SG_ 1050 SHVU_STAT_SeatHeatingReartL 3;
BA_ "InvalidValue" SG_ 1050 SHVU_STAT_SeatHeatingReartL "4h";
BA_ "GenSigSendType" SG_ 1050 SHVU_STAT_SeatHeatingRearR 3;
BA_ "InvalidValue" SG_ 1050 SHVU_STAT_SeatHeatingRearR "4h";
BA_ "GenSigSendType" SG_ 1050 SHVU_STAT_RearSeatVentSts 3;
BA_ "InvalidValue" SG_ 1050 SHVU_STAT_RearSeatVentSts "3h";
BA_ "GenSigTimeoutTime_ALL" SG_ 1052 CHKSM_PSM_SEAT_POSITION 5000;
BA_ "GenSigTimeoutTime_ALL" SG_ 1052 AVL_PSM_SEAT_POSITION 5000;
BA_ "InvalidValue" SG_ 1052 AVL_PSM_SEAT_POSITION "Fh";
BA_ "GenSigTimeoutTime_ALL" SG_ 1052 PSM_Seat_track_pos_Dri 5000;
BA_ "InvalidValue" SG_ 1052 PSM_Seat_track_pos_Dri "3h";
BA_ "GenSigTimeoutTime_ALL" SG_ 1052 PSM_Seat_track_posPas 5000;
BA_ "InvalidValue" SG_ 1052 PSM_Seat_track_posPas "3h";
BA_ "GenSigStartValue" SG_ 1053 BCM_STAT_AutoRearWiper 1;
BA_ "GenSigTimeoutTime_ALL" SG_ 1053 BCM_STAT_AutoRearWiper 500;
BA_ "InvalidValue" SG_ 1053 BCM_STAT_AutoRearWiper "3h";
BA_ "GenSigStartValue" SG_ 1053 BCM_STAT_MirrorFoldSetting 3;
BA_ "GenSigTimeoutTime_ALL" SG_ 1053 BCM_STAT_MirrorFoldSetting 500;
BA_ "InvalidValue" SG_ 1053 BCM_STAT_MirrorFoldSetting "3h";
BA_ "GenSigTimeoutTime_ALL" SG_ 1053 BCM_STAT_IMMO_KeyfobID2 500;
BA_ "InvalidValue" SG_ 1053 BCM_STAT_IMMO_KeyfobID2 "7h";
BA_ "GenSigTimeoutTime_ALL" SG_ 1053 BCM_STAT_MirrorAutoUnfold 500;
BA_ "InvalidValue" SG_ 1053 BCM_STAT_MirrorAutoUnfold "3h";
BA_ "GenSigStartValue" SG_ 1053 BCM_STAT_MirrorReverseLink 1;
BA_ "GenSigTimeoutTime_ALL" SG_ 1053 BCM_STAT_MirrorReverseLink 500;
BA_ "GenSigTimeoutTime_ALL" SG_ 1053 BCM_STAT_MirrorDefaultSTATting 500;
BA_ "InvalidValue" SG_ 1053 BCM_STAT_MirrorDefaultSTATting "3h";
BA_ "GenSigTimeoutTime_ALL" SG_ 1053 BCM_STAT_WelcomeTriggerCondition 500;
BA_ "InvalidValue" SG_ 1053 BCM_STAT_WelcomeTriggerCondition "3h";
BA_ "GenSigStartValue" SG_ 1053 BCM_STAT_FrontDomeLamp 1;
BA_ "GenSigTimeoutTime_ALL" SG_ 1053 BCM_STAT_FrontDomeLamp 500;
BA_ "InvalidValue" SG_ 1053 BCM_STAT_FrontDomeLamp "3h";
BA_ "GenSigTimeoutTime_ALL" SG_ 1053 BCM_STAT_FollowMeHome 500;
BA_ "InvalidValue" SG_ 1053 BCM_STAT_FollowMeHome "5h";
BA_ "GenSigTimeoutTime_ALL" SG_ 1053 BCM_STAT_ExteriorLight 500;
BA_ "InvalidValue" SG_ 1053 BCM_STAT_ExteriorLight "4h";
BA_ "GenSigStartValue" SG_ 1053 BCM_STAT_RemoteLockFeedback 7;
BA_ "GenSigTimeoutTime_ALL" SG_ 1053 BCM_STAT_RemoteLockFeedback 500;
BA_ "InvalidValue" SG_ 1053 BCM_STAT_RemoteLockFeedback "7h";
BA_ "GenSigStartValue" SG_ 1053 BCM_STAT_RemoteDoorUnlock 3;
BA_ "GenSigTimeoutTime_ALL" SG_ 1053 BCM_STAT_RemoteDoorUnlock 500;
BA_ "InvalidValue" SG_ 1053 BCM_STAT_RemoteDoorUnlock "3h";
BA_ "GenSigStartValue" SG_ 1053 BCM_STAT_AutoDoorUnlock 3;
BA_ "GenSigTimeoutTime_ALL" SG_ 1053 BCM_STAT_AutoDoorUnlock 500;
BA_ "InvalidValue" SG_ 1053 BCM_STAT_AutoDoorUnlock "3h";
BA_ "GenSigTimeoutTime_ALL" SG_ 1053 BCM_STAT_WalkawayDoorLock 500;
BA_ "GenSigSendType" SG_ 1053 BCM_STAT_WalkawayDoorLock 2;
BA_ "GenSigStartValue" SG_ 1053 BCM_STAT_AmbientLightBrighness 80;
BA_ "GenSigTimeoutTime_ALL" SG_ 1053 BCM_STAT_AmbientLightBrighness 500;
BA_ "InvalidValue" SG_ 1053 BCM_STAT_AmbientLightBrighness "7Fh";
BA_ "GenSigStartValue" SG_ 1053 BCM_STAT_WiperServiceMode 3;
BA_ "GenSigTimeoutTime_ALL" SG_ 1053 BCM_STAT_WiperServiceMode 500;
BA_ "InvalidValue" SG_ 1053 BCM_STAT_WiperServiceMode "3h";
BA_ "GenSigStartValue" SG_ 1053 BCM_STAT_IMMO_KeyfobID 3;
BA_ "GenSigTimeoutTime_ALL" SG_ 1053 BCM_STAT_IMMO_KeyfobID 500;
BA_ "InvalidValue" SG_ 1053 BCM_STAT_IMMO_KeyfobID "3h";
BA_ "GenSigTimeoutTime_ALL" SG_ 1053 BCM_STAT_RearHeatedWindowMirror 500;
BA_ "InvalidValue" SG_ 1053 BCM_STAT_RearHeatedWindowMirror "3h";
BA_ "GenSigStartValue" SG_ 1053 BCM_STAT_AntiTheftMode 3;
BA_ "GenSigTimeoutTime_ALL" SG_ 1053 BCM_STAT_AntiTheftMode 500;
BA_ "InvalidValue" SG_ 1053 BCM_STAT_AntiTheftMode "4h";
BA_ "GenSigTimeoutTime_ALL" SG_ 1053 BCM_STAT_ClimateKeepOnSts 500;
BA_ "InvalidValue" SG_ 1053 BCM_STAT_ClimateKeepOnSts "null";
BA_ "GenSigTimeoutTime_ALL" SG_ 1053 BCM_STAT_FKSfeedback 500;
BA_ "InvalidValue" SG_ 1053 BCM_STAT_FKSfeedback "3h";
BA_ "GenSigTimeoutTime_ALL" SG_ 1053 SECCAN_CmftCnfrm 500;
BA_ "GenSigTimeoutTime_ALL" SG_ 1053 SECCAN_CmftCnfrm 500;
BA_ "InvalidValue" SG_ 1053 SECCAN_CmftCnfrm "null";
BA_ "GenSigTimeoutTime_ALL" SG_ 1054 HUD_UIColor 1500;
BA_ "GenSigTimeoutTime_ALL" SG_ 1054 HUD_UIContent 1500;
BA_ "GenSigTimeoutTime_ALL" SG_ 1054 HUD_OperationState 1500;
BA_ "GenSigStartValue" SG_ 1054 HUD_HeightLvl 11;
BA_ "GenSigTimeoutTime_ALL" SG_ 1054 HUD_HeightLvl 1500;
BA_ "GenSigTimeoutTime_ALL" SG_ 1054 HUD_UI_Size 1500;
BA_ "GenSigTimeoutTime_ALL" SG_ 1054 HUD_UIContentMediaInfo 1500;
BA_ "GenSigTimeoutTime_ALL" SG_ 1054 HUD_UIContentCallInfor 1500;
BA_ "GenSigTimeoutTime_ALL" SG_ 1054 HUD_UIContentPowerRegen 1500;
BA_ "GenSigTimeoutTime_ALL" SG_ 1054 HUD_UIModeSignal 1500;
BA_ "InvalidValue" SG_ 1054 HUD_UIModeSignal "7h";
BA_ "GenSigTimeoutTime_ALL" SG_ 1054 HUD_WorkingMode 1500;
BA_ "GenSigTimeoutTime_ALL" SG_ 1054 HUD_ActualBrightnes 1500;
BA_ "GenSigTimeoutTime_ALL" SG_ 1054 HUD_RotateAngleLvl 1500;
BA_ "GenSigStartValue" SG_ 1054 HUD_UserSetBrightnessLvl 5;
BA_ "GenSigTimeoutTime_ALL" SG_ 1054 HUD_UserSetBrightnessLvl 1500;
BA_ "GenSigTimeoutTime_ALL" SG_ 1054 HUD_Language 1500;
BA_ "GenSigSendType" SG_ 1054 HUD_TurnSigOnOff_Feed 4;
BA_ "GenSigTimeoutTime_ALL" SG_ 1054 HUD_TurnSigOnOff_Feed 1500;
BA_ "GenSigSendType" SG_ 1054 HUD_BSDOnOff_Feed 4;
BA_ "GenSigTimeoutTime_ALL" SG_ 1054 HUD_BSDOnOff_Feed 1500;
BA_ "GenSigSendType" SG_ 1054 HUD_RCTAOnOff_Feed 4;
BA_ "GenSigTimeoutTime_ALL" SG_ 1054 HUD_RCTAOnOff_Feed 1500;
BA_ "GenSigTimeoutTime_ALL" SG_ 1054 HUD_Mileage_Unit 1500;
BA_ "GenSigStartValue" SG_ 1054 HUD_UserProfileId 1;
BA_ "GenSigTimeoutTime_ALL" SG_ 1054 HUD_UserProfileId 1500;
BA_ "InvalidValue" SG_ 1054 HUD_UserProfileId "Fh";
BA_ "GenSigTimeoutTime_ALL" SG_ 1054 HUD_DimmingDelayTime 1500;
BA_ "GenSigTimeoutTime_ALL" SG_ 1055 CHKSM_SensorFault 1500;
BA_ "GenSigTimeoutTime_ALL" SG_ 1055 ALV_Sensor_Fault 1500;
BA_ "InvalidValue" SG_ 1055 ALV_Sensor_Fault "Fh";
BA_ "GenSigTimeoutTime_ALL" SG_ 1055 ADAS_SVM_LCamera_Fault 1500;
BA_ "InvalidValue" SG_ 1055 ADAS_SVM_LCamera_Fault "3h";
BA_ "GenSigTimeoutTime_ALL" SG_ 1055 ADAS_USS_Front_Fault 1500;
BA_ "GenSigTimeoutTime_ALL" SG_ 1055 ADAS_SVM_FCamera_Fault 1500;
BA_ "InvalidValue" SG_ 1055 ADAS_SVM_FCamera_Fault "3h";
BA_ "GenSigTimeoutTime_ALL" SG_ 1055 ADAS_SRR_RR_Fault 1500;
BA_ "InvalidValue" SG_ 1055 ADAS_SRR_RR_Fault "3h";
BA_ "GenSigTimeoutTime_ALL" SG_ 1055 ADAS_SRR_FR_Fault 1500;
BA_ "InvalidValue" SG_ 1055 ADAS_SRR_FR_Fault "3h";
BA_ "GenSigTimeoutTime_ALL" SG_ 1055 ADAS_SVM_RCamera_Fault 1500;
BA_ "InvalidValue" SG_ 1055 ADAS_SVM_RCamera_Fault "3h";
BA_ "GenSigTimeoutTime_ALL" SG_ 1055 ADAS_USS_Rear_Fault 1500;
BA_ "GenSigTimeoutTime_ALL" SG_ 1055 ADAS_SCAM_Fault 1500;
BA_ "InvalidValue" SG_ 1055 ADAS_SCAM_Fault "3h";
BA_ "GenSigTimeoutTime_ALL" SG_ 1055 ADAS_MRR_Fault 1500;
BA_ "InvalidValue" SG_ 1055 ADAS_MRR_Fault "3h";
BA_ "GenSigTimeoutTime_ALL" SG_ 1055 ADAS_SRR_RL_Fault 1500;
BA_ "InvalidValue" SG_ 1055 ADAS_SRR_RL_Fault "3h";
BA_ "GenSigTimeoutTime_ALL" SG_ 1055 ADAS_SVM_RightCamera_Fault 1500;
BA_ "InvalidValue" SG_ 1055 ADAS_SVM_RightCamera_Fault "3h";
BA_ "GenSigTimeoutTime_ALL" SG_ 1055 ADAS_ECU_Fault 1500;
BA_ "InvalidValue" SG_ 1055 ADAS_ECU_Fault "3h";
BA_ "GenSigTimeoutTime_ALL" SG_ 1055 ADAS_SRR_FL_Fault 1500;
BA_ "InvalidValue" SG_ 1055 ADAS_SRR_FL_Fault "3h";
BA_ "GenSigTimeoutTime_ALL" SG_ 1055 ADAS_APAUSS_Rear_Fault 1500;
BA_ "InvalidValue" SG_ 1055 ADAS_APAUSS_Rear_Fault "3h";
BA_ "GenSigTimeoutTime_ALL" SG_ 1055 ADAS_APAUSS_Front_Fault 1500;
BA_ "InvalidValue" SG_ 1055 ADAS_APAUSS_Front_Fault "3h";
BA_ "GenSigTimeoutTime_ALL" SG_ 1055 SECCAN_SensorFault 1500;
BA_ "GenSigTimeoutTime_ALL" SG_ 1058 CHKSM_MHU_STAT 5000;
BA_ "InvalidValue" SG_ 1058 CHKSM_MHU_STAT "null";
BA_ "GenSigTimeoutTime_ALL" SG_ 1058 ALV_MHU_STAT 5000;
BA_ "InvalidValue" SG_ 1058 ALV_MHU_STAT "Fh";
BA_ "GenSigTimeoutTime_ALL" SG_ 1058 MHU_STAT_Cluster 5000;
BA_ "InvalidValue" SG_ 1058 MHU_STAT_Cluster "3h";
BA_ "GenSigTimeoutTime_ALL" SG_ 1058 MHU_STAT_Infotainment 5000;
BA_ "InvalidValue" SG_ 1058 MHU_STAT_Infotainment "3h";
BA_ "GenSigStartValue" SG_ 1058 MHU_STAT_MileageUnit 3;
BA_ "GenSigTimeoutTime_ALL" SG_ 1058 MHU_STAT_MileageUnit 5000;
BA_ "InvalidValue" SG_ 1058 MHU_STAT_MileageUnit "3h";
BA_ "GenSigStartValue" SG_ 1058 MHU_STAT_PressureUnit 3;
BA_ "GenSigTimeoutTime_ALL" SG_ 1058 MHU_STAT_PressureUnit 5000;
BA_ "InvalidValue" SG_ 1058 MHU_STAT_PressureUnit "3h";
BA_ "GenSigStartValue" SG_ 1058 MHU_STAT_TemperatureUnit 3;
BA_ "GenSigTimeoutTime_ALL" SG_ 1058 MHU_STAT_TemperatureUnit 5000;
BA_ "InvalidValue" SG_ 1058 MHU_STAT_TemperatureUnit "3h";
BA_ "GenSigStartValue" SG_ 1058 MHU_STAT_DateTimeFormat 3;
BA_ "GenSigTimeoutTime_ALL" SG_ 1058 MHU_STAT_DateTimeFormat 5000;
BA_ "InvalidValue" SG_ 1058 MHU_STAT_DateTimeFormat "3h";
BA_ "GenSigTimeoutTime_ALL" SG_ 1058 MHU_Operation_State 5000;
BA_ "InvalidValue" SG_ 1058 MHU_Operation_State "7h";
BA_ "GenSigStartValue" SG_ 1058 MHU_STAT_Language 31;
BA_ "GenSigTimeoutTime_ALL" SG_ 1058 MHU_STAT_Language 5000;
BA_ "InvalidValue" SG_ 1058 MHU_STAT_Language "1Fh";
BA_ "GenSigStartValue" SG_ 1058 MHU_STAT_EnergyConsumptionUnit 7;
BA_ "GenSigTimeoutTime_ALL" SG_ 1058 MHU_STAT_EnergyConsumptionUnit 5000;
BA_ "InvalidValue" SG_ 1058 MHU_STAT_EnergyConsumptionUnit "Fh";
BA_ "GenSigTimeoutTime_ALL" SG_ 1058 BAS_version 5000;
BA_ "InvalidValue" SG_ 1058 BAS_version "";
BA_ "GenSigStartValue" SG_ 1058 MHU_STAT_SaleCountry 1023;
BA_ "GenSigTimeoutTime_ALL" SG_ 1058 MHU_STAT_SaleCountry 5000;
BA_ "InvalidValue" SG_ 1058 MHU_STAT_SaleCountry "3FFh";
BA_ "GenSigTimeoutTime_ALL" SG_ 1058 MHU_STAT_BatLvlPopsetting 5000;
BA_ "InvalidValue" SG_ 1058 MHU_STAT_BatLvlPopsetting "3h";
BA_ "GenSigTimeoutTime_ALL" SG_ 1058 MHU_STAT_DistToEmptyUnit 5000;
BA_ "InvalidValue" SG_ 1058 MHU_STAT_DistToEmptyUnit "3h";
BA_ "GenSigTimeoutTime_ALL" SG_ 1059 AVAS_BatteryUnderVoltage 5000;
BA_ "InvalidValue" SG_ 1059 AVAS_BatteryUnderVoltage "null";
BA_ "GenSigTimeoutTime_ALL" SG_ 1059 AVAS_BatteryOverVoltage 5000;
BA_ "InvalidValue" SG_ 1059 AVAS_BatteryOverVoltage "null";
BA_ "GenSigTimeoutTime_ALL" SG_ 1059 AVAS_VINInfoNotPrgm 5000;
BA_ "InvalidValue" SG_ 1059 AVAS_VINInfoNotPrgm "null";
BA_ "GenSigTimeoutTime_ALL" SG_ 1059 AVAS_AMPVoltSplDrvOperationFail 5000;
BA_ "InvalidValue" SG_ 1059 AVAS_AMPVoltSplDrvOperationFail "null";
BA_ "GenSigTimeoutTime_ALL" SG_ 1059 AVAS_AMPIntFaultOverCurr 5000;
BA_ "InvalidValue" SG_ 1059 AVAS_AMPIntFaultOverCurr "null";
BA_ "GenSigTimeoutTime_ALL" SG_ 1059 AVAS_AMPInternalFaultDCError 5000;
BA_ "InvalidValue" SG_ 1059 AVAS_AMPInternalFaultDCError "null";
BA_ "GenSigTimeoutTime_ALL" SG_ 1059 AVAS_AMPInternalFaultOverTemp 5000;
BA_ "InvalidValue" SG_ 1059 AVAS_AMPInternalFaultOverTemp "null";
BA_ "GenSigTimeoutTime_ALL" SG_ 1059 AVAS_AMPInternalFaultClockError 5000;
BA_ "InvalidValue" SG_ 1059 AVAS_AMPInternalFaultClockError "null";
BA_ "GenSigTimeoutTime_ALL" SG_ 1059 AVAS_SpkrMntPwrSwDrvHighFlt 5000;
BA_ "InvalidValue" SG_ 1059 AVAS_SpkrMntPwrSwDrvHighFlt "null";
BA_ "GenSigTimeoutTime_ALL" SG_ 1059 AVAS_SpkrMntPwrSwDrvLowFlt 5000;
BA_ "InvalidValue" SG_ 1059 AVAS_SpkrMntPwrSwDrvLowFlt "null";
BA_ "GenSigTimeoutTime_ALL" SG_ 1059 AVAS_InternalSpeakerOpen 5000;
BA_ "InvalidValue" SG_ 1059 AVAS_InternalSpeakerOpen "null";
BA_ "GenSigTimeoutTime_ALL" SG_ 1059 AVAS_ECUMalFlshOperationErr 5000;
BA_ "InvalidValue" SG_ 1059 AVAS_ECUMalFlshOperationErr "null";
BA_ "GenSigTimeoutTime_ALL" SG_ 1059 AVAS_ECUMalfunctionRamFailure 5000;
BA_ "InvalidValue" SG_ 1059 AVAS_ECUMalfunctionRamFailure "null";
BA_ "GenSigTimeoutTime_ALL" SG_ 1059 AVAS_ECUMalEEPROMFailure 5000;
BA_ "InvalidValue" SG_ 1059 AVAS_ECUMalEEPROMFailure "null";
BA_ "GenSigTimeoutTime_ALL" SG_ 1059 AVAS_CANBusOff 5000;
BA_ "InvalidValue" SG_ 1059 AVAS_CANBusOff "null";
BA_ "GenSigTimeoutTime_ALL" SG_ 1059 AVAS_LossCommVehicleSpeed 5000;
BA_ "InvalidValue" SG_ 1059 AVAS_LossCommVehicleSpeed "null";
BA_ "GenSigTimeoutTime_ALL" SG_ 1059 AVAS_LossCommGearPosition 5000;
BA_ "InvalidValue" SG_ 1059 AVAS_LossCommGearPosition "null";
BA_ "GenSigTimeoutTime_ALL" SG_ 1059 AVAS_LossCommAVASCloseCmd 5000;
BA_ "InvalidValue" SG_ 1059 AVAS_LossCommAVASCloseCmd "null";
BA_ "GenSigTimeoutTime_ALL" SG_ 1068 CHSKM_PSM_D_SEAT_CONTROL 1000;
BA_ "InvalidValue" SG_ 1068 CHSKM_PSM_D_SEAT_CONTROL "null";
BA_ "GenSigTimeoutTime_ALL" SG_ 1068 ALV_PSM_D_SEAT_CONTROL 1000;
BA_ "InvalidValue" SG_ 1068 ALV_PSM_D_SEAT_CONTROL "Fh";
BA_ "GenSigTimeoutTime_ALL" SG_ 1068 PSM_D_DrvSeat_Control_Status 1000;
BA_ "InvalidValue" SG_ 1068 PSM_D_DrvSeat_Control_Status "7h";
BA_ "GenSigTimeoutTime_ALL" SG_ 1068 PSM_D_DrvReclinerPos 1000;
BA_ "InvalidValue" SG_ 1068 PSM_D_DrvReclinerPos "7Fh";
BA_ "GenSigTimeoutTime_ALL" SG_ 1068 PSM_D_DrvTiltPos 1000;
BA_ "InvalidValue" SG_ 1068 PSM_D_DrvTiltPos "1Fh";
BA_ "GenSigTimeoutTime_ALL" SG_ 1068 PSM_D_DrvTrackPos 1000;
BA_ "InvalidValue" SG_ 1068 PSM_D_DrvTrackPos "FFh";
BA_ "GenSigTimeoutTime_ALL" SG_ 1068 PSM_D_DrvHeightPos 1000;
BA_ "InvalidValue" SG_ 1068 PSM_D_DrvHeightPos "3Fh";
BA_ "GenSigSendType" SG_ 1069 XGW_WasherFluid_LevelSwitch 3;
BA_ "InvalidValue" SG_ 1069 XGW_WasherFluid_LevelSwitch "3h";
BA_ "GenSigTimeoutTime_ALL" SG_ 1070 CHKSM_XGW_HCMInfo 500;
BA_ "GenSigTimeoutTime_ALL" SG_ 1070 ALV_XGW_HCMInfo 500;
BA_ "InvalidValue" SG_ 1070 ALV_XGW_HCMInfo "Fh";
BA_ "GenSigStartValue" SG_ 1070 XGW_HLVerLvlMode 1;
BA_ "GenSigTimeoutTime_ALL" SG_ 1070 XGW_HLVerLvlMode 500;
BA_ "InvalidValue" SG_ 1070 XGW_HLVerLvlMode "3h";
BA_ "GenSigTimeoutTime_ALL" SG_ 1070 XGW_AutoHeadlamp_LvlSts 500;
BA_ "InvalidValue" SG_ 1070 XGW_AutoHeadlamp_LvlSts "3h";
BA_ "GenSigTimeoutTime_ALL" SG_ 1073 HUD_ECU_Check 500;
BA_ "GenSigTimeoutTime_ALL" SG_ 1073 HUD_ECU_Fault 500;
BA_ "GenSigTimeoutTime_ALL" SG_ 1074 MHU_FOTA_Checksum 2500;
BA_ "InvalidValue" SG_ 1074 MHU_FOTA_Checksum "null";
BA_ "GenSigTimeoutTime_ALL" SG_ 1074 MHU_FOTA_Alive_Counter 2500;
BA_ "InvalidValue" SG_ 1074 MHU_FOTA_Alive_Counter "Fh";
BA_ "GenSigTimeoutTime_ALL" SG_ 1074 MHU_FOTA_State 2500;
BA_ "InvalidValue" SG_ 1074 MHU_FOTA_State "7h";
BA_ "GenSigTimeoutTime_ALL" SG_ 1074 MHU_FOTA_Error_Code 2500;
BA_ "InvalidValue" SG_ 1074 MHU_FOTA_Error_Code "null";
BA_ "GenSigTimeoutTime_ALL" SG_ 1075 MHU_Headlamp_Chksm 2500;
BA_ "InvalidValue" SG_ 1075 MHU_Headlamp_Chksm "Fh";
BA_ "GenSigTimeoutTime_ALL" SG_ 1075 MHU_Headlamp_Aliv 2500;
BA_ "InvalidValue" SG_ 1075 MHU_Headlamp_Aliv "Fh";
BA_ "GenSigStartValue" SG_ 1075 MHU_HLVerLvlMode 1;
BA_ "GenSigTimeoutTime_ALL" SG_ 1075 MHU_HLVerLvlMode 2500;
BA_ "GenSigTimeoutTime_ALL" SG_ 1076 CHKSM_DMS_STATUS 2500;
BA_ "GenSigTimeoutTime_ALL" SG_ 1076 ALV_DMS_STATUS 2500;
BA_ "InvalidValue" SG_ 1076 ALV_DMS_STATUS "Fh";
BA_ "GenSigTimeoutTime_ALL" SG_ 1076 ADAS_DMS_DRIVER_IDENTIFICATION 2500;
BA_ "InvalidValue" SG_ 1076 ADAS_DMS_DRIVER_IDENTIFICATION "3h";
BA_ "GenSigTimeoutTime_ALL" SG_ 1076 ADAS_DMS_DROWS_DISTRACTION_LVL 2500;
BA_ "InvalidValue" SG_ 1076 ADAS_DMS_DROWS_DISTRACTION_LVL "7h";
BA_ "GenSigTimeoutTime_ALL" SG_ 1076 ADAS_DMS_DRIVER_DETECTION 2500;
BA_ "InvalidValue" SG_ 1076 ADAS_DMS_DRIVER_DETECTION "3h";
BA_ "GenSigTimeoutTime_ALL" SG_ 1076 ADAS_DMS_DRIVER_Status_BAR 2500;
BA_ "InvalidValue" SG_ 1076 ADAS_DMS_DRIVER_Status_BAR "7h";
BA_ "GenSigSendType" SG_ 1077 BCM_SCM_BC_Button 4;
BA_ "InvalidValue" SG_ 1077 BCM_SCM_BC_Button "3h";
BA_ "GenSigSendType" SG_ 1078 MHU_TELStatus 2;
BA_ "GenSigStartValue" SG_ 1078 MHU_TELStatus 7;
BA_ "InvalidValue" SG_ 1078 MHU_TELStatus "7h";
BA_ "GenSigSendType" SG_ 1078 MHU_MUTEStatus 2;
BA_ "InvalidValue" SG_ 1078 MHU_MUTEStatus "3h";
BA_ "GenSigSendType" SG_ 1078 MHU_TEL_source 2;
BA_ "InvalidValue" SG_ 1078 MHU_TEL_source "7h";
BA_ "GenSigTimeoutTime_ALL" SG_ 1079 CRC_VCU_MHU_info_2 1000;
BA_ "GenSigTimeoutTime_ALL" SG_ 1079 CRC_VCU_MHU_info_2 1000;
BA_ "GenSigTimeoutTime_ALL" SG_ 1079 ALIV_VCU_MHU_info_2 1000;
BA_ "GenSigTimeoutTime_ALL" SG_ 1079 ALIV_VCU_MHU_info_2 1000;
BA_ "InvalidValue" SG_ 1079 ALIV_VCU_MHU_info_2 "Fh";
BA_ "GenSigTimeoutTime_ALL" SG_ 1079 VCU_Instant_ConsumEnergy 1000;
BA_ "InvalidValue" SG_ 1079 VCU_Instant_ConsumEnergy "3FFh";
BA_ "GenSigTimeoutTime_ALL" SG_ 1079 VCU_Average_ConsumEnergy 1000;
BA_ "InvalidValue" SG_ 1079 VCU_Average_ConsumEnergy "3FFh";
BA_ "GenSigTimeoutTime_ALL" SG_ 1080 CHKSM_EDS_Error_FR_A 500;
BA_ "InvalidValue" SG_ 1080 CHKSM_EDS_Error_FR_A "";
BA_ "GenSigTimeoutTime_ALL" SG_ 1080 ALV_EDS_Error_FR_A 500;
BA_ "InvalidValue" SG_ 1080 ALV_EDS_Error_FR_A "Fh";
BA_ "GenSigTimeoutTime_ALL" SG_ 1080 EDS_FailNum_ERR_FWD 500;
BA_ "InvalidValue" SG_ 1080 EDS_FailNum_ERR_FWD "";
BA_ "GenSigTimeoutTime_ALL" SG_ 1080 EDS_FailGrade_ERR_FWD 500;
BA_ "InvalidValue" SG_ 1080 EDS_FailGrade_ERR_FWD "7h";
BA_ "GenSigTimeoutTime_ALL" SG_ 1080 EDS_MotOverTempAlarm_FWD 500;
BA_ "InvalidValue" SG_ 1080 EDS_MotOverTempAlarm_FWD "";
BA_ "GenSigTimeoutTime_ALL" SG_ 1080 EDS_MotOverTempFault_FWD 500;
BA_ "InvalidValue" SG_ 1080 EDS_MotOverTempFault_FWD "";
BA_ "GenSigTimeoutTime_ALL" SG_ 1080 EDS_MotTempSenFault_FWD 500;
BA_ "InvalidValue" SG_ 1080 EDS_MotTempSenFault_FWD "";
BA_ "GenSigTimeoutTime_ALL" SG_ 1080 EDS_EDSOverTempUFault_FWD 500;
BA_ "InvalidValue" SG_ 1080 EDS_EDSOverTempUFault_FWD "";
BA_ "GenSigTimeoutTime_ALL" SG_ 1080 EDS_EDSOverTempVFault_FWD 500;
BA_ "InvalidValue" SG_ 1080 EDS_EDSOverTempVFault_FWD "";
BA_ "GenSigTimeoutTime_ALL" SG_ 1080 EDS_EDSOverTempWFault_FWD 500;
BA_ "InvalidValue" SG_ 1080 EDS_EDSOverTempWFault_FWD "";
BA_ "GenSigTimeoutTime_ALL" SG_ 1080 EDS_EDSOverTempAlarm_FWD 500;
BA_ "InvalidValue" SG_ 1080 EDS_EDSOverTempAlarm_FWD "";
BA_ "GenSigTimeoutTime_ALL" SG_ 1080 EDS_TCoolantOvHi_FWD 500;
BA_ "InvalidValue" SG_ 1080 EDS_TCoolantOvHi_FWD "";
BA_ "GenSigTimeoutTime_ALL" SG_ 1080 EDS_EDSTempCmpAlarm_FWD 500;
BA_ "InvalidValue" SG_ 1080 EDS_EDSTempCmpAlarm_FWD "";
BA_ "GenSigTimeoutTime_ALL" SG_ 1080 EDS_EDSPhaOvCurentHWFault_FWD 500;
BA_ "InvalidValue" SG_ 1080 EDS_EDSPhaOvCurentHWFault_FWD "";
BA_ "GenSigTimeoutTime_ALL" SG_ 1080 EDS_EDSphaOffCalFault_FWD 500;
BA_ "InvalidValue" SG_ 1080 EDS_EDSphaOffCalFault_FWD "";
BA_ "GenSigTimeoutTime_ALL" SG_ 1080 EDS_EDSOverIdcLnkAlarm_FWD 500;
BA_ "InvalidValue" SG_ 1080 EDS_EDSOverIdcLnkAlarm_FWD "";
BA_ "GenSigTimeoutTime_ALL" SG_ 1080 EDS_EDSHVOverVoltageAlarm_FWD 500;
BA_ "InvalidValue" SG_ 1080 EDS_EDSHVOverVoltageAlarm_FWD "";
BA_ "GenSigTimeoutTime_ALL" SG_ 1080 EDS_EDSHVOverVoltageFault_FWD 500;
BA_ "InvalidValue" SG_ 1080 EDS_EDSHVOverVoltageFault_FWD "";
BA_ "GenSigTimeoutTime_ALL" SG_ 1080 EDS_EDSHVUnderVoltageAlarm_FWD 500;
BA_ "InvalidValue" SG_ 1080 EDS_EDSHVUnderVoltageAlarm_FWD "";
BA_ "GenSigTimeoutTime_ALL" SG_ 1080 EDS_EDSHVUnderVoltageFault_FWD 500;
BA_ "InvalidValue" SG_ 1080 EDS_EDSHVUnderVoltageFault_FWD "";
BA_ "GenSigTimeoutTime_ALL" SG_ 1080 EDS_RunToDischaErr_FWD 500;
BA_ "InvalidValue" SG_ 1080 EDS_RunToDischaErr_FWD "";
BA_ "GenSigTimeoutTime_ALL" SG_ 1080 EDS_12VOverVoltageAlarm_FWD 500;
BA_ "InvalidValue" SG_ 1080 EDS_12VOverVoltageAlarm_FWD "";
BA_ "GenSigTimeoutTime_ALL" SG_ 1080 EDS_12VUnderVoltageAlarm_FWD 500;
BA_ "InvalidValue" SG_ 1080 EDS_12VUnderVoltageAlarm_FWD "";
BA_ "GenSigTimeoutTime_ALL" SG_ 1080 EDS_MotOverAlarm_FWD 500;
BA_ "InvalidValue" SG_ 1080 EDS_MotOverAlarm_FWD "";
BA_ "GenSigTimeoutTime_ALL" SG_ 1080 EDS_MotOverFault_FWD 500;
BA_ "InvalidValue" SG_ 1080 EDS_MotOverFault_FWD "";
BA_ "GenSigTimeoutTime_ALL" SG_ 1080 EDS_ResolverOffsetAngle_FWD 500;
BA_ "GenSigTimeoutTime_ALL" SG_ 1080 SECCAN_EDS_Error_FR_A 500;
BA_ "InvalidValue" SG_ 1080 SECCAN_EDS_Error_FR_A "";
BA_ "GenSigTimeoutTime_ALL" SG_ 1081 CHKSM_EDS_Error_RR_A 500;
BA_ "InvalidValue" SG_ 1081 CHKSM_EDS_Error_RR_A "";
BA_ "GenSigTimeoutTime_ALL" SG_ 1081 ALV_EDS_Error_RR_A 500;
BA_ "InvalidValue" SG_ 1081 ALV_EDS_Error_RR_A "Fh";
BA_ "GenSigTimeoutTime_ALL" SG_ 1081 EDS_FailNum_ERR_RWD 500;
BA_ "InvalidValue" SG_ 1081 EDS_FailNum_ERR_RWD "";
BA_ "GenSigTimeoutTime_ALL" SG_ 1081 EDS_FailGrade_ERR_RWD 500;
BA_ "InvalidValue" SG_ 1081 EDS_FailGrade_ERR_RWD "7h";
BA_ "GenSigTimeoutTime_ALL" SG_ 1081 EDS_MotOverTempAlarm_RWD 500;
BA_ "InvalidValue" SG_ 1081 EDS_MotOverTempAlarm_RWD "";
BA_ "GenSigTimeoutTime_ALL" SG_ 1081 EDS_MotOverTempFault_RWD 500;
BA_ "InvalidValue" SG_ 1081 EDS_MotOverTempFault_RWD "";
BA_ "GenSigTimeoutTime_ALL" SG_ 1081 EDS_MotTempSenFault_RWD 500;
BA_ "InvalidValue" SG_ 1081 EDS_MotTempSenFault_RWD "";
BA_ "GenSigTimeoutTime_ALL" SG_ 1081 EDS_EDSOverTempUFault_RWD 500;
BA_ "InvalidValue" SG_ 1081 EDS_EDSOverTempUFault_RWD "";
BA_ "GenSigTimeoutTime_ALL" SG_ 1081 EDS_EDSOverTempVFault_RWD 500;
BA_ "InvalidValue" SG_ 1081 EDS_EDSOverTempVFault_RWD "";
BA_ "GenSigTimeoutTime_ALL" SG_ 1081 EDS_EDSOverTempWFault_RWD 500;
BA_ "InvalidValue" SG_ 1081 EDS_EDSOverTempWFault_RWD "";
BA_ "GenSigTimeoutTime_ALL" SG_ 1081 EDS_EDSOverTempAlarm_RWD 500;
BA_ "InvalidValue" SG_ 1081 EDS_EDSOverTempAlarm_RWD "";
BA_ "GenSigTimeoutTime_ALL" SG_ 1081 EDS_TCoolantOvHi_RWD 500;
BA_ "InvalidValue" SG_ 1081 EDS_TCoolantOvHi_RWD "";
BA_ "GenSigTimeoutTime_ALL" SG_ 1081 EDS_EDSTempCmpAlarm_RWD 500;
BA_ "InvalidValue" SG_ 1081 EDS_EDSTempCmpAlarm_RWD "";
BA_ "GenSigTimeoutTime_ALL" SG_ 1081 EDS_EDSPhaOvCurentHWFault_RWD 500;
BA_ "InvalidValue" SG_ 1081 EDS_EDSPhaOvCurentHWFault_RWD "";
BA_ "GenSigTimeoutTime_ALL" SG_ 1081 EDS_EDSphaOffCalFault_RWD 500;
BA_ "InvalidValue" SG_ 1081 EDS_EDSphaOffCalFault_RWD "";
BA_ "GenSigTimeoutTime_ALL" SG_ 1081 EDS_EDSOverIdcLnkAlarm_RWD 500;
BA_ "InvalidValue" SG_ 1081 EDS_EDSOverIdcLnkAlarm_RWD "";
BA_ "GenSigTimeoutTime_ALL" SG_ 1081 EDS_EDSHVOverVoltageAlarm_RWD 500;
BA_ "InvalidValue" SG_ 1081 EDS_EDSHVOverVoltageAlarm_RWD "";
BA_ "GenSigTimeoutTime_ALL" SG_ 1081 EDS_EDSHVOverVoltageFault_RWD 500;
BA_ "InvalidValue" SG_ 1081 EDS_EDSHVOverVoltageFault_RWD "";
BA_ "GenSigTimeoutTime_ALL" SG_ 1081 EDS_EDSHVUnderVoltageAlarm_RWD 500;
BA_ "InvalidValue" SG_ 1081 EDS_EDSHVUnderVoltageAlarm_RWD "";
BA_ "GenSigTimeoutTime_ALL" SG_ 1081 EDS_EDSHVUnderVoltageFault_RWD 500;
BA_ "InvalidValue" SG_ 1081 EDS_EDSHVUnderVoltageFault_RWD "";
BA_ "GenSigTimeoutTime_ALL" SG_ 1081 EDS_RunToDischaErr_RWD 500;
BA_ "InvalidValue" SG_ 1081 EDS_RunToDischaErr_RWD "";
BA_ "GenSigTimeoutTime_ALL" SG_ 1081 EDS_12VOverVoltageAlarm_RWD 500;
BA_ "InvalidValue" SG_ 1081 EDS_12VOverVoltageAlarm_RWD "";
BA_ "GenSigTimeoutTime_ALL" SG_ 1081 EDS_12VUnderVoltageAlarm_RWD 500;
BA_ "InvalidValue" SG_ 1081 EDS_12VUnderVoltageAlarm_RWD "";
BA_ "GenSigTimeoutTime_ALL" SG_ 1081 EDS_MotOverAlarm_RWD 500;
BA_ "InvalidValue" SG_ 1081 EDS_MotOverAlarm_RWD "";
BA_ "GenSigTimeoutTime_ALL" SG_ 1081 EDS_MotOverFault_RWD 500;
BA_ "InvalidValue" SG_ 1081 EDS_MotOverFault_RWD "";
BA_ "GenSigTimeoutTime_ALL" SG_ 1081 EDS_ResolverOffsetAngle_RWD 500;
BA_ "GenSigTimeoutTime_ALL" SG_ 1081 SECCAN_EDS_Error_RR_A 500;
BA_ "InvalidValue" SG_ 1081 SECCAN_EDS_Error_RR_A "";
BA_ "GenSigTimeoutTime_ALL" SG_ 1082 CRC_VCU_MHU_info 500;
BA_ "InvalidValue" SG_ 1082 CRC_VCU_MHU_info "null";
BA_ "GenSigTimeoutTime_ALL" SG_ 1082 ALIV_VCU_MHU_info 500;
BA_ "InvalidValue" SG_ 1082 ALIV_VCU_MHU_info "Fh";
BA_ "GenSigTimeoutTime_ALL" SG_ 1082 VCU_BrakeRegenMode 500;
BA_ "InvalidValue" SG_ 1082 VCU_BrakeRegenMode "";
BA_ "GenSigTimeoutTime_ALL" SG_ 1082 VCU_CreepDisable_stt 500;
BA_ "InvalidValue" SG_ 1082 VCU_CreepDisable_stt "null";
BA_ "GenSigStartValue" SG_ 1082 VCU_PowerRegenGaugeDisplay 100;
BA_ "GenSigTimeoutTime_ALL" SG_ 1082 VCU_PowerRegenGaugeDisplay 500;
BA_ "InvalidValue" SG_ 1082 VCU_PowerRegenGaugeDisplay "FFh";
BA_ "GenSigTimeoutTime_ALL" SG_ 1082 VCU_Charging_Authen_stt 500;
BA_ "InvalidValue" SG_ 1082 VCU_Charging_Authen_stt "null";
BA_ "GenSigTimeoutTime_ALL" SG_ 1082 VCU_ChgGun_BadConn_stt 500;
BA_ "InvalidValue" SG_ 1082 VCU_ChgGun_BadConn_stt "null";
BA_ "GenSigTimeoutTime_ALL" SG_ 1082 VCU_ChgPort_Open_stt 500;
BA_ "InvalidValue" SG_ 1082 VCU_ChgPort_Open_stt "null";
BA_ "GenSigStartValue" SG_ 1082 VCU_Regen_available 1;
BA_ "GenSigTimeoutTime_ALL" SG_ 1082 VCU_Regen_available 500;
BA_ "InvalidValue" SG_ 1082 VCU_Regen_available "null";
BA_ "GenSigTimeoutTime_ALL" SG_ 1082 VCU_VehChg_STS 500;
BA_ "InvalidValue" SG_ 1082 VCU_VehChg_STS "null";
BA_ "GenSigTimeoutTime_ALL" SG_ 1082 VCU_StoppingMode_stt 500;
BA_ "GenSigTimeoutTime_ALL" SG_ 1082 VCU_AutoP_Feedback 500;
BA_ "InvalidValue" SG_ 1082 VCU_AutoP_Feedback "3h";
BA_ "GenSigTimeoutTime_ALL" SG_ 1082 VCU_SOC_display 500;
BA_ "InvalidValue" SG_ 1082 VCU_SOC_display "null";
BA_ "GenSigStartValue" SG_ 1082 VCU_ChgGun_Status 7;
BA_ "GenSigTimeoutTime_ALL" SG_ 1082 VCU_ChgGun_Status 500;
BA_ "InvalidValue" SG_ 1082 VCU_ChgGun_Status "7h";
BA_ "GenSigTimeoutTime_ALL" SG_ 1082 VCU_ChgPort_Lock_stt 500;
BA_ "InvalidValue" SG_ 1082 VCU_ChgPort_Lock_stt "null";
BA_ "GenSigTimeoutTime_ALL" SG_ 1082 VCU_Hvbatt_charging_stt 500;
BA_ "InvalidValue" SG_ 1082 VCU_Hvbatt_charging_stt "null";
BA_ "GenSigSendType" SG_ 1083 MHU_SET_TiltPos 2;
BA_ "InvalidValue" SG_ 1083 MHU_SET_TiltPos "FFh";
BA_ "GenSigSendType" SG_ 1083 MHU_SET_TelePos 2;
BA_ "InvalidValue" SG_ 1083 MHU_SET_TelePos "FFh";
BA_ "GenSigSendType" SG_ 1083 MHU_SET_SteeringAdjust 2;
BA_ "InvalidValue" SG_ 1083 MHU_SET_SteeringAdjust "null";
BA_ "GenSigSendType" SG_ 1084 EASC_TiltPos 3;
BA_ "InvalidValue" SG_ 1084 EASC_TiltPos "FFh";
BA_ "GenSigSendType" SG_ 1084 EASC_TelePos 3;
BA_ "InvalidValue" SG_ 1084 EASC_TelePos "FFh";
BA_ "GenSigSendType" SG_ 1084 EASC_SteeringAdjust 4;
BA_ "InvalidValue" SG_ 1084 EASC_SteeringAdjust "null";
BA_ "GenSigStartValue" SG_ 1086 MHU_SET_Mediavolume 15;
BA_ "GenSigTimeoutTime_ALL" SG_ 1086 MHU_SET_Mediavolume 500;
BA_ "InvalidValue" SG_ 1086 MHU_SET_Mediavolume "FFh";
BA_ "GenSigTimeoutTime_ALL" SG_ 1086 MHU_SET_Soundzone 500;
BA_ "InvalidValue" SG_ 1086 MHU_SET_Soundzone "0";
BA_ "GenSigStartValue" SG_ 1086 MHU_SET_Bass 6;
BA_ "GenSigTimeoutTime_ALL" SG_ 1086 MHU_SET_Bass 500;
BA_ "InvalidValue" SG_ 1086 MHU_SET_Bass "1Fh";
BA_ "GenSigStartValue" SG_ 1086 MHU_SET_Fader 10;
BA_ "GenSigTimeoutTime_ALL" SG_ 1086 MHU_SET_Fader 500;
BA_ "InvalidValue" SG_ 1086 MHU_SET_Fader "1Fh";
BA_ "GenSigStartValue" SG_ 1086 MHU_SET_MediaMute 1;
BA_ "GenSigTimeoutTime_ALL" SG_ 1086 MHU_SET_MediaMute 500;
BA_ "InvalidValue" SG_ 1086 MHU_SET_MediaMute "3h";
BA_ "GenSigStartValue" SG_ 1086 MHU_SET_MidPitch 6;
BA_ "GenSigTimeoutTime_ALL" SG_ 1086 MHU_SET_MidPitch 500;
BA_ "InvalidValue" SG_ 1086 MHU_SET_MidPitch "1Fh";
BA_ "GenSigStartValue" SG_ 1086 MHU_SET_Treble 6;
BA_ "GenSigTimeoutTime_ALL" SG_ 1086 MHU_SET_Treble 500;
BA_ "InvalidValue" SG_ 1086 MHU_SET_Treble "1Fh";
BA_ "GenSigStartValue" SG_ 1086 MHU_SET_Balance 10;
BA_ "GenSigTimeoutTime_ALL" SG_ 1086 MHU_SET_Balance 500;
BA_ "InvalidValue" SG_ 1086 MHU_SET_Balance "1Fh";
BA_ "GenSigStartValue" SG_ 1087 MHU_SET_EQ_1000HZ 6;
BA_ "GenSigTimeoutTime_ALL" SG_ 1087 MHU_SET_EQ_1000HZ 500;
BA_ "InvalidValue" SG_ 1087 MHU_SET_EQ_1000HZ "1Fh";
BA_ "GenSigTimeoutTime_ALL" SG_ 1087 MHU_SET_EQ_16000HZ 500;
BA_ "InvalidValue" SG_ 1087 MHU_SET_EQ_16000HZ "1Fh";
BA_ "GenSigStartValue" SG_ 1087 MHU_SET_EQ_250HZ 6;
BA_ "GenSigTimeoutTime_ALL" SG_ 1087 MHU_SET_EQ_250HZ 500;
BA_ "InvalidValue" SG_ 1087 MHU_SET_EQ_250HZ "1Fh";
BA_ "GenSigTimeoutTime_ALL" SG_ 1087 MHU_SET_EQ_4000HZ 500;
BA_ "InvalidValue" SG_ 1087 MHU_SET_EQ_4000HZ "1Fh";
BA_ "GenSigStartValue" SG_ 1087 MHU_SET_EQ_60HZ 6;
BA_ "GenSigTimeoutTime_ALL" SG_ 1087 MHU_SET_EQ_60HZ 500;
BA_ "InvalidValue" SG_ 1087 MHU_SET_EQ_60HZ "1Fh";
BA_ "GenSigTimeoutTime_ALL" SG_ 1087 MHU_SET_EQType 500;
BA_ "InvalidValue" SG_ 1087 MHU_SET_EQType "Fh";
BA_ "GenSigStartValue" SG_ 1088 AMP_SET_EQ_1000HZ 6;
BA_ "GenSigTimeoutTime_ALL" SG_ 1088 AMP_SET_EQ_1000HZ 500;
BA_ "InvalidValue" SG_ 1088 AMP_SET_EQ_1000HZ "1Fh";
BA_ "GenSigTimeoutTime_ALL" SG_ 1088 AMP_SET_EQ_16000HZ 500;
BA_ "InvalidValue" SG_ 1088 AMP_SET_EQ_16000HZ "1Fh";
BA_ "GenSigStartValue" SG_ 1088 AMP_SET_EQ_250HZ 6;
BA_ "GenSigTimeoutTime_ALL" SG_ 1088 AMP_SET_EQ_250HZ 500;
BA_ "InvalidValue" SG_ 1088 AMP_SET_EQ_250HZ "1Fh";
BA_ "GenSigTimeoutTime_ALL" SG_ 1088 AMP_SET_EQ_4000HZ 500;
BA_ "InvalidValue" SG_ 1088 AMP_SET_EQ_4000HZ "1Fh";
BA_ "GenSigStartValue" SG_ 1088 AMP_SET_EQ_60HZ 6;
BA_ "GenSigTimeoutTime_ALL" SG_ 1088 AMP_SET_EQ_60HZ 500;
BA_ "InvalidValue" SG_ 1088 AMP_SET_EQ_60HZ "1Fh";
BA_ "GenSigTimeoutTime_ALL" SG_ 1088 AMP_SET_EQType 500;
BA_ "InvalidValue" SG_ 1088 AMP_SET_EQType "Fh";
BA_ "GenSigTimeoutTime_ALL" SG_ 1090 WLC_IC_Error 2500;
BA_ "InvalidValue" SG_ 1090 WLC_IC_Error "null";
BA_ "GenSigTimeoutTime_ALL" SG_ 1090 WLC_FAN_Error 2500;
BA_ "InvalidValue" SG_ 1090 WLC_FAN_Error "null";
BA_ "GenSigTimeoutTime_ALL" SG_ 1090 WLC_TempSNSR_Error 2500;
BA_ "InvalidValue" SG_ 1090 WLC_TempSNSR_Error "null";
BA_ "GenSigStartValue" SG_ 1090 WLC_Setting_standard 2;
BA_ "GenSigTimeoutTime_ALL" SG_ 1090 WLC_Setting_standard 2500;
BA_ "InvalidValue" SG_ 1090 WLC_Setting_standard "null";
BA_ "GenSigTimeoutTime_ALL" SG_ 1090 Transmit_WLC_situation 2500;
BA_ "InvalidValue" SG_ 1090 Transmit_WLC_situation "null";
BA_ "GenSigTimeoutTime_ALL" SG_ 1090 WLC_VehSpeed_Error 2500;
BA_ "InvalidValue" SG_ 1090 WLC_VehSpeed_Error "null";
BA_ "GenSigTimeoutTime_ALL" SG_ 1090 WLC_Resp_Error 2500;
BA_ "InvalidValue" SG_ 1090 WLC_Resp_Error "null";
BA_ "GenSigTimeoutTime_ALL" SG_ 1090 WLC_FOD_Error 2500;
BA_ "InvalidValue" SG_ 1090 WLC_FOD_Error "null";
BA_ "GenSigTimeoutTime_ALL" SG_ 1090 WLC_Curr_Error 2500;
BA_ "InvalidValue" SG_ 1090 WLC_Curr_Error "null";
BA_ "GenSigTimeoutTime_ALL" SG_ 1090 WLC_Temp_Error 2500;
BA_ "InvalidValue" SG_ 1090 WLC_Temp_Error "null";
BA_ "GenSigTimeoutTime_ALL" SG_ 1091 WLC_IC_Error_2 2500;
BA_ "InvalidValue" SG_ 1091 WLC_IC_Error_2 "null";
BA_ "GenSigTimeoutTime_ALL" SG_ 1091 WLC_FAN_Error_2 2500;
BA_ "InvalidValue" SG_ 1091 WLC_FAN_Error_2 "null";
BA_ "GenSigTimeoutTime_ALL" SG_ 1091 WLC_TempSNSR_Error_2 2500;
BA_ "InvalidValue" SG_ 1091 WLC_TempSNSR_Error_2 "null";
BA_ "GenSigStartValue" SG_ 1091 WLC_Setting_standard_2 2;
BA_ "GenSigTimeoutTime_ALL" SG_ 1091 WLC_Setting_standard_2 2500;
BA_ "InvalidValue" SG_ 1091 WLC_Setting_standard_2 "null";
BA_ "GenSigTimeoutTime_ALL" SG_ 1091 Transmit_WLC_situation_2 2500;
BA_ "InvalidValue" SG_ 1091 Transmit_WLC_situation_2 "null";
BA_ "GenSigTimeoutTime_ALL" SG_ 1091 WLC_VehSpeed_Error_2 2500;
BA_ "InvalidValue" SG_ 1091 WLC_VehSpeed_Error_2 "null";
BA_ "GenSigTimeoutTime_ALL" SG_ 1091 WLC_Resp_Error_2 2500;
BA_ "InvalidValue" SG_ 1091 WLC_Resp_Error_2 "null";
BA_ "GenSigTimeoutTime_ALL" SG_ 1091 WLC_FOD_Error_2 2500;
BA_ "InvalidValue" SG_ 1091 WLC_FOD_Error_2 "null";
BA_ "GenSigTimeoutTime_ALL" SG_ 1091 WLC_Curr_Error_2 2500;
BA_ "InvalidValue" SG_ 1091 WLC_Curr_Error_2 "null";
BA_ "GenSigTimeoutTime_ALL" SG_ 1091 WLC_Temp_Error_2 2500;
BA_ "InvalidValue" SG_ 1091 WLC_Temp_Error_2 "null";
BA_ "GenSigTimeoutTime_ALL" SG_ 1092 Checksum_MHU_ADAS_RP_Ctrl 1000;
BA_ "InvalidValue" SG_ 1092 Checksum_MHU_ADAS_RP_Ctrl "null";
BA_ "GenSigTimeoutTime_ALL" SG_ 1092 Rolling_Counter_MHU_ADAS_RP_Ctrl 1000;
BA_ "InvalidValue" SG_ 1092 Rolling_Counter_MHU_ADAS_RP_Ctrl "Fh";
BA_ "GenSigTimeoutTime_ALL" SG_ 1092 MHU_RPParkingstartReq 1000;
BA_ "GenSigTimeoutTime_ALL" SG_ 1092 MHU_RP_ParkOutModeConfirm 1000;
BA_ "InvalidValue" SG_ 1092 MHU_RP_ParkOutModeConfirm "3h";
BA_ "GenSigTimeoutTime_ALL" SG_ 1092 MHU_RP_ParkOutDircnConfirm 1000;
BA_ "InvalidValue" SG_ 1092 MHU_RP_ParkOutDircnConfirm "3h";
BA_ "GenSigTimeoutTime_ALL" SG_ 1092 MHU_RemoteconnectionSts 1000;
BA_ "InvalidValue" SG_ 1092 MHU_RemoteconnectionSts "3h";
BA_ "GenSigTimeoutTime_ALL" SG_ 1092 MHU_RP_FuncMode 1000;
BA_ "InvalidValue" SG_ 1092 MHU_RP_FuncMode "null";
BA_ "GenSigTimeoutTime_ALL" SG_ 1092 MHU_SMParkingstartReq 1000;
BA_ "InvalidValue" SG_ 1092 MHU_SMParkingstartReq "null";
BA_ "GenSigTimeoutTime_ALL" SG_ 1092 MHU_SMParkingControlReq 1000;
BA_ "InvalidValue" SG_ 1092 MHU_SMParkingControlReq "null";
BA_ "GenSigTimeoutTime_ALL" SG_ 1092 MHU_RP_RecoverParking 1000;
BA_ "GenSigTimeoutTime_ALL" SG_ 1092 MHU_RPStraightParkingDir 1000;
BA_ "InvalidValue" SG_ 1092 MHU_RPStraightParkingDir "3h";
BA_ "GenSigTimeoutTime_ALL" SG_ 1092 MHU_SM_global_path_Status 1000;
BA_ "InvalidValue" SG_ 1092 MHU_SM_global_path_Status "null";
BA_ "GenSigTimeoutTime_ALL" SG_ 1092 MHU_SM_QuitReq 1000;
BA_ "InvalidValue" SG_ 1092 MHU_SM_QuitReq "null";
BA_ "GenSigTimeoutTime_ALL" SG_ 1092 MHU_RPParkingControlReq 1000;
BA_ "GenSigTimeoutTime_ALL" SG_ 1092 MHU_RP_QuitReq 1000;
BA_ "GenSigTimeoutTime_ALL" SG_ 1092 SECCAN_ADAS_RP_Ctrl 1000;
BA_ "GenSigTimeoutTime_ALL" SG_ 1093 RS_Sol_L 500;
BA_ "InvalidValue" SG_ 1093 RS_Sol_L "FFh";
BA_ "GenSigTimeoutTime_ALL" SG_ 1093 RS_Sol_R 500;
BA_ "InvalidValue" SG_ 1093 RS_Sol_R "FFh";
BA_ "GenSigTimeoutTime_ALL" SG_ 1093 RS_F_LightSensor 500;
BA_ "GenSigTimeoutTime_ALL" SG_ 1093 RS_F_HUD_Sensor 500;
BA_ "InvalidValue" SG_ 1093 RS_F_HUD_Sensor "null";
BA_ "GenSigTimeoutTime_ALL" SG_ 1093 RS_St_LampReq 500;
BA_ "InvalidValue" SG_ 1093 RS_St_LampReq "3h";
BA_ "GenSigTimeoutTime_ALL" SG_ 1093 RS_St_CurrentRain 500;
BA_ "InvalidValue" SG_ 1093 RS_St_CurrentRain "7h";
BA_ "GenSigTimeoutTime_ALL" SG_ 1093 RS_HUD_illuminance 500;
BA_ "InvalidValue" SG_ 1093 RS_HUD_illuminance "FFFFh";
BA_ "InvalidValue" SG_ 1093 RS_HUD_illuminance "null";
VAL_ 852 MHU_FCW_Mode 0 "OFF" 1 "ON" 2 "Reserve" 3 "Signal invalid";
VAL_ 852 MHU_FCW_sens 0 "Early" 1 "Normal" 2 "Late" 3 "Signal invalid";
VAL_ 852 MHU_AEB_Mode 0 "OFF" 1 "ON" 2 "Reserved" 3 "Signal invalid";
VAL_ 852 MHU_RAEB_Mode 0 "OFF" 1 "ON" 2 "Reserved" 3 "Signal invalid";
VAL_ 852 MHU_LA_sens 0 "Early" 1 "Normal" 2 "Late" 3 "Signal invalid";
VAL_ 852 MHU_LA_AudWarning 0 "OFF" 1 "ON" 2 "Reserved" 3 "Signal invalid";
VAL_ 852 MHU_BSD_On 0 "OFF" 1 "ON" 2 "Reserved" 3 "Signal invalid";
VAL_ 852 MHU_ALC_ON 0 "OFF" 1 "ON" 2 "Reserved" 3 "Reserved";
VAL_ 852 MHU_BSD_AudWarning 0 "OFF" 1 "ON" 2 "Reserved" 3 "Signal invalid";
VAL_ 852 MHU_RCTA_On 0 "OFF" 1 "ON" 2 "Reserved" 3 "Signal invalid";
VAL_ 852 MHU_RCTA_sens 0 "Early" 1 "Normal" 2 "Late" 3 "Signal invalid";
VAL_ 852 MHU_PA_On 0 "OFF" 1 "ON" 2 "Reserved" 3 "Signal invalid";
VAL_ 852 MHU_AHB_On 0 "OFF" 1 "ON" 2 "Reserved" 3 "Signal invalid";
VAL_ 852 MHU_IA_Mode 0 "OFF" 1 "ON" 2 "Reserved" 3 "Signal invalid";
VAL_ 852 MHU_TSR_Mode 0 "OFF" 1 "ON" 2 "Reserve" 3 "Signal invalid";
VAL_ 852 MHU_DOW_Mode 0 "OFF" 1 "Warning Only" 2 "Warning/Door Lock both" 3 "Signal invalid";
VAL_ 852 MHU_AHB_sens 0 "Early" 1 "Normal" 2 "Late" 3 "Signal invalid";
VAL_ 852 MHU_LA_Mode 0 "OFF" 1 "Warning only" 2 "Warning & Steer" 3 "ELK" 4 "Signal Invalid";
VAL_ 852 MHU_SET_TSR_AudWarn 0 "OFF" 1 "ON" 2 "Reserved" 3 "Signal invalid";
VAL_ 852 MHU_SET_TSR_SLAert 0 "OFF" 1 "Speed Limit" 2 "Speed Limit + 5" 3 "Speed Limit + 10";
VAL_ 853 ADAS_PAUSS_FaultFLO 0 "No fault" 1 "Fault";
VAL_ 853 ADAS_PAUSS_FaultFLI 0 "No fault" 1 "Fault";
VAL_ 853 ADAS_PAUSS_check 0 "Available" 1 "Temporarily not available" 2 "Permanently not available";
VAL_ 853 ADAS_PAUSS_FaultRLO 0 "No fault" 1 "Fault";
VAL_ 853 ADAS_PAUSS_FaultFRI 0 "No fault" 1 "Fault";
VAL_ 853 ADAS_FPA_check 0 "Available" 1 "Temporarily not available" 2 "Permanently not available";
VAL_ 853 ADAS_PAUSS_FaultRLI 0 "No fault" 1 "Fault";
VAL_ 853 ADAS_PAUSS_FaultRRO 0 "No fault" 1 "Fault";
VAL_ 853 ADAS_PAUSS_FaultRRI 0 "No fault" 1 "Fault";
VAL_ 853 ADAS_RPA_check 0 "Available" 1 "Temporarily not available" 2 "Permanently not available";
VAL_ 853 ADAS_PAUSS_FaultFRO 0 "No fault" 1 "Fault";
VAL_ 880 SBR_STAT_Chime 0 "Off" 1 "Durable" 2 "Blinking 3Hz" 3 "SNA";
VAL_ 880 SBR_STAT_Telltale 0 "No chime" 1 "1 Hz" 2 "3 Hz" 3 "SNA";
VAL_ 880 SBR_STAT_Active 0 "Not active" 1 "Active";
VAL_ 885 BMS_PreChgRelay_ERR 0 "error" 1 "normal";
VAL_ 885 BMS_TotalNegRelay_ERR 0 "Error" 1 "normal";
VAL_ 885 BMS_MainPosRelay_ERR 0 "Error" 1 "normal";
VAL_ 885 BMS_MainPosRelay_STS 0 "reserved" 1 "open" 2 "closed" 3 "stuck closed" 4 "stuck open";
VAL_ 885 BMS_PreChgRelay_STS 0 "reserved" 1 "open" 2 "closed" 3 "stuck closed" 4 "stuck open";
VAL_ 885 BMS_TotalNegRelay_STS 0 "reserved" 1 "open" 2 "closed" 3 "stuck closed" 4 "stuck open";
VAL_ 897 ACM_Seat_Occupancy_Passenger 0 "Seat_Not_Occupied" 1 "Seat Occupied" 2 "Not_Available" 3 "Failure";
VAL_ 897 ACM_Seat_Occupancy_2nd_Row_Dri 0 "Seat_Not_Occupied" 1 "Seat Occupied" 2 "Not_Available" 3 "Failure";
VAL_ 897 ACM_Seat_Occupancy_2nd_Row_Pas 0 "Seat_Not_Occupied" 1 "Seat Occupied" 2 "Not_Available" 3 "Failure";
VAL_ 897 ACM_Seat_Occupancy_2nd_Row_Mid 0 "Seat_Not_Occupied" 1 "Seat Occupied" 2 "Not_Available" 3 "Failure";
VAL_ 897 ACM_Seat_Belt_Status_Passenger 0 "Not_buckled" 1 "Buckled" 2 "Not_Available" 3 "Failure";
VAL_ 897 ACM_Seat_Belt_Status_Driver 0 "Not_buckled" 1 "Buckled" 2 "Not_Available" 3 "Failure";
VAL_ 897 ACM_Seat_Belt_Status_2nd_Row_Dri 0 "Not_buckled" 1 "Buckled" 2 "Not_Available" 3 "Failure";
VAL_ 897 ACM_Seat_Belt_Status_2nd_Row_Mid 0 "Not_buckled" 1 "Buckled" 2 "Not_Available" 3 "Failure";
VAL_ 897 ACM_Seat_Belt_Status_2nd_Row_Pas 0 "Not_buckled" 1 "Buckled" 2 "Not_Available" 3 "Failure";
VAL_ 905 VCU_IMMO_Sts 0 "init" 1 "pass" 2 "failed";
VAL_ 915 MHU_SET_HudRotateLvl 0 "Invalid" 1 "Level 1" 2 "Level 2" 3 "Level 3" 4 "Level 4" 5 "Level 5" 6 "Level 6" 7 "Level 7" 8 "Level 8" 9 "Level 9" 10 "Level 10" 11 "Level 11" 12 "Level 12" 13 "Level 13" 14 "Level 14" 15 "Level 15";
VAL_ 915 MHU_SET_HudHeightLvl 0 "Invalid" 1 "Level 1" 2 "Level 2" 3 "Level 3" 4 "Level 4" 5 "Level 5" 6 "Level 6" 7 "Level 7" 8 "Level 8" 9 "Level 9" 10 "Level 10" 11 "Level 11" 12 "Level 12" 13 "Level 13" 14 "Level 14" 15 "Level 15" 16 "Level 16" 17 "Level 17" 18 "Level 18" 19 "Level 19" 20 "Level 20" 21 "Level 21" 22 "Reserved";
VAL_ 925 BCM_AHB_Override 0 "not used" 1 "Automatic High Beam request" 2 "AHB  Inhibit by Driver" 3 "invalid";
VAL_ 943 MHU_IPC_ID 0 "Media OFF" 1 "Telephone Name / Number" 2 "Reserved" 3 "USB - Songname, Album, Artist" 4 "BT - Songname, Album, Artist" 5 "IPOD - Songname, Album, Artist" 6 "Radio frequency AM" 7 "Radio frequency FM" 8 "Radio station" 9 "USB Video" 10 "USB Picture" 11 "Android Auto" 12 "Apple Carplay" 13 "Device not connected" 14 "Loading" 15 "Invalid";
VAL_ 964 MHU_Nav_State 0 "Disable" 1 "ON" 2 "Ready to drive" 3 "Arrived at the destination - Finish" 4 "Locating  Location position not avaliable" 5 "Rerouting" 6 "On the way" 7 "Signal Invalid";
VAL_ 964 MHU_NavSource 0 "Here Map (Default embedded map)" 1 "Vietmap" 2 "Apple Map" 3 "Google map " 4 "Reserved" 5 "Reserved" 6 "Reserved" 7 "Signal Invalid";
VAL_ 964 MHU_Nav_DistanceToNextTurnUnits 0 "km" 1 "miles" 2 "m" 3 "yards" 4 "ft" 5 "Reserved" 6 "Reserved" 7 "Reserved";
VAL_ 964 MHU_Nav_ImageChannel_Ready 0 "Disable" 1 "Enable" 2 "Power Off" 3 "Signal Invalid";
VAL_ 964 MHU_Nav_Language 0 "Vietnamese" 1 "English" 2 "Chinese (Simplified)" 3 "Traditional Chinese" 4 "French" 5 "German" 6 "Italian" 7 "Japanese" 8 "Korean" 9 "Spanish (Spain)" 10 "Spanish (Latin)" 11 "Portuguese (Portugal)" 12 "Portuguese (Brazil)" 13 "Arabic" 14 "Catalan" 15 "Croatian" 16 "Czech" 17 "Danish" 18 "Dutch" 19 "Finnish" 20 "Greek" 21 "Hebrew" 22 "Hindi" 23 "Hungarian" 24 "Indonesian" 25 "Malay" 26 "Norwegian" 27 "Polish" 28 "Romanian" 29 "Russian" 30 "Slovak" 31 "Swedish" 32 "Turkish" 33 "Thai" 254 "Raw language" 255 "Signal invalid";
VAL_ 992 VCU_RunningRange_chrg_estSts 0 "Not ready" 1 "Processing" 2 "Estimated" 3 "Failed";
VAL_ 992 VCU_HVbatSoc_charged_estStatus 0 "Not ready" 1 "Processing" 2 "Estimated" 3 "Failed";
VAL_ 993 VCU_MHU_Ack_ChgSche_stt 0 "Charging Schedule Enable" 1 "Charging Schedule Disable" 2 "Reserved" 3 "Signal Invalid";
VAL_ 993 VCU_ValetMode_sts 0 "Inactive" 1 "Active" 255 "Invalid";
VAL_ 1015 MFS_VoiceRecognitionOn_Off 0 "Button not Pressed" 1 "Short Press" 2 "Long Press" 3 "Reserved" 4 "Signal invalid";
VAL_ 1015 MFS_ISAControl 0 "Button not Pressed" 1 "Short Press" 2 "Long Press" 3 "Reserved";
VAL_ 1015 MFS_CruiseSpeedIncrease 0 "Button not Pressed" 1 "Short Press" 2 "Long Press" 3 "Reserved" 4 "Signal invalid";
VAL_ 1015 MFS_TelephoneCall_EndCall 0 "Button not Pressed" 1 "Short Press" 2 "Long Press" 3 "Reserved" 4 "Signal invalid";
VAL_ 1015 MFS_LKAControl 0 "Button not Pressed" 1 "Short Press" 2 "Long Press" 3 "Reserved";
VAL_ 1015 MFS_CruiseGapIncrease 0 "Button not Pressed" 1 "Short Press" 2 "Long Press" 3 "Reserved" 4 "Signal invalid";
VAL_ 1015 MFS_CruiseOn_Off 0 "Button not Pressed" 1 "Short Press" 2 "Long Press" 3 "Reserved" 4 "Signal invalid";
VAL_ 1015 MFS_CruiseGapDecrease 0 "Button not Pressed" 1 "Short Press" 2 "Long Press" 3 "Reserved" 4 "Signal invalid";
VAL_ 1015 MFS_CAN_RESControl 0 "Button not Pressed" 1 "Short Press" 2 "Long Press" 3 "Reserved";
VAL_ 1015 MFS_CruiseSpeedDecrease 0 "Button not Pressed" 1 "Short Press" 2 "Long Press" 3 "Reserved" 4 "Signal invalid";
VAL_ 1015 MFS_M2Control 0 "Button not Pressed" 1 "Short Press" 2 "Long Press" 3 "Reserved";
VAL_ 1015 MFS_SourseControl 0 "Button not Pressed" 1 "Short Press" 2 "Long Press" 3 "Reserved" 4 "Signal invalid";
VAL_ 1015 MFS_UpControl 0 "Button not Pressed" 1 "Short Press" 2 "Long Press" 3 "Reserved" 4 "Signal invalid";
VAL_ 1015 MFS_DownControl 0 "Button not Pressed" 1 "Short Press" 2 "Long Press" 3 "Reserved" 4 "Signal invalid";
VAL_ 1015 MFS_LeftControl 0 "Button not Pressed" 1 "Short Press" 2 "Long Press" 3 "Reserved" 4 "Signal invalid";
VAL_ 1015 MFS_Failure 0 "No Error" 1 "Error";
VAL_ 1015 MFS_RightControl 0 "Button not Pressed" 1 "Short Press" 2 "Long Press" 3 "Reserved" 4 "Signal invalid";
VAL_ 1015 MFS_OK_Control 0 "Button not Pressed" 1 "Short Press" 2 "Long Press" 3 "Reserved" 4 "Signal invalid";
VAL_ 1020 XGW_FOTA_StateConfirm 0 "INIT" 1 "NORMAL" 2 "FOTA FLASHING" 3 "FOTA-SUSPENDED" 4 "FAIL-SAFE-ERROR" 5 "SHUTDOWN" 6 "REMOTE DIAGNOSTICS" 7 "Invalid";
VAL_ 1025 MHU_SET_SunroofGlassLevel 0 "Closed" 127 "Vent" 150 "Stop" 255 "No Request";
VAL_ 1025 MHU_SET_BonnetState 0 "Not pressed" 1 "Pressed" 2 "Reserved" 3 "Signal invalid";
VAL_ 1025 MHU_SET_TrunkState 0 "Not pressed" 1 "Pressed" 2 "Reserved" 3 "Signal invalid";
VAL_ 1025 MHU_SET_SunroofShaderLevel 0 "Closed" 150 "Stop" 255 "No Request";
VAL_ 1025 MHU_SET_DoorSpeedLock 0 "OFF" 1 "5KMH" 2 "10KMH" 3 "15KMH" 4 "20KMH" 5 "25KMH" 6 "Signal invalid";
VAL_ 1025 MHU_SET_WelcomeTriggerCondition 0 "Vehicle unLock" 1 "Driver walk toward" 2 "OFF" 3 "Signal invalid";
VAL_ 1025 MHU_SET_AutoSunroof 0 "OFF" 1 "Glass Only" 2 "Glass & Shade" 3 "Signal invalid";
VAL_ 1025 MHU_SET_RemoteDoorUnlock 0 "Driver door" 1 "All doors" 2 "Reserved" 3 "Signal invalid";
VAL_ 1025 MHU_SET_RemoteLockFeedback 0 "Light" 1 "Horn" 2 "Light/Horn" 3 "OFF" 4 "Signal Invalid";
VAL_ 1025 MHU_SET_FootkickSensor 0 "OFF" 1 "ON" 2 "Reserved" 3 "Signal invalid";
VAL_ 1025 MHU_SET_AutoUnlockDoor 0 "OFF" 1 "On" 2 "Reserved" 3 "Signal Invalid";
VAL_ 1025 MHU_SET_RemoteUnlockFeedback 0 "Blinking" 1 "Dimming" 2 "Low Beam ON" 3 "OFF" 4 "Signal Invalid";
VAL_ 1025 MHU_SET_Childlock 0 "OFF" 1 "ON" 2 "Reserved" 3 "Signal invalid";
VAL_ 1025 WalkawayDoorLock 0 "OFF" 1 "ON";
VAL_ 1025 MHU_SET_SunroofInitialize 0 "Inactive - Default" 1 "Initialisation" 2 "Manual Open Sunroof" 3 "Manual Close Sunroof" 4 "Manual Open Sunshade" 5 "Manuel Close Sunshade" 6 "Reserved" 7 "Signal invalid";
VAL_ 1026 MHU_SET_DayTimeRunningLight 0 "OFF" 1 "ON" 2 "Reserved" 3 "Signal invalid";
VAL_ 1026 MHU_SET_RearFogLight 0 "OFF" 1 "ON" 2 "Reserved" 3 "Signal invalid";
VAL_ 1026 MHU_SET_FrontFogLight 0 "OFF" 1 "ON" 2 "Reserved" 3 "Signal invalid";
VAL_ 1026 MHU_SET_WelcomeDimmingHeadlight 0 "OFF" 1 "ON" 2 "Reserved" 3 "Signal invalid";
VAL_ 1026 MHU_SET_FootwellLightMode 0 "OFF" 1 "ON" 2 "AUTO" 3 "Signal invalid";
VAL_ 1026 MHU_SET_ExteriorLight 0 "OFF" 1 "Parking" 2 "ON" 3 "AUTO" 4 "Signal invalid";
VAL_ 1026 MHU_SET_TRWarningSignals 0 "Off BCM warning signals" 1 "On BCM warning signals" 2 "Reserved" 3 "Signal Invalid";
VAL_ 1026 MHU_SET_FrontDomeLamp 0 "OFF" 1 "ON" 2 "AUTO" 3 "Signal invalid";
VAL_ 1026 MHU_SET_HazardLight 3 "Signal Invalid" 2 "Reserved" 1 "ON" 0 "OFF" ;
VAL_ 1026 MHU_SET_FollowMeHome 0 "OFF" 1 "30 secs" 2 "60 secs" 3 "90 secs" 4 "120 secs" 5 "Signal invalid";
VAL_ 1026 MHU_SET_ADB_AHB 0 "OFF" 1 "ON" 2 "Reserved" 3 "Signal Invalid";
VAL_ 1026 MHU_SET_WelcomeAnimation 0 "OFF" 1 "Light dance" 2 "Vegas blink" 3 "Pulse and blink" 4 "Reserved" 5 "Signal invalid";
VAL_ 1026 MHU_SET_ChargingAnimation 0 "OFF" 1 "ON" 2 "Reserved" 3 "Signal invalid";
VAL_ 1026 MHU_SET_Auto_Leveling 0 "OFF" 1 "ON" 2 "Reserved" 3 "Signal Invalid";
VAL_ 1027 MHU_AutoP_Setting 0 "ON" 1 "OFF" 2 "Reserved" 3 "Signal Invalid";
VAL_ 1027 MHU_VCU_CreepDisable_stt 0 "No request" 1 "Creep Disable request";
VAL_ 1027 MHU_BrakeRegenMode 0 "HIGH" 1 "MID" 2 "LOW" 3 "OFF";
VAL_ 1027 MHU_ChargeScheduleSet 0 "disable" 1 "Enable" 2 "No effect" 3 "Invalid";
VAL_ 1027 MHU_ChargingRequest 0 "Stop charging" 1 "Start charging" 2 "Pause charging" 3 "No effect";
VAL_ 1027 MHU_ChgPort_Open_req 0 "No request" 1 "Requesting" 2 "Reserved" 3 "Signal invalid";
VAL_ 1027 MHU_SET_DrivingModeSwitch 0 "NORMAL" 1 "ECO" 2 "SPORT" 3 "Signal invalid";
VAL_ 1027 MHU_ValetMode_Activation 0 "Inactive" 1 "Active" 2 "No effect" 255 "Invalid";
VAL_ 1027 MHU_SET_ActivePreCondition 0 "OFF" 1 "ON" 2 "Reserved" 3 "Reserved";
VAL_ 1028 MHU_SET_MirrorAdjustLeft 0 "OFF" 1 "ON" 2 "Reserved" 3 "Signal invalid";
VAL_ 1028 MHU_SET_MirrorAdjustRight 0 "OFF" 1 "ON" 2 "Reserved" 3 "Signal invalid";
VAL_ 1028 MHU_SET_MirrorManual 0 "Fold" 1 "Unfold" 2 "Reserved" 3 "Signal invalid";
VAL_ 1029 MHU_SET_CCUF_AirCondition 0 "Not pressed" 1 "Pressed" 2 "Reserved" 3 "Signal invalid";
VAL_ 1029 MHU_SET_CCUF_AutoAC 0 "Not pressed" 1 "Pressed" 2 "Reserved" 3 "Signal invalid";
VAL_ 1029 MHU_SET_CCUF_MaxAc 0 "Not pressed" 1 "Pressed" 2 "Reserved" 3 "Signal invalid";
VAL_ 1029 MHU_SET_CCUF_FanSpeed 0 "OFF" 1 "Level1" 2 "Level2" 3 "Level3" 4 "Level4" 5 "Level5" 6 "Level6" 7 "Signal invalid";
VAL_ 1029 MHU_SET_CCUF_Recirculation 0 "Inside" 1 "Outside" 2 "Auto" 3 "Signal invalid";
VAL_ 1029 MHU_SET_CCUF_Ion 0 "Not pressed" 1 "Pressed" 2 "Reserved" 3 "Signal invalid";
VAL_ 1029 MHU_SET_CCUF_FlapPosition 0 "OFF" 1 "Face" 2 "Face and Feet" 3 "Feet" 4 "Feet and Defrost" 5 "Defrost" 6 "Default" 7 "Signal Invalid";
VAL_ 1029 MHU_SET_CCUF_SyncClimateZone 0 "Not pressed" 1 "Pressed" 2 "Reserved" 3 "Signal invalid";
VAL_ 1029 MHU_SET_CCUF_TempDriver 32 "16" 33 "16.5" 34 "17" 35 "17.5" 36 "18" 37 "18.5" 38 "19" 39 "19.5" 40 "20" 41 "20.5" 42 "21" 43 "21.5" 44 "22" 45 "22.5" 46 "23" 47 "23.5" 48 "24" 49 "24.5" 50 "25" 51 "25.5" 52 "26" 53 "26.5" 54 "27" 55 "27.5" 56 "28" 57 "28.5" 58 "29" 59 "29.5" 60 "30" 61 "30.5" 62 "31" 63 "31.5" 64 "32" 255 "Invalid Value" ;
VAL_ 1029 MHU_SET_CCUF_TempPassenger 32 "16" 33 "16.5" 34 "17" 35 "17.5" 36 "18" 37 "18.5" 38 "19" 39 "19.5" 40 "20" 41 "20.5" 42 "21" 43 "21.5" 44 "22" 45 "22.5" 46 "23" 47 "23.5" 48 "24" 49 "24.5" 50 "25" 51 "25.5" 52 "26" 53 "26.5" 54 "27" 55 "27.5" 56 "28" 57 "28.5" 58 "29" 59 "29.5" 60 "30" 61 "30.5" 62 "31" 63 "31.5" 64 "32" 255 "Invalid Value" ;
VAL_ 1029 MHU_SET_CCUF_FrontDefrost 0 "Not pressed" 1 "Pressed" 2 "Reserved" 3 "Signal invalid";
VAL_ 1030 MHU_SET_SeatHeatingFrontL 0 "OFF" 1 "Level1" 2 "Level2" 3 "Level3" 4 "Signal invalid";
VAL_ 1030 MHU_SET_SeatHeatingFrontR 0 "OFF" 1 "Level1" 2 "Level2" 3 "Level3" 4 "Signal invalid";
VAL_ 1030 MHU_SET_SeatHeatingReartL 0 "OFF" 1 "Level1" 2 "Level2" 3 "Level3" 4 "Signal invalid";
VAL_ 1030 MHU_SET_SeatHeatingRearR 0 "OFF" 1 "Level1" 2 "Level2" 3 "Level3" 4 "Signal invalid";
VAL_ 1030 MHU_SET_SeatCoolingFrontL 0 "OFF" 1 "Level1" 2 "Level2" 3 "Level3" 4 "Signal invalid";
VAL_ 1030 MHU_SET_SeatCoolingFrontR 0 "OFF" 1 "Level1" 2 "Level2" 3 "Level3" 4 "Signal invalid";
VAL_ 1030 MHU_SET_SeatCoolingRearL 0 "OFF" 1 "Level1" 2 "Level2" 3 "Level3" 4 "Signal invalid";
VAL_ 1030 MHU_SET_SeatCoolingRearR 0 "OFF" 1 "Level1" 2 "Level2" 3 "Level3" 4 "Signal invalid";
VAL_ 1032 MHU_SET_MirrorAuto 0 "OFF" 1 "ON" 2 "Reserved" 3 "Signal invalid";
VAL_ 1032 MHU_SET_MirrorAutoUnfold 0 "Vehicle Unlock" 1 "Driver walk toward" 2 "OFF" 3 "Signal invalid";
VAL_ 1032 MHU_SET_WLC 0 "OFF" 1 "ON" 2 "Reserved" 3 "Signal invalid";
VAL_ 1032 MHU_SET_AutoRearWiper 0 "OFF" 1 "ON" 2 "Reserved" 3 "Signal invalid";
VAL_ 1032 MHU_SET_RearHeatedWindow 0 "Not pressed" 1 "Pressed" 2 "Reserved" 3 "Signal invalid";
VAL_ 1032 MHU_TPMSReset 0 "Noreset" 1 "Reset" 2 "Reserved" 3 "Signal invalid";
VAL_ 1032 MHU_SET_MirrorDefaultSetting 0 "Not pressed" 1 "Pressed" 2 "Reserved" 3 "Signal invalid";
VAL_ 1032 MHU_SET_MirrorReverseLink 0 "OFF" 1 "Right Mirror" 2 "Left Mirror" 3 "Both Mirror";
VAL_ 1032 MHU_SET_AntiTheftMode 0 "OFF" 1 "Light Only" 2 "Horn Only" 3 "Light and Horn";
VAL_ 1032 MHU_SET_WLCReminder 0 "OFF" 1 "ON" 2 "Reserved" 3 "Signal invalid";
VAL_ 1032 MHU_SET_ClimateKeepOn 0 "OFF" 1 "PET" 2 "CAMP" 3 "REMOTE CONTROL";
VAL_ 1032 MHU_SET_WLC2 0 "OFF" 1 "ON" 2 "Reserved" 3 "Signal invalid";
VAL_ 1032 MHU_SET_WLC2Reminder 0 "OFF" 1 "ON" 2 "Reserved" 3 "Signal invalid";
VAL_ 1032 MHU_IntrusionAlertStatus 0 "OFF" 1 "ON" 2 "Stop Alarm" 3 "Signal invalid";
VAL_ 1033 ADAS_Warning_Flag_1 0 "No Error" 1 "Error";
VAL_ 1033 ADAS_Warning_Flag_2 0 "No Error" 1 "Error";
VAL_ 1033 ADAS_Warning_Flag_3 0 "No Error" 1 "Error";
VAL_ 1033 ADAS_Warning_Flag_4 0 "No Error" 1 "Error";
VAL_ 1033 ADAS_Warning_Flag_5 0 "No Error" 1 "Error";
VAL_ 1033 ADAS_Warning_Flag_6 0 "No Error" 1 "Error";
VAL_ 1033 ADAS_Warning_Flag_7 0 "No Error" 1 "Error";
VAL_ 1033 ADAS_Warning_Flag_8 0 "No Error" 1 "Error";
VAL_ 1033 ADAS_Warning_Flag_9 0 "No Error" 1 "Error";
VAL_ 1033 ADAS_Warning_Flag_10 0 "No Error" 1 "Error";
VAL_ 1033 ADAS_Warning_Flag_11 0 "No Error" 1 "Error";
VAL_ 1033 ADAS_Warning_Flag_12 0 "No Error" 1 "Error";
VAL_ 1033 ADAS_Warning_Flag_13 0 "No Error" 1 "Error";
VAL_ 1033 ADAS_Warning_Flag_14 0 "No Error" 1 "Error";
VAL_ 1033 ADAS_Warning_Flag_15 0 "No Error" 1 "Error";
VAL_ 1033 ADAS_Warning_Flag_16 0 "No Error" 1 "Error";
VAL_ 1033 ADAS_Warning_Flag_17 0 "No Error" 1 "Error";
VAL_ 1033 ADAS_Warning_Flag_18 0 "No Error" 1 "Error";
VAL_ 1033 ADAS_Warning_Flag_19 0 "No Error" 1 "Error";
VAL_ 1033 ADAS_Warning_Flag_20 0 "No Error" 1 "Error";
VAL_ 1033 ADAS_Warning_Flag_21 0 "No Error" 1 "Error";
VAL_ 1033 ADAS_Warning_Flag_22 0 "No Error" 1 "Error";
VAL_ 1033 ADAS_Warning_Flag_23 0 "No Error" 1 "Error";
VAL_ 1033 ADAS_Warning_Flag_24 0 "No Error" 1 "Error";
VAL_ 1033 ADAS_Warning_Flag_25 0 "No Error" 1 "Error";
VAL_ 1033 ADAS_Warning_Flag_26 0 "No Error" 1 "Error";
VAL_ 1033 ADAS_Warning_Flag_27 0 "No Error" 1 "Error";
VAL_ 1033 ADAS_Warning_Flag_28 0 "No Error" 1 "Error";
VAL_ 1033 ADAS_Warning_Flag_29 0 "No Error" 1 "Error";
VAL_ 1033 ADAS_Warning_Flag_30 0 "No Error" 1 "Error";
VAL_ 1033 ADAS_Warning_Flag_31 0 "No Error" 1 "Error";
VAL_ 1033 ADAS_Warning_Flag_32 0 "No Error" 1 "Error";
VAL_ 1033 ADAS_Warning_Flag_33 0 "No Error" 1 "Error";
VAL_ 1033 ADAS_Warning_Flag_34 0 "No Error" 1 "Error";
VAL_ 1033 ADAS_Warning_Flag_35 0 "No Error" 1 "Error";
VAL_ 1033 ADAS_Warning_Flag_36 0 "No Error" 1 "Error";
VAL_ 1033 ADAS_Warning_Flag_37 0 "No Error" 1 "Error";
VAL_ 1033 ADAS_Warning_Flag_38 0 "No Error" 1 "Error";
VAL_ 1033 ADAS_Warning_Flag_39 0 "No Error" 1 "Error";
VAL_ 1033 ADAS_Warning_Flag_40 0 "No Error" 1 "Error";
VAL_ 1033 ADAS_Warning_Flag_41 0 "No Error" 1 "Error";
VAL_ 1033 ADAS_Warning_Flag_42 0 "No Error" 1 "Error";
VAL_ 1033 ADAS_Warning_Flag_43 0 "No Error" 1 "Error";
VAL_ 1033 ADAS_Warning_Flag_44 0 "No Error" 1 "Error";
VAL_ 1033 ADAS_Warning_Flag_45 0 "No Error" 1 "Error";
VAL_ 1033 ADAS_Warning_Flag_46 0 "No Error" 1 "Error";
VAL_ 1033 ADAS_Warning_Flag_47 0 "No Error" 1 "Error";
VAL_ 1033 ADAS_Warning_Flag_48 0 "No Error" 1 "Error";
VAL_ 1033 ADAS_Warning_Flag_49 0 "No Error" 1 "Error";
VAL_ 1033 ADAS_Warning_Flag_50 0 "No Error" 1 "Error";
VAL_ 1033 ADAS_Warning_Flag_51 0 "No Error" 1 "Error";
VAL_ 1034 MHU_SET_HudTurnSigOnOff 0 "OFF" 1 "ON";
VAL_ 1034 MHU_SET_HudBSDOnOff  0 "OFF" 1 "ON";
VAL_ 1034 MHU_SET_HudRCTAOnOff 0 "OFF" 1 "ON";
VAL_ 1034 MHU_SET_HudUIContent 0 "Default (Only speed)" 1 "+ADAS" 2 "+Navigation" 3 "+ADAS + Navigation" 4 "+ Power-Regen gauge" 5 "+ Power-Regen gauge + ADAS" 6 "+ Power-Regen gauge + Navigation" 7 "+ Power-Regen + ADAS + Navigation";
VAL_ 1034 MHU_SET_HudUIColor 0 "White (Default)" 1 "Green" 2 "Orange";
VAL_ 1034 MHU_SET_HudScreenOnOFF 0 "OFF" 1 "ON" 2 "Reserved" 3 "Signal invalid";
VAL_ 1034 MHU_SET_UserBrightnessLvl 0 "No action" 1 "Level 1" 2 "Level 2" 3 "Level 3" 4 "Level 4" 5 "Level 5" 6 "Level 6" 7 "Level 7" 8 "Level 8 " 9 "Level 9" 10 "Level 10" 11 "Level 11" 12 "Level 12" 13 "Level 13" 14 "Level 14" 15 "Level 15" 16 "Level 16" 17 "Level 17" 18 "Level 18" 19 "Level 19" 20 "Level 20" 21 "Level 21 " 22 "Reserved" 23 "Reserved" 24 "Reserved" 25 "Reserved" 26 "Reserved" 27 "Reserved" 28 "Reserved" 29 "Reserved" 30 "Reserved" 31 "Reserved";
VAL_ 1034 MHU_SET_HudWorkingMode 0 "Working Mode" 1 "Position adjustment Mode" 2 "EOL Mode" 3 "Engineering mode";
VAL_ 1034 MHU_SET_HudUISize 0 "Small" 1 "Mid" 2 "Large" 3 "Reserved";
VAL_ 1034 MHU_SET_UIContentMediaInfo 0 "OFF" 1 "ON";
VAL_ 1034 MHU_SET_UIContentCallInfo 0 "OFF" 1 "ON";
VAL_ 1034 MHU_SET_UIContentPoweRegen 0 "OFF" 1 "ON";
VAL_ 1035 MHU_SET_AvasSound 0 "Enhanced" 1 "Normal" 2 "Minimized" 3 "OFF";
VAL_ 1036 MHU_DrvSeat_Control_Status 0 "Idle" 1 "Request seat moving" 2 "Reserved" 3 "Invalid value";
VAL_ 1046 BCM_STAT_Mirror 0 "Fold" 1 "Unfold" 2 "Reserved" 3 "Signal Invalid";
VAL_ 1046 BCM_STAT_MirrorAdjustLeft 0 "OFF" 1 "ON" 2 "Reserved" 3 "Signal invalid";
VAL_ 1046 BCM_STAT_MirrorAdjustRight 0 "OFF" 1 "ON" 2 "Reserved" 3 "Signal invalid";
VAL_ 1049 SHVU_STAT_SeatHeatingFrontL 0 "OFF" 1 "Level1" 2 "Level2" 3 "Level3" 4 "Signal invalid";
VAL_ 1049 SHVU_STAT_SeatHeatingFrontR 0 "OFF" 1 "Level1" 2 "Level2" 3 "Level3" 4 "Signal invalid";
VAL_ 1049 SHVU_STAT_SeatCoolingFrontL 0 "OFF" 1 "Level1" 2 "Level2" 3 "Level3" 4 "Signal invalid";
VAL_ 1049 SHVU_STAT_SeatCoolingFrontR 0 "OFF" 1 "Level1" 2 "Level2" 3 "Level3" 4 "Signal invalid";
VAL_ 1049 SHVU_STAT_FrontSeatVentSts 0 "Normal Operation" 1 "Failure" 2 "Reserved" 3 "Signal invalid";
VAL_ 1050 SHVU_STAT_SeatCoolingRearL 0 "OFF" 1 "Level1" 2 "Level2" 3 "Level3" 4 "Signal invalid";
VAL_ 1050 SHVU_STAT_SeatCoolingRearR 0 "OFF" 1 "Level1" 2 "Level2" 3 "Level3" 4 "Signal invalid";
VAL_ 1050 SHVU_STAT_SeatHeatingReartL 0 "OFF" 1 "Level1" 2 "Level2" 3 "Level3" 4 "Signal invalid";
VAL_ 1050 SHVU_STAT_SeatHeatingRearR 0 "OFF" 1 "Level1" 2 "Level2" 3 "Level3" 4 "Signal invalid";
VAL_ 1050 SHVU_STAT_RearSeatVentSts 0 "Normal Operation" 1 "Failure" 2 "Reserved" 3 "Signal invalid";
VAL_ 1052 PSM_Seat_track_pos_Dri 0 "Front position" 1 "Not Front position" 2 "Failure" 3 "Invalid Value";
VAL_ 1052 PSM_Seat_track_posPas 0 "Front position" 1 "Not Front position" 2 "Failure" 3 "Invalid Value";
VAL_ 1053 BCM_STAT_AutoRearWiper 0 "OFF" 1 "ON" 2 "Reserved" 3 "Signal invalid";
VAL_ 1053 BCM_STAT_MirrorFoldSetting 0 "Auto Fold OFF" 1 "Auto Fold ON" 2 "Reserved" 3 "Signal invalid";
VAL_ 1053 BCM_STAT_IMMO_KeyfobID2 0 "No trigger from MHU" 1 "Fob1" 2 "Fob2" 3 "key illegal" 4 "No key found" 5 "Searching" 6 "Reserved" 7 "Signal invalid";
VAL_ 1053 BCM_STAT_MirrorAutoUnfold 0 "Vehicle Unlock" 1 "Driver walk toward" 2 "OFF" 3 "Signal invalid";
VAL_ 1053 BCM_STAT_MirrorReverseLink 0 "OFF" 1 "Right Mirror" 2 "Left Mirror" 3 "Both Mirror";
VAL_ 1053 BCM_STAT_MirrorDefaultSTATting 0 "Not pressed" 1 "Pressed" 2 "Reserved" 3 "Signal invalid";
VAL_ 1053 BCM_STAT_WelcomeTriggerCondition 0 "Vehicle unLock" 1 "Driver walk toward" 2 "OFF" 3 "Signal invalid";
VAL_ 1053 BCM_STAT_FrontDomeLamp 0 "OFF" 1 "ON" 2 "AUTO" 3 "Signal invalid";
VAL_ 1053 BCM_STAT_FollowMeHome 0 "OFF" 1 "30 secs" 2 "60 secs" 3 "90 secs" 4 "120 secs" 5 "Signal invalid";
VAL_ 1053 BCM_STAT_ExteriorLight 0 "OFF" 1 "Parking" 2 "ON" 3 "AUTO" 4 "Signal invalid";
VAL_ 1053 BCM_STAT_RemoteLockFeedback 0 "OFF" 1 "Lights and Horn" 2 "Lights Only" 3 "Horn Only" 4 "Reserved" 5 "Reserved" 6 "Reserved" 7 "Signal invalid";
VAL_ 1053 BCM_STAT_RemoteDoorUnlock 0 "Reserved" 1 "Driver door" 2 "All doors" 3 "Signal invalid";
VAL_ 1053 BCM_STAT_AutoDoorUnlock 0 "OFF" 1 "ON" 2 "Reserved" 3 "Signal invalid";
VAL_ 1053 BCM_STAT_WalkawayDoorLock 0 "OFF" 1 "ON";
VAL_ 1053 BCM_STAT_WiperServiceMode 0 "OFF" 1 "ON" 2 "Reserved" 3 "Signal Invalid";
VAL_ 1053 BCM_STAT_IMMO_KeyfobID 0 "No Key Found" 1 "ID1" 2 "ID2" 3 "Signal Invalid";
VAL_ 1053 BCM_STAT_RearHeatedWindowMirror 0 "OFF" 1 "ON" 2 "Reserved" 3 "Signal invalid";
VAL_ 1053 BCM_STAT_AntiTheftMode 0 "OFF" 1 "Light Only" 2 "Horn Only" 3 "Light and Horn" 4 "Signal invalid";
VAL_ 1053 BCM_STAT_ClimateKeepOnSts 0 "OFF" 1 "PET" 2 "CAMP" 3 "REMOTE CONTROL";
VAL_ 1053 BCM_STAT_FKSfeedback 0 "OFF" 1 "ON" 2 "Reserved" 3 "Signal Invalid";
VAL_ 1054 HUD_UIColor 0 "White (Default)" 1 "Green" 2 "Orange";
VAL_ 1054 HUD_UIContent 0 "Default (Only speed)" 1 "+ADAS" 2 "+Navigation" 3 "+ADAS + Navigation" 4 "+ Power-Regen gauge" 5 "+ Power-Regen gauge + ADAS" 6 "+ Power-Regen gauge + Navigation" 7 "+ Power-Regen + ADAS + Navigation";
VAL_ 1054 HUD_OperationState 0 "Invalid" 1 "Standby" 2 "Screen ON" 3 "Reserved";
VAL_ 1054 HUD_HeightLvl 0 "No action" 1 "Level 1" 2 "Level 2" 3 "Level 3" 4 "Level 4" 5 "Level 5" 6 "Level 6" 7 "Level 7" 8 "Level 8" 9 "Level 9" 10 "Level 10" 11 "Level 11" 12 "Level 12" 13 "Level 13" 14 "Level 14" 15 "Level 15" 16 "Level 16" 17 "Level 17" 18 "Level 18" 19 "Level 19" 20 "Level 20" 21 "Level 21" 22 "Reserved";
VAL_ 1054 HUD_UI_Size 0 "Small" 1 "Mid" 2 "Big" 3 "Reserved";
VAL_ 1054 HUD_UIContentMediaInfo 0 "OFF" 1 "ON";
VAL_ 1054 HUD_UIContentCallInfor 0 "OFF" 1 "ON";
VAL_ 1054 HUD_UIContentPowerRegen 0 "OFF" 1 "ON";
VAL_ 1054 HUD_TurnSigOnOff_Feed 0 "OFF" 1 "ON";
VAL_ 1054 HUD_BSDOnOff_Feed 0 "OFF" 1 "ON";
VAL_ 1054 HUD_RCTAOnOff_Feed 0 "OFF" 1 "ON";
VAL_ 1054 HUD_UIModeSignal 0 "Normal" 1 "Reserved" 2 "Reserved" 3 "Reserved" 4 "Reserved" 5 "Reserved" 6 "Reserved" 7 "Reserved";
VAL_ 1054 HUD_WorkingMode 0 "Working Mode" 1 "Position adjustment Mode" 2 "EOL Mode" 3 "Engineering mode";
VAL_ 1054 HUD_RotateAngleLvl 0 "No action" 1 "Level 1" 2 "Level 2" 3 "Level 3" 4 "Level 4" 5 "Level 5" 6 "Level 6" 7 "Level 7" 8 "Level 8 " 9 "Level 9" 10 "Level 10" 11 "Level 11" 12 "Level 12" 13 "Level 13" 14 "Level 14" 15 "Level 15";
VAL_ 1054 HUD_UserSetBrightnessLvl 0 "No action" 1 "Level 1" 2 "Level 2" 3 "Level 3" 4 "Level 4" 5 "Level 5" 6 "Level 6" 7 "Level 7" 8 "Level 8 " 9 "Level 9" 10 "Level 10" 11 "Level 11" 12 "Level 12" 13 "Level 13" 14 "Level 14" 15 "Level 15" 16 "Level 16" 17 "Level 17" 18 "Level 18" 19 "Level 19" 20 "Level 20" 21 "Level 21 " 22 "Reserved" 23 "Reserved" 24 "Reserved" 25 "Reserved" 26 "Reserved" 27 "Reserved" 28 "Reserved" 29 "Reserved" 30 "Reserved" 31 "Reserved";
VAL_ 1054 HUD_Language 0 "Vietnamese" 1 "English" 2 "Spanish" 3 "French" 4 "German" 5 "Dutch" 6 "English (CANADA)" 7 "French (CANADA)" 8 "Russian" 9 "Spanish (Latin America)" 10 "Portuguese" 11 "Portuguese (Brasil)" 12 "Chinese, simplipied" 13 "Chinese, traditional" 14 "Reserved" 15 "Reserved" 16 "Reserved" 17 "Reserved" 18 "Reserved" 19 "Reserved" 20 "Reserved" 21 "Reserved" 22 "Reserved" 23 "Reserved" 24 "Reserved" 25 "Reserved" 26 "Reserved" 27 "Reserved" 28 "Reserved" 29 "Reserved" 30 "Reserved" 31 "Signal invalid";
VAL_ 1054 HUD_Mileage_Unit 0 "Km" 1 "Mile";
VAL_ 1054 HUD_UserProfileId 0 "User 1 - Guess mode" 1 "User 2 - Valet mode" 2 "User 3" 3 "User 4" 4 "User 5" 5 "User 6" 6 "User 7" 7 "User 8" 8 "User 9" 9 "User 10" 10 "User 11" 11 "User 12" 12 "User 13" 13 "User 14" 14 "User 15" 15 "Invalid Value";
VAL_ 1054 HUD_DimmingDelayTime 0 "No delay" 1 "0.5" 2 "Reserved" 3 "Reserved";
VAL_ 1055 ADAS_SVM_LCamera_Fault 0 "No fault" 1 "Temp fault(clean fix)" 2 "Temp fault(Environment)" 3 "Permanent fault";
VAL_ 1055 ADAS_SVM_FCamera_Fault 0 "No fault" 1 "Temp fault(clean fix)" 2 "Temp fault(Environment)" 3 "Permanent fault";
VAL_ 1055 ADAS_SRR_RR_Fault 0 "No fault" 1 "Temp fault(clean fix)" 2 "Temp fault(Environment)" 3 "Permanent fault";
VAL_ 1055 ADAS_SRR_FR_Fault 0 "No fault" 1 "Temp fault(clean fix)" 2 "Temp fault(Environment)" 3 "Permanent fault";
VAL_ 1055 ADAS_SVM_RCamera_Fault 0 "No fault" 1 "Temp fault(clean fix)" 2 "Temp fault(Environment)" 3 "Permanent fault";
VAL_ 1055 ADAS_SCAM_Fault 0 "No fault" 1 "Temp fault(clean fix)" 2 "Temp fault(Environment)" 3 "Permanent fault";
VAL_ 1055 ADAS_MRR_Fault 0 "No fault" 1 "Temp fault(clean fix)" 2 "Temp fault(Environment)" 3 "Permanent fault";
VAL_ 1055 ADAS_SRR_RL_Fault 0 "No fault" 1 "Temp fault(clean fix)" 2 "Temp fault(Environment)" 3 "Permanent fault";
VAL_ 1055 ADAS_SVM_RightCamera_Fault 0 "No fault" 1 "Temp fault(Environment)" 2 "Permanent Fault";
VAL_ 1055 ADAS_ECU_Fault 0 "No fault" 1 "Temp fault" 2 "Reserved" 3 "Description for the value '0x3'";
VAL_ 1055 ADAS_SRR_FL_Fault 0 "No fault" 1 "Temp fault(clean fix)" 2 "Temp fault(Environment)" 3 "Permanent fault";
VAL_ 1055 ADAS_APAUSS_Rear_Fault 0 "No fault" 1 "Temp fault(clean fix)" 2 "Temp fault(Environment)" 3 "Permanent fault";
VAL_ 1055 ADAS_APAUSS_Front_Fault 0 "No fault" 1 "Temp fault(clean fix)" 2 "Temp fault(Environment)" 3 "Permanent fault";
VAL_ 1058 MHU_STAT_Cluster 0 "OFF" 1 "ON" 2 "Reserved" 3 "Signal invalid";
VAL_ 1058 MHU_STAT_Infotainment 0 "OFF" 1 "ON" 2 "Reserved" 3 "Signal invalid";
VAL_ 1058 MHU_STAT_MileageUnit 0 "Mile" 1 "KM" 2 "Reserved" 3 "Signal invalid";
VAL_ 1058 MHU_STAT_PressureUnit 0 "Bar" 1 "Psi" 2 "Kpa" 3 "Signal invalid";
VAL_ 1058 MHU_STAT_TemperatureUnit 0 "Celcius" 1 "Fahrenheit" 2 "Reserved" 3 "Signal invalid";
VAL_ 1058 MHU_STAT_DateTimeFormat 0 "24H" 1 "12H" 2 "Reserved" 3 "Signal invalid";
VAL_ 1058 MHU_Operation_State 0 "Sleep - Low power mode" 1 "Standby/Screen OFF" 2 "Booting/Rebooting" 3 "Running" 4 "Standby/Fullscreen" 5 "OTA progess" 6 "Fault" 7 "Signal Invalid";
VAL_ 1058 MHU_STAT_Language 0 "Vietnamese" 1 "English" 2 "Spanish" 3 "French" 4 "German" 5 "Dutch" 6 "English (CANADA)" 7 "French (CANADA)" 8 "Russian" 9 "Spanish (Latin America)" 10 "Portuguese" 11 "Portuguese (Brasil)" 12 "Chinese, simplipied" 13 "Chinese, traditional" 14 "Reserved" 15 "Reserved" 16 "Reserved" 17 "Reserved" 18 "Reserved" 19 "Reserved" 20 "Reserved" 21 "Reserved" 22 "Reserved" 23 "Reserved" 24 "Reserved" 25 "Reserved" 26 "Reserved" 27 "Reserved" 28 "Reserved" 29 "Reserved" 30 "Reserved" 31 "Signal invalid";
VAL_ 1058 MHU_STAT_EnergyConsumptionUnit 0 "KWH/100KM" 1 "KM/KWH" 2 "Mile per KWH" 3 "KWH/100mil" 4 "Reserved" 5 "Reserved" 6 "Reserved" 7 "Signal invalid";
VAL_ 1058 MHU_STAT_BatLvlPopsetting 0 "20%" 1 "30%" 2 "40%" 3 "50%" 4 "60%" 5 "70%" 6 "Signal Invalid";
VAL_ 1058 MHU_STAT_DistToEmptyUnit 0 "%percentage" 1 "KM/Mi" 2 "Reserved" 3 "Signal Invalid";
VAL_ 1059 AVAS_BatteryUnderVoltage 0 "Normal" 1 "Failure";
VAL_ 1059 AVAS_BatteryOverVoltage 0 "Normal" 1 "Failure";
VAL_ 1059 AVAS_VINInfoNotPrgm 0 "Normal" 1 "Failure";
VAL_ 1059 AVAS_AMPVoltSplDrvOperationFail 0 "Normal" 1 "Failure";
VAL_ 1059 AVAS_AMPIntFaultOverCurr 0 "Normal" 1 "Failure";
VAL_ 1059 AVAS_AMPInternalFaultDCError 0 "Normal" 1 "Failure";
VAL_ 1059 AVAS_AMPInternalFaultOverTemp 0 "Normal" 1 "Failure";
VAL_ 1059 AVAS_AMPInternalFaultClockError 0 "Normal" 1 "Failure";
VAL_ 1059 AVAS_SpkrMntPwrSwDrvHighFlt 0 "Normal" 1 "Failure";
VAL_ 1059 AVAS_SpkrMntPwrSwDrvLowFlt 0 "Normal" 1 "Failure";
VAL_ 1059 AVAS_InternalSpeakerOpen 0 "Normal" 1 "Failure";
VAL_ 1059 AVAS_ECUMalFlshOperationErr 0 "Normal" 1 "Failure";
VAL_ 1059 AVAS_ECUMalfunctionRamFailure 0 "Normal" 1 "Failure";
VAL_ 1059 AVAS_ECUMalEEPROMFailure 0 "Normal" 1 "Failure";
VAL_ 1059 AVAS_CANBusOff 0 "Normal" 1 "Failure";
VAL_ 1059 AVAS_LossCommVehicleSpeed 0 "Normal" 1 "Failure";
VAL_ 1059 AVAS_LossCommGearPosition 0 "Normal" 1 "Failure";
VAL_ 1059 AVAS_LossCommAVASCloseCmd 0 "Normal" 1 "Failure";
VAL_ 1068 PSM_D_DrvSeat_Control_Status 0 "Idle" 1 "Moving by MHU" 2 "Moving by switch" 3 "Failure" 4 "Reserved" 5 "Reserved" 6 "Reserved" 7 "Invalid";
VAL_ 1069 XGW_WasherFluid_LevelSwitch 0 "Empty" 1 "Not Empty" 2 "error" 3 "Invalid signal";
VAL_ 1070 XGW_HLVerLvlMode 0 "OFF" 1 "AUTO Head lamp leveling ON" 2 "Reserved" 3 "Invalid";
VAL_ 1070 XGW_AutoHeadlamp_LvlSts 0 "Inactive" 1 "Active" 2 "Error" 3 "Signal invalid";
VAL_ 1073 HUD_ECU_Check 0 "Normal" 1 "LCD fail" 2 "LCD overhead" 3 "Step motor lost step" 4 "Low temperature";
VAL_ 1073 HUD_ECU_Fault 0 "Normal" 1 "Abnormal";
VAL_ 1074 MHU_FOTA_State 0 "INIT" 1 "NORMAL" 2 "FOTA FLASHING" 3 "FOTA-SUSPENDED" 4 "FAIL-SAFE-ERROR" 5 "SHUTDOWN" 6 "REMOTE DIAGNOSTICS" 7 "Invalid";
VAL_ 1075 MHU_HLVerLvlMode 0 "OFF" 1 "AUTO Head lamp enable" 2 "Reserved" 3 "Invalid";
VAL_ 1076 ADAS_DMS_DRIVER_IDENTIFICATION 0 "Initial" 1 " ID 1" 2 " ID 2" 3 " ID 3" 4 " ID 4" 5 "ID 5" 6 "ID 6" 7 "ID 7" 8 "ID 8" 9 "ID 9" 10 "ID 10" 11 "ID 11" 12 "ID 12" 13 "ID 13" 14 "ID 14" 15 "ID 15";
VAL_ 1076 ADAS_DMS_DROWS_DISTRACTION_LVL 0 "Init" 1 "Drowsiness lvl 1" 2 "Drowsiness lvl 2" 3 "Drowsiness lvl 3" 4 "Drowsiness lvl 4" 5 "HOD lvl 1" 6 "HOD lvl 2" 7 "HOD lvl 3" 8 "HOD lvl 4" 9 "look_away lvl 1" 10 "look_away lvl 2" 11 "look_away lvl 3" 12 "look_away lvl 4" 13 "long_driving lvl1" 14 "long_driving lvl2" 15 "long_driving lvl3" 16 "long_driving lvl4" 17 "smoking lvl 1" 18 "smoking lvl 2" 19 "smoking lvl 3" 20 "smoking lvl 4" 21 "calling lvl1" 22 "calling lvl2" 23 "calling lvl3" 24 "calling lvl4" 25 "driving_erractial lv1" 26 "driving_erractial lv2" 27 "driving_erractial lv3" 28 "driving_erractial lv4" 29 "Reserved" 30 "Reserved" 31 "Reserved";
VAL_ 1076 ADAS_DMS_DRIVER_DETECTION 0 "Driver is not registered" 1 "Driver is not detected due to head position" 2 "Driver is not detected due to sun glass wearing" 3 "Driver is not detected due to  mask wearing" 4 "Identification Success" 5 "reserved" 6 "reserved" 7 "Reserved";
VAL_ 1076 ADAS_DMS_DRIVER_Status_BAR 0 "Driver not ready level 4" 1 "Driver not ready level 3" 2 "Driver not ready level 2" 3 "Driver not ready level 1" 4 "Driver ready";
VAL_ 1077 BCM_SCM_BC_Button 0 "Button not Pressed" 1 "Short Press" 2 "Long Press" 3 "Signal invalid";
VAL_ 1078 MHU_TELStatus 0 "Incomming" 1 "Outgoing" 2 "Connect" 3 "End" 4 "Reserved" 5 "Reserved" 6 "Reserved" 7 "Signal invalid";
VAL_ 1078 MHU_MUTEStatus 0 "MUTE OFF" 1 "MUTE ON" 2 "Reserved" 3 "Signal invalid";
VAL_ 1078 MHU_TEL_source 0 "Bluetooth" 1 "Android Auto" 2 "Carplay" 3 "T-BOX" 4 "VNC" 5 "Reserved" 6 "Reserved" 7 "Signal Invalid";
VAL_ 1080 EDS_FailGrade_ERR_FWD 0 "No fault" 1 "First-Level warning" 2 "Second Fault Limited power" 3 "Third Fault Limp" 4 "Forth Fault, ZeroTorque" 5 "Fifth Fault, Delayed power off" 6 "Invaild" 7 "Invaild";
VAL_ 1080 EDS_MotOverTempAlarm_FWD 0 "Normal" 1 "Error";
VAL_ 1080 EDS_MotOverTempFault_FWD 0 "Normal" 1 "Error";
VAL_ 1080 EDS_MotTempSenFault_FWD 0 "Normal" 1 "Error";
VAL_ 1080 EDS_EDSOverTempUFault_FWD 0 "Normal" 1 "Error";
VAL_ 1080 EDS_EDSOverTempVFault_FWD 0 "Normal" 1 "Error";
VAL_ 1080 EDS_EDSOverTempWFault_FWD 0 "Normal" 1 "Error";
VAL_ 1080 EDS_EDSOverTempAlarm_FWD 0 "Normal" 1 "Error";
VAL_ 1080 EDS_TCoolantOvHi_FWD 0 "Normal" 1 "Error";
VAL_ 1080 EDS_EDSTempCmpAlarm_FWD 0 "Normal" 1 "Error";
VAL_ 1080 EDS_EDSPhaOvCurentHWFault_FWD 0 "Normal" 1 "Error";
VAL_ 1080 EDS_EDSphaOffCalFault_FWD 0 "Normal" 1 "Error";
VAL_ 1080 EDS_EDSOverIdcLnkAlarm_FWD 0 "Normal" 1 "Error";
VAL_ 1080 EDS_EDSHVOverVoltageAlarm_FWD 0 "Normal" 1 "Error";
VAL_ 1080 EDS_EDSHVOverVoltageFault_FWD 0 "Normal" 1 "Error";
VAL_ 1080 EDS_EDSHVUnderVoltageAlarm_FWD 0 "Normal" 1 "Error";
VAL_ 1080 EDS_EDSHVUnderVoltageFault_FWD 0 "Normal" 1 "Error";
VAL_ 1080 EDS_RunToDischaErr_FWD 0 "Normal" 1 "Error";
VAL_ 1080 EDS_12VOverVoltageAlarm_FWD 0 "Normal" 1 "Error";
VAL_ 1080 EDS_12VUnderVoltageAlarm_FWD 0 "Normal" 1 "Error";
VAL_ 1080 EDS_MotOverAlarm_FWD 0 "Normal" 1 "Error";
VAL_ 1080 EDS_MotOverFault_FWD 0 "Normal" 1 "Error";
VAL_ 1080 EDS_ResolverOffsetAngle_FWD 0 "Normal" 1 "Error";
VAL_ 1081 EDS_FailGrade_ERR_RWD 0 "No fault" 1 "First-Level warning" 2 "Second Fault Limited power" 3 "Third Fault, Limp" 4 "Forth Fault, ZeroTorque" 5 "Fifth Fault, Delayed power off" 6 "Invaild" 7 "Invaild";
VAL_ 1081 EDS_MotOverTempAlarm_RWD 0 "Normal" 1 "Error";
VAL_ 1081 EDS_MotOverTempFault_RWD 0 "Normal" 1 "Error";
VAL_ 1081 EDS_MotTempSenFault_RWD 0 "Normal" 1 "Error";
VAL_ 1081 EDS_EDSOverTempUFault_RWD 0 "Normal" 1 "Error";
VAL_ 1081 EDS_EDSOverTempVFault_RWD 0 "Normal" 1 "Error";
VAL_ 1081 EDS_EDSOverTempWFault_RWD 0 "Normal" 1 "Error";
VAL_ 1081 EDS_EDSOverTempAlarm_RWD 0 "Normal" 1 "Error";
VAL_ 1081 EDS_TCoolantOvHi_RWD 0 "Normal" 1 "Error";
VAL_ 1081 EDS_EDSTempCmpAlarm_RWD 0 "Normal" 1 "Error";
VAL_ 1081 EDS_EDSPhaOvCurentHWFault_RWD 0 "Normal" 1 "Error";
VAL_ 1081 EDS_EDSphaOffCalFault_RWD 0 "Normal" 1 "Error";
VAL_ 1081 EDS_EDSOverIdcLnkAlarm_RWD 0 "Normal" 1 "Error";
VAL_ 1081 EDS_EDSHVOverVoltageAlarm_RWD 0 "Normal" 1 "Error";
VAL_ 1081 EDS_EDSHVOverVoltageFault_RWD 0 "Normal" 1 "Error";
VAL_ 1081 EDS_EDSHVUnderVoltageAlarm_RWD 0 "Normal" 1 "Error";
VAL_ 1081 EDS_EDSHVUnderVoltageFault_RWD 0 "Normal" 1 "Error";
VAL_ 1081 EDS_RunToDischaErr_RWD 0 "Normal" 1 "Error";
VAL_ 1081 EDS_12VOverVoltageAlarm_RWD 0 "Normal" 1 "Error";
VAL_ 1081 EDS_12VUnderVoltageAlarm_RWD 0 "Normal" 1 "Error";
VAL_ 1081 EDS_MotOverAlarm_RWD 0 "Normal" 1 "Error";
VAL_ 1081 EDS_MotOverFault_RWD 0 "Normal" 1 "Error";
VAL_ 1081 EDS_ResolverOffsetAngle_RWD 0 "Normal" 1 "Error";
VAL_ 1082 VCU_BrakeRegenMode 0 "HIGH" 1 "MID" 2 "LOW" 3 "OFF";
VAL_ 1082 VCU_CreepDisable_stt 0 "Enable" 1 "Disable";
VAL_ 1082 VCU_Charging_Authen_stt 0 "Not authencating" 1 "Authenticating" 2 "Authen success" 3 "Authen failed" 4 "Forbidden vehicle" 5 "reserved" 6 "reserved" 7 "reserved";
VAL_ 1082 VCU_ChgGun_BadConn_stt 0 "No error" 1 "Bad connection";
VAL_ 1082 VCU_ChgPort_Open_stt 0 "Closed" 1 "Opening";
VAL_ 1082 VCU_Regen_available 0 "Not available" 1 "Available" 2 "Regen limit" 3 "Regen faut";
VAL_ 1082 VCU_VehChg_STS 0 "Charging not in progress and gun not plug-in" 1 "Charging in progress" 2 "Charging complete" 3 "Charge fault" 4 "Gun plugged-in, Standby" 5 "Gun plugged-in, Waiting" 6 "Reserved" 7 "Signal Invalid";
VAL_ 1082 VCU_StoppingMode_stt 0 "Off" 1 "CreepMode" 2 "RollMode" 3 "HoldMode" 4 "Reserved" 5 "Reserved" 6 "Reserved" 7 "Reserved";
VAL_ 1082 VCU_AutoP_Feedback 0 "ON" 1 "OFF" 2 "Reserved" 3 "Signal Invalid";
VAL_ 1082 VCU_ChgGun_Status 0 "Charging gun not plugged" 1 "Locked" 2 "Released" 3 "Error due to plug voltage is higher than 60V." 4 "Error due to electrical failure of lock motor drive pins." 5 "Error due to electrical failure of lock feedback pins" 6 "Error plug lock feedback is received as error from BSW" 7 "Invalid";
VAL_ 1082 VCU_ChgPort_Lock_stt 0 "Locked" 1 "Released";
VAL_ 1082 VCU_Hvbatt_charging_stt 0 "Not charging" 1 "Charging";
VAL_ 1083 MHU_SET_SteeringAdjust 0 "OFF" 1 "ON" 2 "No Request" 3 "Restore steering pos";
VAL_ 1084 EASC_SteeringAdjust 0 "OFF" 1 "ON" 2 "Reserved" 3 "Restore steering pos";
VAL_ 1086 MHU_SET_Soundzone 0 "Invalid" 1 "Front" 2 "Rear" 3 "ALL";
VAL_ 1086 MHU_SET_MediaMute 0 "Invalid" 1 "Mute" 2 "Unmute" 3 "Reserved";
VAL_ 1087 MHU_SET_EQType 0 "Flat" 1 "Pop" 2 "Rock" 3 "Jazz" 4 "Classic" 5 "Vocal" 6 "Custom" 15 "Invalid";
VAL_ 1088 AMP_SET_EQType 0 "Flat" 1 "Pop" 2 "Rock" 3 "Jazz" 4 "Classic" 5 "Vocal" 6 "Custom" 15 "Invalid";
VAL_ 1090 WLC_IC_Error 0 "No Error" 1 "Error";
VAL_ 1090 WLC_FAN_Error 0 "No Error" 1 "Error";
VAL_ 1090 WLC_TempSNSR_Error 0 "No Error" 1 "Error";
VAL_ 1090 WLC_Setting_standard 0 "OFF (Disable)" 1 "ON (Enable)" 2 "Default" 3 "Invalid";
VAL_ 1090 Transmit_WLC_situation 0 "Power OFF" 1 "Cellphone reminder" 2 "Charging" 3 "Charging complete" 4 "Wakeup" 5 "Error" 6 "Reserved" 7 "Invalid";
VAL_ 1090 WLC_VehSpeed_Error 0 "No Error" 1 "Error";
VAL_ 1090 WLC_Resp_Error 0 "No Error" 1 "Error";
VAL_ 1090 WLC_FOD_Error 0 "No Error" 1 "Error";
VAL_ 1090 WLC_Curr_Error 0 "No Error" 1 "Error";
VAL_ 1090 WLC_Temp_Error 0 "No Error" 1 "Error";
VAL_ 1091 WLC_IC_Error_2 0 "No Error" 1 "Error";
VAL_ 1091 WLC_FAN_Error_2 0 "No Error" 1 "Error";
VAL_ 1091 WLC_TempSNSR_Error_2 0 "No Error" 1 "Error";
VAL_ 1091 WLC_Setting_standard_2 0 "OFF (Disable)" 1 "ON (Enable)" 2 "Default" 3 "Invalid";
VAL_ 1091 Transmit_WLC_situation_2 0 "Power OFF" 1 "Cellphone reminder" 2 "Charging" 3 "Charging complete" 4 "Wakeup" 5 "Error" 6 "Reserved" 7 "Invalid";
VAL_ 1091 WLC_VehSpeed_Error_2 0 "No Error" 1 "Error";
VAL_ 1091 WLC_Resp_Error_2 0 "No Error" 1 "Error";
VAL_ 1091 WLC_FOD_Error_2 0 "No Error" 1 "Error";
VAL_ 1091 WLC_Curr_Error_2 0 "No Error" 1 "Error";
VAL_ 1091 WLC_Temp_Error_2 0 "No Error" 1 "Error";
VAL_ 1092 MHU_RPParkingstartReq 0 "no request" 1 "request";
VAL_ 1092 MHU_RP_ParkOutModeConfirm 0 "No request" 1 "Perpendicular parking" 2 "parallel parking" 3 "Angled parking";
VAL_ 1092 MHU_RP_ParkOutDircnConfirm 0 "No request" 1 "left" 2 "right";
VAL_ 1092 MHU_RemoteconnectionSts 0 "Disconnect" 1 "Connect";
VAL_ 1092 MHU_RP_FuncMode 0 "No function" 1 "Parking in" 2 "parking out" 3 "drag parking" 4 "Straight in straight out";
VAL_ 1092 MHU_SMParkingstartReq 0 "no request" 1 "request";
VAL_ 1092 MHU_SMParkingControlReq 0 "no request" 1 "request";
VAL_ 1092 MHU_RP_RecoverParking 0 "no request" 1 "request";
VAL_ 1092 MHU_RPStraightParkingDir 0 "-" 1 "forward" 2 "back";
VAL_ 1092 MHU_SM_global_path_Status 0 "not available" 1 "available" 2 "Reserved";
VAL_ 1092 MHU_SM_QuitReq 0 "No request" 1 "request exit" 2 "request exit and flameout";
VAL_ 1092 MHU_RPParkingControlReq 0 "no request" 1 "request";
VAL_ 1092 MHU_RP_QuitReq 0 "no request" 1 "request exit" 2 "request exit and flameout";
VAL_ 1093 RS_Sol_L 254 "HW failure solar sensor" 255 "Signal invalid";
VAL_ 1093 RS_Sol_R 254 "HW failure solar sensor" 255 "Signal invalid";
VAL_ 1093 RS_F_LightSensor 0 "No error" 1 "Light sensor error";
VAL_ 1093 RS_F_HUD_Sensor 0 "No error" 1 "HUD error";
VAL_ 1093 RS_St_LampReq 0 "OFF" 1 "ON" 2 "Reserved" 3 "Invalid";
VAL_ 1093 RS_St_CurrentRain 0 "No rain" 1 "level 1(light rain)" 2 "level 2(moderate rain)" 3 "level 3(heavy rain)" 4 "Reserved" 5 "Reserved" 6 "Reserved" 7 "Signal invalid";
VAL_ 1093 RS_HUD_illuminance 65535 "Invalid";
